VERSION "HNNBNNNYNNNNNNNNNNNNNNNNNNNNNNNNNNNNNNNNNN/4/%%%/4/'%**4NNN///"

NS_ :

BS_:

BU_: AAG BCM1 BCM2 ELV Gateway HDSG IEZS MFG MSBBR SAD SAD2 Schwerpanzer_Zusatz SitzMem_BFS SitzMem_FS SitzMem_HBFS SitzMem_HFS SitzMem_SR3 SpoilerSG TSG_BFS TSG_FS VSG VTS DK_Dummy

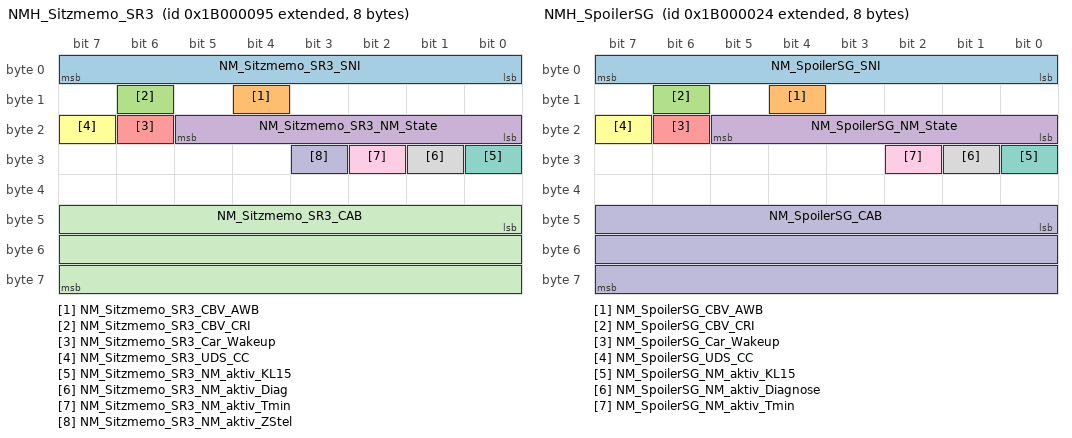
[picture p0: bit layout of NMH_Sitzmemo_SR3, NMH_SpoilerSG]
BO_ 2600468629 NMH_Sitzmemo_SR3: 8 SitzMem_SR3
 SG_ NM_Sitzmemo_SR3_SNI : 0|8@1+ (1,0) [0|255] ""  AAG,BCM1,BCM2,ELV,Gateway,HDSG,IEZS,MFG,MSBBR,SAD,SAD2,SitzMem_BFS,SitzMem_FS,SitzMem_HBFS,SitzMem_HFS,SitzMem_SR3,SpoilerSG,TSG_BFS,TSG_FS,VSG,VTS
 SG_ NM_Sitzmemo_SR3_CBV_AWB : 12|1@1+ (1,0) [0|1] ""  Gateway
 SG_ NM_Sitzmemo_SR3_CBV_CRI : 14|1@1+ (1,0) [0|1] ""  AAG,BCM1,BCM2,ELV,Gateway,HDSG,IEZS,MFG,MSBBR,SAD,SAD2,SitzMem_BFS,SitzMem_FS,SitzMem_HBFS,SitzMem_HFS,SitzMem_SR3,SpoilerSG,TSG_BFS,TSG_FS,VSG,VTS
 SG_ NM_Sitzmemo_SR3_NM_State : 16|6@1+ (1,0) [0|63] "" Vector__XXX
 SG_ NM_Sitzmemo_SR3_Car_Wakeup : 22|1@1+ (1,0) [0|1] ""  Gateway
 SG_ NM_Sitzmemo_SR3_UDS_CC : 23|1@1+ (1,0) [0|1] "" Vector__XXX
 SG_ NM_Sitzmemo_SR3_NM_aktiv_KL15 : 24|1@1+ (1,0) [0|1] "" Vector__XXX
 SG_ NM_Sitzmemo_SR3_NM_aktiv_Diag : 25|1@1+ (1,0) [0|1] "" Vector__XXX
 SG_ NM_Sitzmemo_SR3_NM_aktiv_Tmin : 26|1@1+ (1,0) [0|1] "" Vector__XXX
 SG_ NM_Sitzmemo_SR3_NM_aktiv_ZStel : 27|1@1+ (1,0) [0|1] "" Vector__XXX
 SG_ NM_Sitzmemo_SR3_CAB : 40|24@1+ (1,0) [0|16777215] ""  AAG,BCM1,BCM2,ELV,Gateway,HDSG,IEZS,MFG,MSBBR,SAD,SAD2,SitzMem_BFS,SitzMem_FS,SitzMem_HBFS,SitzMem_HFS,SitzMem_SR3,SpoilerSG,TSG_BFS,TSG_FS,VSG,VTS

BO_ 2600468516 NMH_SpoilerSG: 8 SpoilerSG
 SG_ NM_SpoilerSG_SNI : 0|8@1+ (1,0) [0|255] ""  AAG,BCM1,BCM2,ELV,Gateway,HDSG,IEZS,MFG,MSBBR,SAD,SAD2,SitzMem_BFS,SitzMem_FS,SitzMem_HBFS,SitzMem_HFS,SitzMem_SR3,SpoilerSG,TSG_BFS,TSG_FS,VSG,VTS
 SG_ NM_SpoilerSG_CBV_AWB : 12|1@1+ (1,0) [0|1] "" Vector__XXX
 SG_ NM_SpoilerSG_CBV_CRI : 14|1@1+ (1,0) [0|1] ""  AAG,BCM1,BCM2,ELV,Gateway,HDSG,IEZS,MFG,MSBBR,SAD,SAD2,SitzMem_BFS,SitzMem_FS,SitzMem_HBFS,SitzMem_HFS,SitzMem_SR3,SpoilerSG,TSG_BFS,TSG_FS,VSG,VTS
 SG_ NM_SpoilerSG_NM_State : 16|6@1+ (1,0) [0|63] "" Vector__XXX
 SG_ NM_SpoilerSG_Car_Wakeup : 22|1@1+ (1,0) [0|1] "" Vector__XXX
 SG_ NM_SpoilerSG_UDS_CC : 23|1@1+ (1,0) [0|1] "" Vector__XXX
 SG_ NM_SpoilerSG_NM_aktiv_KL15 : 24|1@1+ (1,0) [0|1] "" Vector__XXX
 SG_ NM_SpoilerSG_NM_aktiv_Diagnose : 25|1@1+ (1,0) [0|1] "" Vector__XXX
 SG_ NM_SpoilerSG_NM_aktiv_Tmin : 26|1@1+ (1,0) [0|1] "" Vector__XXX
 SG_ NM_SpoilerSG_CAB : 40|24@1+ (1,0) [0|16777215] ""  AAG,BCM1,BCM2,ELV,Gateway,HDSG,IEZS,MFG,MSBBR,SAD,SAD2,SitzMem_BFS,SitzMem_FS,SitzMem_HBFS,SitzMem_HFS,SitzMem_SR3,SpoilerSG,TSG_BFS,TSG_FS,VSG,VTS

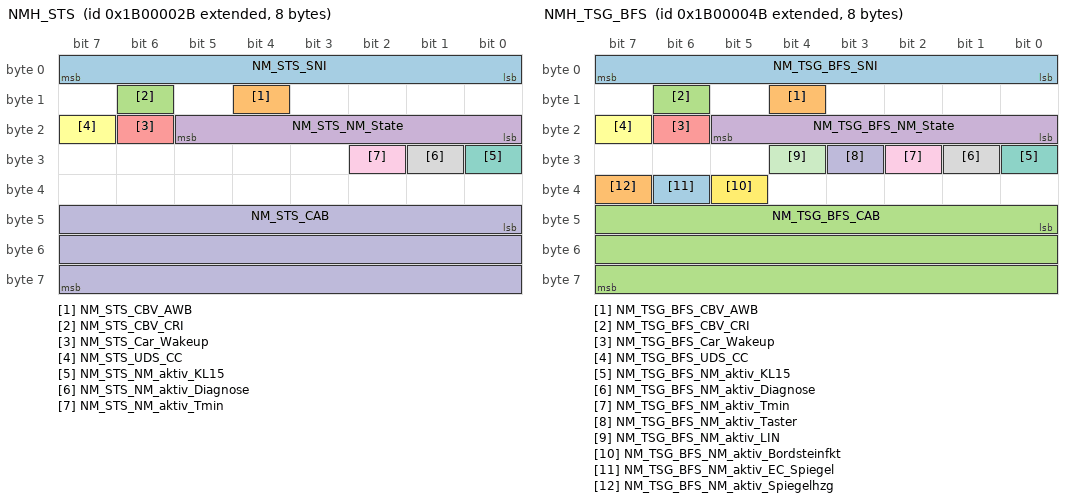
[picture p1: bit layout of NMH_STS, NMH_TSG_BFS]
BO_ 2600468523 NMH_STS: 8 VTS
 SG_ NM_STS_SNI : 0|8@1+ (1,0) [0|255] ""  AAG,BCM1,BCM2,ELV,Gateway,HDSG,IEZS,MFG,MSBBR,SAD,SAD2,SitzMem_BFS,SitzMem_FS,SitzMem_HBFS,SitzMem_HFS,SitzMem_SR3,SpoilerSG,TSG_BFS,TSG_FS,VSG,VTS
 SG_ NM_STS_CBV_AWB : 12|1@1+ (1,0) [0|1] ""  Gateway
 SG_ NM_STS_CBV_CRI : 14|1@1+ (1,0) [0|1] ""  AAG,BCM1,BCM2,ELV,Gateway,HDSG,IEZS,MFG,MSBBR,SAD,SAD2,SitzMem_BFS,SitzMem_FS,SitzMem_HBFS,SitzMem_HFS,SitzMem_SR3,SpoilerSG,TSG_BFS,TSG_FS,VSG,VTS
 SG_ NM_STS_NM_State : 16|6@1+ (1,0) [0|63] "" Vector__XXX
 SG_ NM_STS_Car_Wakeup : 22|1@1+ (1,0) [0|1] ""  Gateway
 SG_ NM_STS_UDS_CC : 23|1@1+ (1,0) [0|1] "" Vector__XXX
 SG_ NM_STS_NM_aktiv_KL15 : 24|1@1+ (1,0) [0|1] "" Vector__XXX
 SG_ NM_STS_NM_aktiv_Diagnose : 25|1@1+ (1,0) [0|1] "" Vector__XXX
 SG_ NM_STS_NM_aktiv_Tmin : 26|1@1+ (1,0) [0|1] "" Vector__XXX
 SG_ NM_STS_CAB : 40|24@1+ (1,0) [0|16777215] ""  AAG,BCM1,BCM2,ELV,Gateway,HDSG,IEZS,MFG,MSBBR,SAD,SAD2,SitzMem_BFS,SitzMem_FS,SitzMem_HBFS,SitzMem_HFS,SitzMem_SR3,SpoilerSG,TSG_BFS,TSG_FS,VSG,VTS

BO_ 2600468555 NMH_TSG_BFS: 8 TSG_BFS
 SG_ NM_TSG_BFS_SNI : 0|8@1+ (1,0) [0|255] ""  AAG,BCM1,BCM2,ELV,Gateway,HDSG,IEZS,MFG,MSBBR,SAD,SAD2,SitzMem_BFS,SitzMem_FS,SitzMem_HBFS,SitzMem_HFS,SitzMem_SR3,SpoilerSG,TSG_BFS,TSG_FS,VSG,VTS
 SG_ NM_TSG_BFS_CBV_AWB : 12|1@1+ (1,0) [0|1] ""  Gateway
 SG_ NM_TSG_BFS_CBV_CRI : 14|1@1+ (1,0) [0|1] ""  AAG,BCM1,BCM2,ELV,Gateway,HDSG,IEZS,MFG,MSBBR,SAD,SAD2,SitzMem_BFS,SitzMem_FS,SitzMem_HBFS,SitzMem_HFS,SitzMem_SR3,SpoilerSG,TSG_BFS,TSG_FS,VSG,VTS
 SG_ NM_TSG_BFS_NM_State : 16|6@1+ (1,0) [0|63] "" Vector__XXX
 SG_ NM_TSG_BFS_Car_Wakeup : 22|1@1+ (1,0) [0|1] ""  Gateway
 SG_ NM_TSG_BFS_UDS_CC : 23|1@1+ (1,0) [0|1] "" Vector__XXX
 SG_ NM_TSG_BFS_NM_aktiv_KL15 : 24|1@1+ (1,0) [0|1] "" Vector__XXX
 SG_ NM_TSG_BFS_NM_aktiv_Diagnose : 25|1@1+ (1,0) [0|1] "" Vector__XXX
 SG_ NM_TSG_BFS_NM_aktiv_Tmin : 26|1@1+ (1,0) [0|1] "" Vector__XXX
 SG_ NM_TSG_BFS_NM_aktiv_Taster : 27|1@1+ (1,0) [0|1] "" Vector__XXX
 SG_ NM_TSG_BFS_NM_aktiv_LIN : 28|1@1+ (1,0) [0|1] "" Vector__XXX
 SG_ NM_TSG_BFS_NM_aktiv_Bordsteinfkt : 37|1@1+ (1,0) [0|1] "" Vector__XXX
 SG_ NM_TSG_BFS_NM_aktiv_EC_Spiegel : 38|1@1+ (1,0) [0|1] "" Vector__XXX
 SG_ NM_TSG_BFS_NM_aktiv_Spiegelhzg : 39|1@1+ (1,0) [0|1] "" Vector__XXX
 SG_ NM_TSG_BFS_CAB : 40|24@1+ (1,0) [0|16777215] ""  AAG,BCM1,BCM2,ELV,Gateway,HDSG,IEZS,MFG,MSBBR,SAD,SAD2,SitzMem_BFS,SitzMem_FS,SitzMem_HBFS,SitzMem_HFS,SitzMem_SR3,SpoilerSG,TSG_BFS,TSG_FS,VSG,VTS

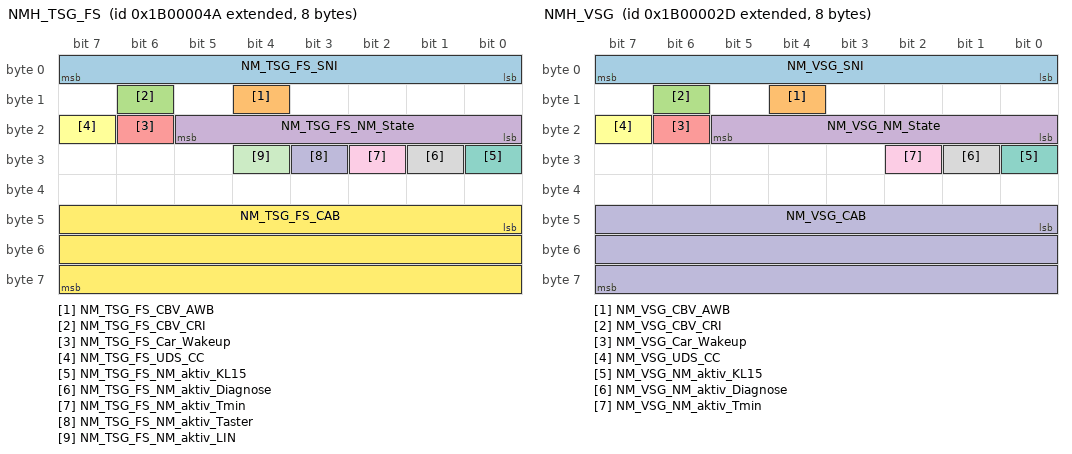
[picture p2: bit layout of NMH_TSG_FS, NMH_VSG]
BO_ 2600468554 NMH_TSG_FS: 8 TSG_FS
 SG_ NM_TSG_FS_SNI : 0|8@1+ (1,0) [0|255] ""  AAG,BCM1,BCM2,ELV,Gateway,HDSG,IEZS,MFG,MSBBR,SAD,SAD2,SitzMem_BFS,SitzMem_FS,SitzMem_HBFS,SitzMem_HFS,SitzMem_SR3,SpoilerSG,TSG_BFS,TSG_FS,VSG,VTS
 SG_ NM_TSG_FS_CBV_AWB : 12|1@1+ (1,0) [0|1] ""  Gateway
 SG_ NM_TSG_FS_CBV_CRI : 14|1@1+ (1,0) [0|1] ""  AAG,BCM1,BCM2,ELV,Gateway,HDSG,IEZS,MFG,MSBBR,SAD,SAD2,SitzMem_BFS,SitzMem_FS,SitzMem_HBFS,SitzMem_HFS,SitzMem_SR3,SpoilerSG,TSG_BFS,TSG_FS,VSG,VTS
 SG_ NM_TSG_FS_NM_State : 16|6@1+ (1,0) [0|63] "" Vector__XXX
 SG_ NM_TSG_FS_Car_Wakeup : 22|1@1+ (1,0) [0|1] ""  Gateway
 SG_ NM_TSG_FS_UDS_CC : 23|1@1+ (1,0) [0|1] "" Vector__XXX
 SG_ NM_TSG_FS_NM_aktiv_KL15 : 24|1@1+ (1,0) [0|1] "" Vector__XXX
 SG_ NM_TSG_FS_NM_aktiv_Diagnose : 25|1@1+ (1,0) [0|1] "" Vector__XXX
 SG_ NM_TSG_FS_NM_aktiv_Tmin : 26|1@1+ (1,0) [0|1] "" Vector__XXX
 SG_ NM_TSG_FS_NM_aktiv_Taster : 27|1@1+ (1,0) [0|1] "" Vector__XXX
 SG_ NM_TSG_FS_NM_aktiv_LIN : 28|1@1+ (1,0) [0|1] "" Vector__XXX
 SG_ NM_TSG_FS_CAB : 40|24@1+ (1,0) [0|16777215] ""  AAG,BCM1,BCM2,ELV,Gateway,HDSG,IEZS,MFG,MSBBR,SAD,SAD2,SitzMem_BFS,SitzMem_FS,SitzMem_HBFS,SitzMem_HFS,SitzMem_SR3,SpoilerSG,TSG_BFS,TSG_FS,VSG,VTS

BO_ 2600468525 NMH_VSG: 8 VSG
 SG_ NM_VSG_SNI : 0|8@1+ (1,0) [0|255] ""  AAG,BCM1,BCM2,ELV,Gateway,HDSG,IEZS,MFG,MSBBR,SAD,SAD2,SitzMem_BFS,SitzMem_FS,SitzMem_HBFS,SitzMem_HFS,SitzMem_SR3,SpoilerSG,TSG_BFS,TSG_FS,VSG,VTS
 SG_ NM_VSG_CBV_AWB : 12|1@1+ (1,0) [0|1] ""  Gateway
 SG_ NM_VSG_CBV_CRI : 14|1@1+ (1,0) [0|1] ""  AAG,BCM1,BCM2,ELV,Gateway,HDSG,IEZS,MFG,MSBBR,SAD,SAD2,SitzMem_BFS,SitzMem_FS,SitzMem_HBFS,SitzMem_HFS,SitzMem_SR3,SpoilerSG,TSG_BFS,TSG_FS,VSG,VTS
 SG_ NM_VSG_NM_State : 16|6@1+ (1,0) [0|63] "" Vector__XXX
 SG_ NM_VSG_Car_Wakeup : 22|1@1+ (1,0) [0|1] ""  Gateway
 SG_ NM_VSG_UDS_CC : 23|1@1+ (1,0) [0|1] "" Vector__XXX
 SG_ NM_VSG_NM_aktiv_KL15 : 24|1@1+ (1,0) [0|1] "" Vector__XXX
 SG_ NM_VSG_NM_aktiv_Diagnose : 25|1@1+ (1,0) [0|1] "" Vector__XXX
 SG_ NM_VSG_NM_aktiv_Tmin : 26|1@1+ (1,0) [0|1] "" Vector__XXX
 SG_ NM_VSG_CAB : 40|24@1+ (1,0) [0|16777215] ""  AAG,BCM1,BCM2,ELV,Gateway,HDSG,IEZS,MFG,MSBBR,SAD,SAD2,SitzMem_BFS,SitzMem_FS,SitzMem_HBFS,SitzMem_HFS,SitzMem_SR3,SpoilerSG,TSG_BFS,TSG_FS,VSG,VTS

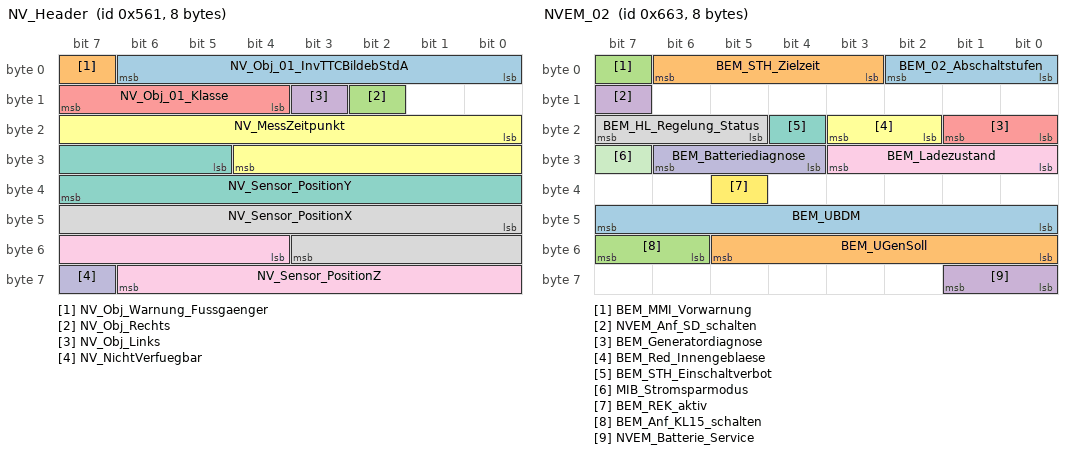
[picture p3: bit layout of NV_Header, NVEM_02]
BO_ 1377 NV_Header: 8 Gateway
 SG_ NV_Obj_01_InvTTCBildebStdA : 0|7@1+ (0.0625,0) [0|7.875] "Unit_Hertz" Vector__XXX
 SG_ NV_Obj_Warnung_Fussgaenger : 7|1@1+ (1,0) [0|1] "" Vector__XXX
 SG_ NV_Obj_Rechts : 10|1@1+ (1,0) [0|1] ""  BCM1
 SG_ NV_Obj_Links : 11|1@1+ (1,0) [0|1] ""  BCM1
 SG_ NV_Obj_01_Klasse : 12|4@1+ (1,0) [0|15] ""  BCM1
 SG_ NV_MessZeitpunkt : 16|13@1+ (0.001,0) [0|8.19] "Unit_Secon" Vector__XXX
 SG_ NV_Sensor_PositionY : 29|11@1+ (0.001,-1) [-1|1.046] "Unit_Meter" Vector__XXX
 SG_ NV_Sensor_PositionX : 40|12@1+ (0.001,1) [1|5.094] "Unit_Meter" Vector__XXX
 SG_ NV_Sensor_PositionZ : 52|11@1+ (0.001,0) [0|2.046] "Unit_Meter" Vector__XXX
 SG_ NV_NichtVerfuegbar : 63|1@1+ (1,0) [0|1] "" Vector__XXX

BO_ 1635 NVEM_02: 8 Gateway
 SG_ BEM_02_Abschaltstufen : 0|3@1+ (1,0) [0|7] ""  AAG,BCM1,BCM2,HDSG,IEZS,MFG,SAD,SAD2,SitzMem_BFS,SitzMem_FS,SitzMem_HBFS,SitzMem_HFS,SitzMem_SR3,SpoilerSG,TSG_BFS,TSG_FS,VSG,VTS
 SG_ BEM_STH_Zielzeit : 3|4@1+ (5,0) [0|60] "Unit_Minut" Vector__XXX
 SG_ BEM_MMI_Vorwarnung : 7|1@1+ (1,0) [0|1] "" Vector__XXX
 SG_ NVEM_Anf_SD_schalten : 15|1@1+ (1,0) [0|1] ""  BCM1
 SG_ BEM_Generatordiagnose : 16|2@1+ (1,0) [0|3] ""  MFG
 SG_ BEM_Red_Innengeblaese : 18|2@1+ (1,0) [0|3] ""  MFG
 SG_ BEM_STH_Einschaltverbot : 20|1@1+ (1,0) [0|1] ""  VTS
 SG_ BEM_HL_Regelung_Status : 21|3@1+ (1,0) [0|7] ""  AAG,BCM1
 SG_ BEM_Ladezustand : 24|4@1+ (10,0) [0|100] "Unit_PerCent" Vector__XXX
 SG_ BEM_Batteriediagnose : 28|3@1+ (1,0) [0|7] "" Vector__XXX
 SG_ MIB_Stromsparmodus : 31|1@1+ (1,0) [0|1] "" Vector__XXX
 SG_ BEM_REK_aktiv : 37|1@1+ (1,0) [0|1] "" Vector__XXX
 SG_ BEM_UBDM : 40|8@1+ (0.05,5) [5.05|17.7] "Unit_Volt"  BCM2
 SG_ BEM_UGenSoll : 48|6@1+ (0.1,10.6) [10.6|16] "Unit_Volt" Vector__XXX
 SG_ BEM_Anf_KL15_schalten : 54|2@1+ (1,0) [0|3] ""  BCM2
 SG_ NVEM_Batterie_Service : 56|2@1+ (1,0) [0|3] "" Vector__XXX

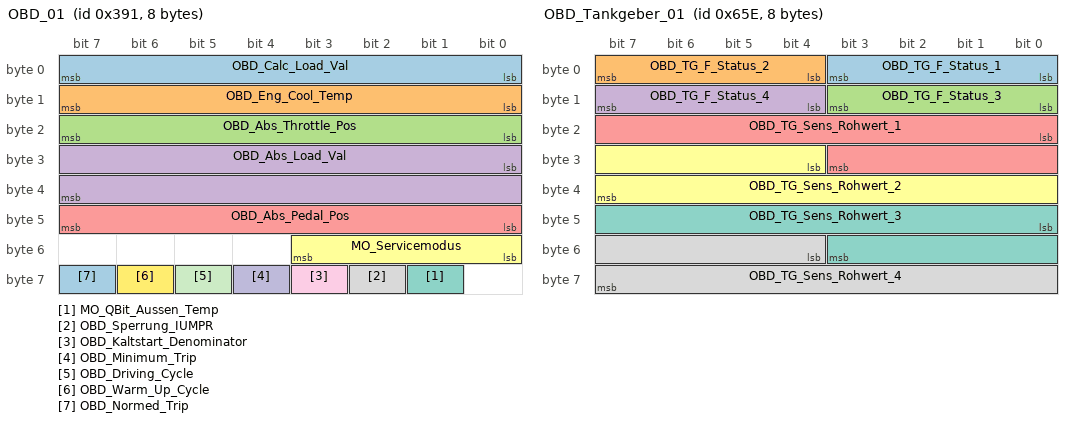
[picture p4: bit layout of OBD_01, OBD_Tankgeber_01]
BO_ 913 OBD_01: 8 Gateway
 SG_ OBD_Calc_Load_Val : 0|8@1+ (0.392156862745098,0) [0|100] "Unit_PerCent" Vector__XXX
 SG_ OBD_Eng_Cool_Temp : 8|8@1+ (1,-40) [-40|215] "Unit_DegreCelsi" Vector__XXX
 SG_ OBD_Abs_Throttle_Pos : 16|8@1+ (0.392156862745098,0) [0|100] "Unit_PerCent" Vector__XXX
 SG_ OBD_Abs_Load_Val : 24|16@1+ (0.392156862745098,0) [0|25700] "Unit_PerCent" Vector__XXX
 SG_ OBD_Abs_Pedal_Pos : 40|8@1+ (0.392156862745098,0) [0|100] "Unit_PerCent" Vector__XXX
 SG_ MO_Servicemodus : 48|4@1+ (1,0) [0|15] "" Vector__XXX
 SG_ MO_QBit_Aussen_Temp : 57|1@1+ (1,0) [0|1] "" Vector__XXX
 SG_ OBD_Sperrung_IUMPR : 58|1@1+ (1,0) [0|1] "" Vector__XXX
 SG_ OBD_Kaltstart_Denominator : 59|1@1+ (1,0) [0|1] "" Vector__XXX
 SG_ OBD_Minimum_Trip : 60|1@1+ (1,0) [0|1] "" Vector__XXX
 SG_ OBD_Driving_Cycle : 61|1@1+ (1,0) [0|1] "" Vector__XXX
 SG_ OBD_Warm_Up_Cycle : 62|1@1+ (1,0) [0|1] "" Vector__XXX
 SG_ OBD_Normed_Trip : 63|1@1+ (1,0) [0|1] "" Vector__XXX

BO_ 1630 OBD_Tankgeber_01: 8 BCM2
 SG_ OBD_TG_F_Status_1 : 0|4@1+ (1,0) [0|15] ""  Gateway
 SG_ OBD_TG_F_Status_2 : 4|4@1+ (1,0) [0|15] ""  Gateway
 SG_ OBD_TG_F_Status_3 : 8|4@1+ (1,0) [0|15] ""  Gateway
 SG_ OBD_TG_F_Status_4 : 12|4@1+ (1,0) [0|15] ""  Gateway
 SG_ OBD_TG_Sens_Rohwert_1 : 16|12@1+ (0.5,0) [0|2047.5] "Unit_Ohm"  Gateway
 SG_ OBD_TG_Sens_Rohwert_2 : 28|12@1+ (0.5,0) [0|2047.5] "Unit_Ohm"  Gateway
 SG_ OBD_TG_Sens_Rohwert_3 : 40|12@1+ (0.5,0) [0|2047.5] "Unit_Ohm"  Gateway
 SG_ OBD_TG_Sens_Rohwert_4 : 52|12@1+ (0.5,0) [0|2047.5] "Unit_Ohm"  Gateway

BO_ 2549875271 OBDC_AAG_Req: 8 Gateway
 SG_ OBDC_AAG_Req_Data : 0|64@1+ (1,0) [0|1.84467440737096E+019] ""  AAG

BO_ 2550006343 OBDC_AAG_Resp: 8 AAG
 SG_ OBDC_AAG_Resp_Data : 0|64@1+ (1,0) [0|1.84467440737096E+019] ""  Gateway

BO_ 2549875214 OBDC_BCM1_Req: 8 Gateway
 SG_ OBDC_BCM1_Req_Data : 0|64@1+ (1,0) [0|1.84467440737096E+019] ""  BCM1

BO_ 2550006286 OBDC_BCM1_Resp: 8 BCM1
 SG_ OBDC_BCM1_Resp_Data : 0|64@1+ (1,0) [0|1.84467440737096E+019] ""  Gateway

BO_ 2549875339 OBDC_BCM2_Req: 8 Gateway
 SG_ OBDC_BCM2_Req_Data : 0|64@1+ (1,0) [0|1.84467440737096E+019] ""  BCM2

BO_ 2550006411 OBDC_BCM2_Resp: 8 BCM2
 SG_ OBDC_BCM2_Resp_Data : 0|64@1+ (1,0) [0|1.84467440737096E+019] ""  Gateway

BO_ 2549875249 OBDC_ELV_Req: 8 Gateway
 SG_ OBDC_ELV_Req_Data : 0|64@1+ (1,0) [0|1.84467440737096E+019] ""  ELV

BO_ 2550006321 OBDC_ELV_Resp: 8 ELV
 SG_ OBDC_ELV_Resp_Data : 0|64@1+ (1,0) [0|1.84467440737096E+019] ""  Gateway

BO_ 2549875235 OBDC_HDSG_Req: 8 Gateway
 SG_ OBDC_HDSG_Req_Data : 0|64@1+ (1,0) [0|1.84467440737096E+019] ""  HDSG

BO_ 2550006307 OBDC_HDSG_Resp: 8 HDSG
 SG_ OBDC_HDSG_Resp_Data : 0|64@1+ (1,0) [0|1.84467440737096E+019] ""  Gateway

BO_ 2549875250 OBDC_Kessy_Req: 8 Gateway
 SG_ OBDC_Kessy_Req_Data : 0|64@1+ (1,0) [0|1.84467440737096E+019] ""  IEZS

BO_ 2550006322 OBDC_Kessy_Resp: 8 IEZS
 SG_ OBDC_Kessy_Resp_Data : 0|64@1+ (1,0) [0|1.84467440737096E+019] ""  Gateway

BO_ 2549875330 OBDC_LCM_L_Req: 8 Gateway
 SG_ OBDC_LCM_L_Req_Data : 0|64@1+ (1,0) [0|1.84467440737096E+019] ""  BCM1

BO_ 2550006402 OBDC_LCM_L_Resp: 8 BCM1
 SG_ OBDC_LCM_L_Resp_Data : 0|64@1+ (1,0) [0|1.84467440737096E+019] ""  Gateway

BO_ 2549875331 OBDC_LCM_R_Req: 8 Gateway
 SG_ OBDC_LCM_R_Req_Data : 0|64@1+ (1,0) [0|1.84467440737096E+019] ""  BCM1

BO_ 2550006403 OBDC_LCM_R_Resp: 8 BCM1
 SG_ OBDC_LCM_R_Resp_Data : 0|64@1+ (1,0) [0|1.84467440737096E+019] ""  Gateway

BO_ 2549875350 OBDC_LED_LM_L_Req: 8 Gateway
 SG_ OBDC_LED_LM_L_Req_Data : 0|64@1+ (1,0) [0|1.84467440737096E+019] ""  BCM1

BO_ 2550006422 OBDC_LED_LM_L_Resp: 8 BCM1
 SG_ OBDC_LED_LM_L_Resp_Data : 0|64@1+ (1,0) [0|1.84467440737096E+019] ""  Gateway

BO_ 2549875351 OBDC_LED_LM_R_Req: 8 Gateway
 SG_ OBDC_LED_LM_R_Req_Data : 0|64@1+ (1,0) [0|1.84467440737096E+019] ""  BCM1

BO_ 2550006423 OBDC_LED_LM_R_Resp: 8 BCM1
 SG_ OBDC_LED_LM_R_Resp_Data : 0|64@1+ (1,0) [0|1.84467440737096E+019] ""  Gateway

BO_ 2549875244 OBDC_MFG_Req: 8 Gateway
 SG_ OBDC_MFG_Req_Data : 0|64@1+ (1,0) [0|1.84467440737096E+019] ""  MFG

BO_ 2550006316 OBDC_MFG_Resp: 8 MFG
 SG_ OBDC_MFG_Resp_Data : 0|64@1+ (1,0) [0|1.84467440737096E+019] ""  Gateway

BO_ 2549875360 OBDC_SAD2_Req: 8 Gateway
 SG_ OBDC_SAD2_Req_Data : 0|64@1+ (1,0) [0|1.84467440737096E+019] ""  SAD2

BO_ 2550006432 OBDC_SAD2_Resp: 8 SAD2
 SG_ OBDC_SAD2_Resp_Data : 0|64@1+ (1,0) [0|1.84467440737096E+019] ""  Gateway

BO_ 2549875332 OBDC_SAD_Req: 8 Gateway
 SG_ OBDC_SAD_Req_Data : 0|64@1+ (1,0) [0|1.84467440737096E+019] ""  SAD

BO_ 2550006404 OBDC_SAD_Resp: 8 SAD
 SG_ OBDC_SAD_Resp_Data : 0|64@1+ (1,0) [0|1.84467440737096E+019] ""  Gateway

BO_ 2549875355 OBDC_SBBR_Req: 8 Gateway
 SG_ OBDC_MSBBR_Req_Data : 0|64@1+ (1,0) [0|1.84467440737096E+019] ""  MSBBR

BO_ 2550006427 OBDC_SBBR_Resp: 8 MSBBR
 SG_ OBDC_MSBBR_Resp_Data : 0|64@1+ (1,0) [0|1.84467440737096E+019] ""  Gateway

BO_ 2549875277 OBDC_Sitzmemo_BFS_Req: 8 Gateway
 SG_ OBDC_Sitzmemo_BFS_Req_Data : 0|64@1+ (1,0) [0|1.84467440737096E+019] ""  SitzMem_BFS

BO_ 2550006349 OBDC_Sitzmemo_BFS_Resp: 8 SitzMem_BFS
 SG_ OBDC_Sitzmemo_BFS_Resp_Data : 0|64@1+ (1,0) [0|1.84467440737096E+019] ""  Gateway

BO_ 2549875276 OBDC_Sitzmemo_FS_Req: 8 Gateway
 SG_ OBDC_Sitzmemo_FS_Req_Data : 0|64@1+ (1,0) [0|1.84467440737096E+019] ""  SitzMem_FS

BO_ 2550006348 OBDC_Sitzmemo_FS_Resp: 8 SitzMem_FS
 SG_ OBDC_Sitzmemo_FS_Resp_Data : 0|64@1+ (1,0) [0|1.84467440737096E+019] ""  Gateway

BO_ 2549875336 OBDC_Sitzmemo_HBFS_Req: 8 Gateway
 SG_ OBDC_Sitzmemo_HBFS_Req_Data : 0|64@1+ (1,0) [0|1.84467440737096E+019] ""  SitzMem_HBFS

BO_ 2550006408 OBDC_Sitzmemo_HBFS_Resp: 8 SitzMem_HBFS
 SG_ OBDC_Sitzmemo_HBFS_Resp_Data : 0|64@1+ (1,0) [0|1.84467440737096E+019] ""  Gateway

BO_ 2549875335 OBDC_Sitzmemo_HFS_Req: 8 Gateway
 SG_ OBDC_Sitzmemo_HFS_Req_Data : 0|64@1+ (1,0) [0|1.84467440737096E+019] ""  SitzMem_HFS

BO_ 2550006407 OBDC_Sitzmemo_HFS_Resp: 8 SitzMem_HFS
 SG_ OBDC_Sitzmemo_HFS_Resp_Data : 0|64@1+ (1,0) [0|1.84467440737096E+019] ""  Gateway

BO_ 2549875349 OBDC_Sitzmemo_SR3_Req: 8 Gateway
 SG_ OBDC_Sitzmemo_SR3_Req_Data : 0|64@1+ (1,0) [0|1.84467440737096E+019] ""  SitzMem_SR3

BO_ 2550006421 OBDC_Sitzmemo_SR3_Resp: 8 SitzMem_SR3
 SG_ OBDC_Sitzmemo_SR3_Resp_Data : 0|64@1+ (1,0) [0|1.84467440737096E+019] ""  Gateway

BO_ 2549875236 OBDC_SpoilerSG_Req: 8 Gateway
 SG_ OBDC_SpoilerSG_Req_Data : 0|64@1+ (1,0) [0|1.84467440737096E+019] ""  SpoilerSG

BO_ 2550006308 OBDC_SpoilerSG_Resp: 8 SpoilerSG
 SG_ OBDC_SpoilerSG_Resp_Data : 0|64@1+ (1,0) [0|1.84467440737096E+019] ""  Gateway

BO_ 2549875243 OBDC_STS_Req: 8 Gateway
 SG_ OBDC_STS_Req_Data : 0|64@1+ (1,0) [0|1.84467440737096E+019] ""  VTS

BO_ 2550006315 OBDC_STS_Resp: 8 VTS
 SG_ OBDC_STS_Resp_Data : 0|64@1+ (1,0) [0|1.84467440737096E+019] ""  Gateway

BO_ 2549875275 OBDC_TSG_BT_Req: 8 Gateway
 SG_ OBDC_TSG_BT_Req_Data : 0|64@1+ (1,0) [0|1.84467440737096E+019] ""  TSG_BFS

BO_ 2550006347 OBDC_TSG_BT_Resp: 8 TSG_BFS
 SG_ OBDC_TSG_BT_Resp_Data : 0|64@1+ (1,0) [0|1.84467440737096E+019] ""  Gateway

BO_ 2549875274 OBDC_TSG_FT_Req: 8 Gateway
 SG_ OBDC_TSG_FT_Req_Data : 0|64@1+ (1,0) [0|1.84467440737096E+019] ""  TSG_FS

BO_ 2550006346 OBDC_TSG_FT_Resp: 8 TSG_FS
 SG_ OBDC_TSG_FT_Resp_Data : 0|64@1+ (1,0) [0|1.84467440737096E+019] ""  Gateway

BO_ 2549875263 OBDC_TSG_HBFS_Req: 8 Gateway
 SG_ OBDC_TSG_HBFS_Req_Data : 0|64@1+ (1,0) [0|1.84467440737096E+019] ""  TSG_BFS

BO_ 2550006335 OBDC_TSG_HBFS_Resp: 8 TSG_BFS
 SG_ OBDC_TSG_HBFS_Resp_Data : 0|64@1+ (1,0) [0|1.84467440737096E+019] ""  Gateway

BO_ 2549875262 OBDC_TSG_HFS_Req: 8 Gateway
 SG_ OBDC_TSG_HFS_Req_Data : 0|64@1+ (1,0) [0|1.84467440737096E+019] ""  TSG_FS

BO_ 2550006334 OBDC_TSG_HFS_Resp: 8 TSG_FS
 SG_ OBDC_TSG_HFS_Resp_Data : 0|64@1+ (1,0) [0|1.84467440737096E+019] ""  Gateway

BO_ 2549875245 OBDC_VSG_Req: 8 Gateway
 SG_ OBDC_VSG_Req_Data : 0|64@1+ (1,0) [0|1.84467440737096E+019] ""  VSG

BO_ 2550006317 OBDC_VSG_Resp: 8 VSG
 SG_ OBDC_VSG_Resp_Data : 0|64@1+ (1,0) [0|1.84467440737096E+019] ""  Gateway

BO_ 872 Parkhilfe2_01: 8 Gateway
 SG_ PH2_Visualisierung : 0|3@1+ (1,0) [0|7] ""  BCM1
 SG_ PH2_nachtr_Stopp_An : 12|1@1+ (1,0) [0|1] "" Vector__XXX
 SG_ PH2_Abschaltursache : 13|3@1+ (1,0) [0|7] ""  BCM1
 SG_ PH2_Opt_Anzeige_V_ein : 16|1@1+ (1,0) [0|1] ""  BCM1
 SG_ PH2_Opt_Anzeige_H_ein : 17|1@1+ (1,0) [0|1] ""  BCM1
 SG_ PH2_Opt_Anz_V_Hindernis : 18|1@1+ (1,0) [0|1] ""  BCM1
 SG_ PH2_Opt_Anz_H_Hindernis : 19|1@1+ (1,0) [0|1] ""  BCM1
 SG_ PH2_Tongeber_V_aktiv : 20|1@1+ (1,0) [0|1] "" Vector__XXX
 SG_ PH2_Tongeber_H_aktiv : 21|1@1+ (1,0) [0|1] "" Vector__XXX
 SG_ PH2_Tongeber_mute : 22|1@1+ (1,0) [0|1] "" Vector__XXX
 SG_ PH2_Anf_Audioabsenkung : 23|1@1+ (1,0) [0|1] "" Vector__XXX
 SG_ PH2_Tongeber_H_verfuegbar : 24|1@1+ (1,0) [0|1] "" Vector__XXX
 SG_ PH2_Taster : 28|2@1+ (1,0) [0|3] "" Vector__XXX
 SG_ PH2_Anf_Verdeck : 30|2@1+ (1,0) [0|3] "" Vector__XXX
 SG_ PH2_Frequenz_hinten : 32|4@1+ (1,0) [0|15] "" Vector__XXX
 SG_ PH2_Lautstaerke_hinten : 36|4@1+ (1,0) [0|15] "" Vector__XXX
 SG_ PH2_Frequenz_vorn : 40|4@1+ (1,0) [0|15] "" Vector__XXX
 SG_ PH2_Lautstaerke_vorn : 44|4@1+ (1,0) [0|15] "" Vector__XXX
 SG_ PH2_StartStopp_Info : 49|2@1+ (1,0) [0|3] "" Vector__XXX
 SG_ PH2_Stoermeldung : 52|4@1+ (1,0) [0|15] "" Vector__XXX
 SG_ PH2_defekt : 56|1@1+ (1,0) [0|1] "" Vector__XXX
 SG_ PH2_gestoert : 57|1@1+ (1,0) [0|1] "" Vector__XXX
 SG_ PH2_Systemzustand : 58|3@1+ (1,0) [0|7] ""  AAG,BCM1
 SG_ PH2_Display_Kundenwunsch : 61|2@1+ (1,0) [0|3] "" Vector__XXX
 SG_ APS2_Tongeber_defekt : 63|1@1+ (1,0) [0|1] "" Vector__XXX

BO_ 1175 Parkhilfe_01: 8 BCM1
 SG_ PH_Visualisierung : 0|3@1+ (1,0) [0|7] ""  BCM1,Gateway
 SG_ PDC_Tonausgabe_Front : 4|4@1+ (1,0) [0|15] ""  Gateway
 SG_ PDC_Tonausgabe_Heck : 8|4@1+ (1,0) [0|15] ""  Gateway
 SG_ PH_nachtr_Stopp_Anf : 12|1@1+ (1,0) [0|1] ""  Gateway
 SG_ PH_Abschaltursache : 13|3@1+ (1,0) [0|7] ""  Gateway
 SG_ PH_Opt_Anzeige_V_ein : 16|1@1+ (1,0) [0|1] ""  Gateway
 SG_ PH_Opt_Anzeige_H_ein : 17|1@1+ (1,0) [0|1] ""  Gateway
 SG_ PH_Opt_Anz_V_Hindernis : 18|1@1+ (1,0) [0|1] ""  Gateway
 SG_ PH_Opt_Anz_H_Hindernis : 19|1@1+ (1,0) [0|1] ""  Gateway
 SG_ PH_Tongeber_V_aktiv : 20|1@1+ (1,0) [0|1] ""  Gateway
 SG_ PH_Tongeber_H_aktiv : 21|1@1+ (1,0) [0|1] ""  Gateway
 SG_ PH_Tongeber_mute : 22|1@1+ (1,0) [0|1] ""  Gateway
 SG_ PH_Anf_Audioabsenkung : 23|1@1+ (1,0) [0|1] ""  Gateway
 SG_ PH_Tongeber_H_verfuegbar : 24|1@1+ (1,0) [0|1] ""  Gateway
 SG_ PLA_Anf_Aufschaltung_RVC : 25|1@1+ (1,0) [0|1] ""  Gateway
 SG_ PH_Taster : 28|2@1+ (1,0) [0|3] ""  Gateway
 SG_ PH_Anf_Verdeck : 30|2@1+ (1,0) [0|3] ""  Gateway
 SG_ PH_Frequenz_hinten : 32|4@1+ (1,0) [0|15] ""  Gateway
 SG_ PH_Lautstaerke_hinten : 36|4@1+ (1,0) [0|15] ""  Gateway
 SG_ PH_Frequenz_vorn : 40|4@1+ (1,0) [0|15] ""  Gateway
 SG_ PH_Lautstaerke_vorn : 44|4@1+ (1,0) [0|15] ""  Gateway
 SG_ PH_StartStopp_Info : 49|2@1+ (1,0) [0|3] ""  Gateway
 SG_ PH_Stoermeldung : 52|4@1+ (1,0) [0|15] ""  Gateway
 SG_ PH_defekt : 56|1@1+ (1,0) [0|1] ""  Gateway
 SG_ PH_gestoert : 57|1@1+ (1,0) [0|1] ""  Gateway
 SG_ PH_Systemzustand : 58|3@1+ (1,0) [0|7] ""  AAG,Gateway
 SG_ PH_Display_Kundenwunsch : 61|2@1+ (1,0) [0|3] ""  Gateway

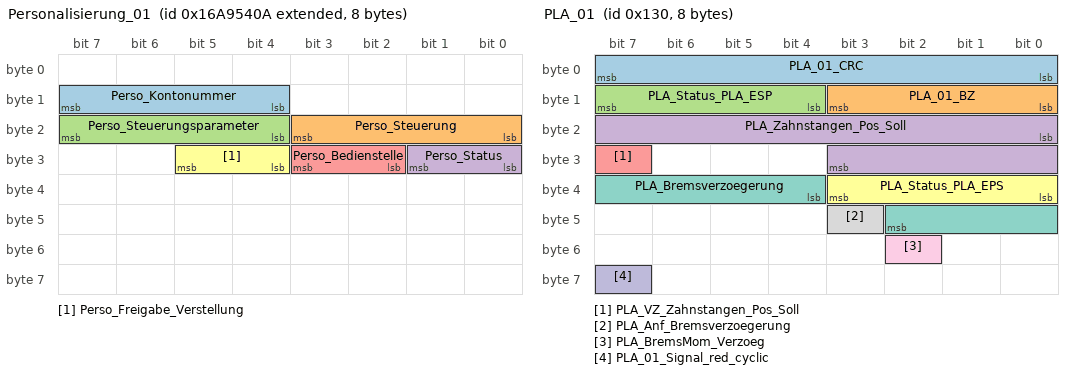
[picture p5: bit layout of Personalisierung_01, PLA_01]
BO_ 2527679498 Personalisierung_01: 8 BCM2
 SG_ Perso_Kontonummer : 12|4@1+ (1,0) [0|15] ""  BCM1,Gateway,TSG_BFS,TSG_FS
 SG_ Perso_Steuerung : 16|4@1+ (1,0) [0|15] ""  BCM1,Gateway,TSG_BFS,TSG_FS
 SG_ Perso_Steuerungsparameter : 20|4@1+ (1,0) [0|15] ""  BCM1,Gateway,TSG_BFS,TSG_FS
 SG_ Perso_Status : 24|2@1+ (1,0) [0|3] ""  BCM1,Gateway,TSG_BFS,TSG_FS
 SG_ Perso_Bedienstelle : 26|2@1+ (1,0) [0|3] ""  Gateway,SitzMem_FS
 SG_ Perso_Freigabe_Verstellung : 28|2@1+ (1,0) [0|3] ""  Gateway,SitzMem_FS

BO_ 304 PLA_01: 8 BCM1
 SG_ PLA_01_CRC : 0|8@1+ (1,0) [0|255] ""  Gateway
 SG_ PLA_01_BZ : 8|4@1+ (1,0) [0|15] ""  Gateway
 SG_ PLA_Status_PLA_ESP : 12|4@1+ (1,0) [0|15] ""  Gateway
 SG_ PLA_Zahnstangen_Pos_Soll : 16|12@1+ (0.02,0) [0|81.86] "Unit_MilliMeter"  Gateway
 SG_ PLA_VZ_Zahnstangen_Pos_Soll : 31|1@1+ (1,0) [0|1] ""  Gateway
 SG_ PLA_Status_PLA_EPS : 32|4@1+ (1,0) [0|15] ""  Gateway
 SG_ PLA_Bremsverzoegerung : 36|7@1+ (0.1,0) [0|12] "Unit_MeterPerSeconSquar"  Gateway
 SG_ PLA_Anf_Bremsverzoegerung : 43|1@1+ (1,0) [0|1] ""  Gateway
 SG_ PLA_BremsMom_Verzoeg : 50|1@1+ (1,0) [0|1] ""  Gateway
 SG_ PLA_01_Signal_red_cyclic : 63|1@1+ (1,0) [0|1] ""  Gateway

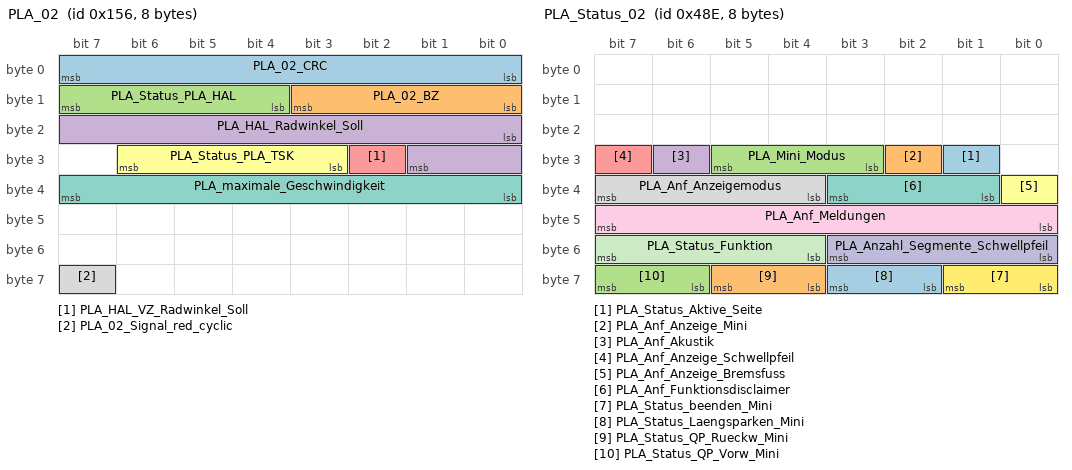
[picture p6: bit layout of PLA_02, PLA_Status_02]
BO_ 342 PLA_02: 8 BCM1
 SG_ PLA_02_CRC : 0|8@1+ (1,0) [0|255] ""  Gateway
 SG_ PLA_02_BZ : 8|4@1+ (1,0) [0|15] ""  Gateway
 SG_ PLA_Status_PLA_HAL : 12|4@1+ (1,0) [0|15] ""  Gateway
 SG_ PLA_HAL_Radwinkel_Soll : 16|10@1+ (0.01,0) [0|10.19] "Unit_DegreOfArc"  Gateway
 SG_ PLA_HAL_VZ_Radwinkel_Soll : 26|1@1+ (1,0) [0|1] ""  Gateway
 SG_ PLA_Status_PLA_TSK : 27|4@1+ (1,0) [0|15] ""  Gateway
 SG_ PLA_maximale_Geschwindigkeit : 32|8@1+ (0.1,0) [0.1|25] "Unit_KiloMeterPerHour"  Gateway
 SG_ PLA_02_Signal_red_cyclic : 63|1@1+ (1,0) [0|1] ""  Gateway

BO_ 1166 PLA_Status_02: 8 BCM1
 SG_ PLA_Status_Aktive_Seite : 25|1@1+ (1,0) [0|1] ""  Gateway
 SG_ PLA_Anf_Anzeige_Mini : 26|1@1+ (1,0) [0|1] ""  Gateway
 SG_ PLA_Mini_Modus : 27|3@1+ (1,0) [0|7] ""  Gateway
 SG_ PLA_Anf_Akustik : 30|1@1+ (1,0) [0|1] ""  Gateway
 SG_ PLA_Anf_Anzeige_Schwellpfeil : 31|1@1+ (1,0) [0|1] ""  Gateway
 SG_ PLA_Anf_Anzeige_Bremsfuss : 32|1@1+ (1,0) [0|1] ""  Gateway
 SG_ PLA_Anf_Funktionsdisclaimer : 33|3@1+ (1,0) [0|7] ""  Gateway
 SG_ PLA_Anf_Anzeigemodus : 36|4@1+ (1,0) [0|15] ""  Gateway
 SG_ PLA_Anf_Meldungen : 40|8@1+ (1,0) [0|255] ""  Gateway
 SG_ PLA_Anzahl_Segmente_Schwellpfeil : 48|4@1+ (1,0) [0|15] ""  Gateway
 SG_ PLA_Status_Funktion : 52|4@1+ (1,0) [0|15] ""  Gateway
 SG_ PLA_Status_beenden_Mini : 56|2@1+ (1,0) [0|3] ""  Gateway
 SG_ PLA_Status_Laengsparken_Mini : 58|2@1+ (1,0) [0|3] ""  Gateway
 SG_ PLA_Status_QP_Rueckw_Mini : 60|2@1+ (1,0) [0|3] ""  Gateway
 SG_ PLA_Status_QP_Vorw_Mini : 62|2@1+ (1,0) [0|3] ""  Gateway

BO_ 319 PreCrash_02: 8 Gateway
 SG_ PreCrash_Charisma_FahrPr : 12|4@1+ (1,0) [0|15] "" Vector__XXX
 SG_ PreCrash_Charisma_Status : 16|2@1+ (1,0) [0|3] "" Vector__XXX
 SG_ PreCrash_Schiebedach_schliessen : 18|1@1+ (1,0) [0|1] ""  SAD,SAD2
 SG_ PreCrash_Fenster_schliessen : 19|1@1+ (1,0) [0|1] ""  TSG_BFS,TSG_FS
 SG_ PreCrash_Blinken : 20|3@1+ (1,0) [0|7] ""  BCM2
 SG_ SC_PreCrash_LED : 29|2@1+ (1,0) [0|3] "" Vector__XXX
 SG_ PreCrash_FS_Pneumatik_ansteuern : 31|1@1+ (1,0) [0|1] ""  BCM1,SitzMem_FS
 SG_ PreCrash_BFS_Pneumatik_ansteuern : 32|1@1+ (1,0) [0|1] ""  BCM1,SitzMem_BFS
 SG_ PreCrash_Fo_Pneumatik_ansteuern : 33|1@1+ (1,0) [0|1] ""  SitzMem_HBFS,SitzMem_HFS
 SG_ PreCrash_FS_Sitzlehne_verfahren : 34|3@1+ (1,0) [0|7] ""  SitzMem_FS
 SG_ PreCrash_BFS_Sitzlehne_verfahren : 37|3@1+ (1,0) [0|7] ""  SitzMem_BFS
 SG_ PreCrash_Fo_Sitzlehne_verfahren : 40|3@1+ (1,0) [0|7] ""  SitzMem_HBFS,SitzMem_HFS
 SG_ PreCrash_FS_KSV_verfahren : 43|4@1+ (1,0) [0|15] ""  SitzMem_FS
 SG_ PreCrash_BFS_KSV_verfahren : 47|4@1+ (1,0) [0|15] ""  SitzMem_BFS
 SG_ PreCrash_Fo_KSV_verfahren : 51|4@1+ (1,0) [0|15] ""  SitzMem_HBFS,SitzMem_HFS
 SG_ SC_PreCrash_Warnung : 56|4@1+ (1,0) [0|15] "" Vector__XXX
 SG_ SC_PreCrash_Texte : 60|4@1+ (1,0) [0|15] "" Vector__XXX

BO_ 1122 PSD_04: 8 Gateway
 SG_ PSD_Segment_ID : 0|6@1+ (1,0) [2|63] ""  BCM1
 SG_ PSD_Vorgaenger_Segment_ID : 6|6@1+ (1,0) [2|63] ""  BCM1
 SG_ PSD_Segmentlaenge : 12|7@1+ (2,0) [0|254] "Unit_Meter"  BCM1
 SG_ PSD_Strassenkategorie : 19|3@1+ (1,0) [0|7] ""  BCM1
 SG_ PSD_Endkruemmung : 22|8@1+ (1,0) [0|254] "Unit_None"  BCM1
 SG_ PSD_Endkruemmung_Vorz : 30|1@1+ (1,0) [0|1] ""  BCM1
 SG_ PSD_Idenditaets_ID : 31|6@1+ (1,0) [2|63] ""  BCM1
 SG_ PSD_ADAS_Qualitaet : 37|1@1+ (1,0) [0|1] ""  BCM1
 SG_ PSD_wahrscheinlichster_Pfad : 38|1@1+ (1,0) [0|1] ""  BCM1
 SG_ PSD_Geradester_Pfad : 39|1@1+ (1,0) [0|1] ""  BCM1
 SG_ PSD_Fahrspuren_Anzahl : 40|3@1+ (1,0) [0|7] ""  BCM1
 SG_ PSD_Bebauung : 43|1@1+ (1,0) [0|1] ""  BCM1
 SG_ PSD_Segment_Komplett : 44|1@1+ (1,0) [0|1] ""  BCM1
 SG_ PSD_Rampe : 45|2@1+ (1,0) [0|3] ""  BCM1
 SG_ PSD_Anfangskruemmung : 47|8@1+ (1,0) [0|254] ""  BCM1
 SG_ PSD_Anfangskruemmung_Vorz : 55|1@1+ (1,0) [0|1] ""  BCM1
 SG_ PSD_Abzweigerichtung : 56|1@1+ (1,0) [0|1] ""  BCM1
 SG_ PSD_Abzweigewinkel : 57|7@1+ (1.417323,0) [0|180.000021] ""  BCM1

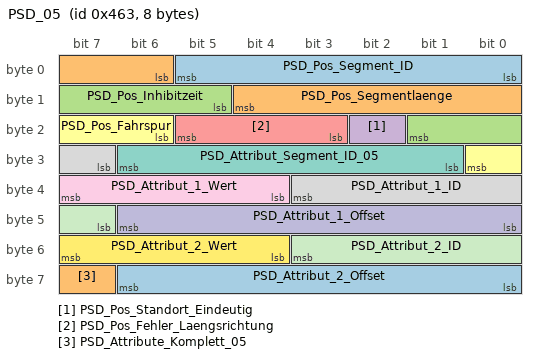
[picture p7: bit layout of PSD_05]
BO_ 1123 PSD_05: 8 Gateway
 SG_ PSD_Pos_Segment_ID : 0|6@1+ (1,0) [2|63] ""  BCM1
 SG_ PSD_Pos_Segmentlaenge : 6|7@1+ (2,0) [0|254] "Unit_Meter"  BCM1
 SG_ PSD_Pos_Inhibitzeit : 13|5@1+ (10,0) [0|310] "Unit_MilliSecon"  BCM1
 SG_ PSD_Pos_Standort_Eindeutig : 18|1@1+ (1,0) [0|1] ""  BCM1
 SG_ PSD_Pos_Fehler_Laengsrichtung : 19|3@1+ (1,0) [0|7] ""  BCM1
 SG_ PSD_Pos_Fahrspur : 22|3@1+ (1,0) [0|7] ""  BCM1
 SG_ PSD_Attribut_Segment_ID_05 : 25|6@1+ (1,0) [2|63] ""  BCM1
 SG_ PSD_Attribut_1_ID : 31|5@1+ (1,0) [1|31] ""  BCM1
 SG_ PSD_Attribut_1_Wert : 36|4@1+ (1,0) [0|15] ""  BCM1
 SG_ PSD_Attribut_1_Offset : 40|7@1+ (2,0) [0|254] "Unit_Meter"  BCM1
 SG_ PSD_Attribut_2_ID : 47|5@1+ (1,0) [1|31] ""  BCM1
 SG_ PSD_Attribut_2_Wert : 52|4@1+ (1,0) [0|15] ""  BCM1
 SG_ PSD_Attribut_2_Offset : 56|7@1+ (2,0) [0|254] "Unit_Meter"  BCM1
 SG_ PSD_Attribute_Komplett_05 : 63|1@1+ (1,0) [0|1] ""  BCM1

BO_ 1124 PSD_06: 8 Gateway
 SG_ PSD_06_Mux M : 0|3@1+ (1,0) [0|7] ""  BCM1
 SG_ PSD_Sys_Segment_ID m0 : 3|6@1+ (1,0) [2|63] ""  BCM1
 SG_ PSD_Attribut_Segment_ID m1 : 3|6@1+ (1,0) [2|63] ""  BCM1
 SG_ PSD_Ges_Segment_ID m2 : 3|6@1+ (1,0) [2|63] ""  BCM1
 SG_ PSD_Baum_Laenge_VZ m3 : 3|1@1+ (1,0) [0|1] ""  BCM1
 SG_ PSD_Steigung_1_Segment_ID m4 : 3|6@1+ (1,0) [2|63] ""  BCM1
 SG_ PSD_Baum_Laenge m3 : 4|25@1+ (1E-005,0) [0|180] "Unit_DegreOfArc"  BCM1
 SG_ PSD_Sys_Laendercode m0 : 9|8@1+ (1,0) [0|255] ""  BCM1
 SG_ PSD_Attribut_3_ID m1 : 9|5@1+ (1,0) [1|31] ""  BCM1
 SG_ PSD_Ges_Offset m2 : 9|7@1+ (2,0) [0|254] "Unit_Meter"  BCM1
 SG_ PSD_Steigung_1_A_Steigung m4 : 9|7@1+ (0.12,0) [0|15] "Unit_PerCent"  BCM1
 SG_ PSD_Attribut_3_Offset m1 : 14|7@1+ (2,0) [0|254] "Unit_Meter"  BCM1
 SG_ PSD_Ges_Geschwindigkeit m2 : 16|5@1+ (1,0) [0|31] ""  BCM1
 SG_ PSD_Steigung_1_A_Vorz m4 : 16|1@1+ (1,0) [0|1] ""  BCM1
 SG_ PSD_Sys_Geschwindigkeit_Einheit m0 : 17|1@1+ (1,0) [0|1] ""  BCM1
 SG_ PSD_Steigung_1_A_Offset m4 : 17|7@1+ (2,0) [0|254] "Unit_Meter"  BCM1
 SG_ PSD_Sys_Verkehrsrichtung m0 : 18|1@1+ (1,0) [0|1] ""  BCM1
 SG_ PSD_Sys_Geometrieguete m0 : 19|2@1+ (1,0) [0|3] ""  BCM1
 SG_ PSD_Sys_Mapmatchingguete m0 : 21|2@1+ (1,0) [0|3] ""  BCM1
 SG_ PSD_Attribut_3_Wert m1 : 21|4@1+ (1,0) [0|15] ""  BCM1
 SG_ PSD_Ges_Typ m2 : 21|2@1+ (1,0) [0|3] ""  BCM1
 SG_ PSD_Sys_Alter_Karte m0 : 23|3@1+ (1,0) [0|7] ""  BCM1
 SG_ PSD_Ges_Spur_Geschw_Begrenzung m2 : 23|6@1+ (1,0) [0|63] ""  BCM1
 SG_ PSD_Steigung_1_B_Steigung m4 : 24|7@1+ (0.12,0) [0|15] "Unit_PerCent"  BCM1
 SG_ PSD_Attribut_4_ID m1 : 25|5@1+ (1,0) [1|31] ""  BCM1
 SG_ PSD_Sys_Zielfuehrung m0 : 26|1@1+ (1,0) [0|1] ""  BCM1
 SG_ PSD_Sys_US_State m0 : 27|6@1+ (1,0) [0|63] ""  BCM1
 SG_ PSD_Ges_Geschwindigkeit_Gespann m2 : 29|2@1+ (1,0) [0|3] ""  BCM1
 SG_ PSD_Baum_Breite_VZ m3 : 29|1@1+ (1,0) [0|1] ""  BCM1
 SG_ PSD_Attribut_4_Wert m1 : 30|4@1+ (1,0) [0|15] ""  BCM1
 SG_ PSD_Baum_Breite m3 : 30|24@1+ (1E-005,0) [0|90] "Unit_DegreOfArc"  BCM1
 SG_ PSD_Ges_Geschwindigkeit_Witter m2 : 31|2@1+ (1,0) [0|3] ""  BCM1
 SG_ PSD_Steigung_1_B_Vorz m4 : 31|1@1+ (1,0) [0|1] ""  BCM1
 SG_ PSD_Steigung_1_B_Offset m4 : 32|7@1+ (2,0) [0|254] "Unit_Meter"  BCM1
 SG_ PSD_Ges_Geschwindigkeit_Tag_Anf m2 : 33|3@1+ (1,0) [0|7] ""  BCM1
 SG_ PSD_Attribut_4_Offset m1 : 34|7@1+ (2,0) [0|254] "Unit_Meter"  BCM1
 SG_ PSD_Ges_Geschwindigkeit_Tag_Ende m2 : 36|3@1+ (1,0) [0|7] ""  BCM1
 SG_ PSD_Ges_Geschwindigkeit_Std_Anf m2 : 39|5@1+ (1,0) [0|24] "Unit_Hours"  BCM1
 SG_ PSD_Steigung_1_Attribute_kompl m4 : 39|1@1+ (1,0) [0|1] ""  BCM1
 SG_ PSD_Steigung_2_Segment_ID m4 : 40|6@1+ (1,0) [2|63] ""  BCM1
 SG_ PSD_Attribut_5_ID m1 : 41|5@1+ (1,0) [1|31] ""  BCM1
 SG_ PSD_Ges_Geschwindigkeit_Std_Ende m2 : 44|5@1+ (1,0) [0|24] "Unit_Hours"  BCM1
 SG_ PSD_Attribut_5_Offset m1 : 46|7@1+ (2,0) [0|254] "Unit_Meter"  BCM1
 SG_ PSD_Steigung_2_Steigung m4 : 46|7@1+ (0.12,0) [0|15] "Unit_PerCent"  BCM1
 SG_ PSD_Ges_Ueberholverbot m2 : 49|2@1+ (1,0) [0|3] ""  BCM1
 SG_ PSD_Ges_Wechselverkehrszeichen m2 : 51|3@1+ (1,0) [0|7] ""  BCM1
 SG_ PSD_Attribut_5_Wert m1 : 53|4@1+ (1,0) [0|15] ""  BCM1
 SG_ PSD_Steigung_2_Vorz m4 : 53|1@1+ (1,0) [0|1] ""  BCM1
 SG_ PSD_Wechselverkehrszeichen_Typ m2 : 54|2@1+ (1,0) [0|3] ""  BCM1
 SG_ PSD_Baum_Ausrichtung m3 : 54|10@1+ (0.3515625,0) [0|359.6484375] "Unit_DegreOfArc"  BCM1
 SG_ PSD_Steigung_2_Offset m4 : 54|7@1+ (2,0) [0|254] "Unit_Meter"  BCM1
 SG_ PSD_Ges_Gesetzlich_Kategorie m2 : 56|3@1+ (1,0) [0|7] ""  BCM1
 SG_ PSD_Attribute_Komplett_06 m1 : 57|1@1+ (1,0) [0|1] ""  BCM1
 SG_ PSD_Ges_Gesetzlich_Zusatz m2 : 59|2@1+ (1,0) [0|3] ""  BCM1
 SG_ PSD_Ges_Verkehrszeichen_Quelle m2 : 61|2@1+ (1,0) [0|3] ""  BCM1
 SG_ PSD_Steigung_2_Attribute_kompl m4 : 61|1@1+ (1,0) [0|1] ""  BCM1
 SG_ PSD_Ges_Attribute_Komplett m2 : 63|1@1+ (1,0) [0|1] ""  BCM1

CM_ SG_ 2600468629 NM_Sitzmemo_SR3_SNI "Source Node-Identifier (SNI) identifiziert den Sender der NM-Botschaft (Knotenadresse) eindeutig im Fahrzeug";
CM_ SG_ 2600468629 NM_Sitzmemo_SR3_CBV_AWB "Das Signal ist zu setzen, wenn das SG aktiv den Bus geweckt hat";
CM_ SG_ 2600468629 NM_Sitzmemo_SR3_CBV_CRI "Das Signal ist dauerhaft gesetzt, wenn das NM-Layout dem neuen NM-Layout für Teilnetzbetrieb entspricht";
CM_ SG_ 2600468629 NM_Sitzmemo_SR3_NM_State "1 = Zustand Repeat Message (<-- Bus-Sleep Mode)
2 = Zustand Repeat Message (<-- Prepare Bus-Sleep Mode)
4 = Zustand Normal Operation (<-- Repeat Message)
8 = Zustand Normal Operation (<-- Ready Sleep)";
CM_ SG_ 2600468629 NM_Sitzmemo_SR3_Car_Wakeup "Car Wakeup (Gateway wertet aus)
";
CM_ SG_ 2600468629 NM_Sitzmemo_SR3_UDS_CC "Funktionseinschränkung aufgrund aktivem UDS-Communication Control; siehe VW80124";
CM_ SG_ 2600468629 NM_Sitzmemo_SR3_NM_aktiv_KL15 "Steuergerät hat KL15-EIN erkannt";
CM_ SG_ 2600468629 NM_Sitzmemo_SR3_NM_aktiv_Diag "Diagnose befindet sich nach VW80124 in einer NonDefaultDiagnostic-Session, z.B. ExtendedDiagnostic-Session";
CM_ SG_ 2600468629 NM_Sitzmemo_SR3_NM_aktiv_Tmin "Mindestaktivzeit ist noch nicht abgelaufen (bei jedem Weckereignis wird die Mindestaktivzeit neu gestartet)";
CM_ SG_ 2600468629 NM_Sitzmemo_SR3_NM_aktiv_ZStel "3. Sitzreihe befindet sich in einer Zwischenstellung";
CM_ SG_ 2600468629 NM_Sitzmemo_SR3_CAB "CAB = Clusteraktivbits";
CM_ BO_ 2600468516 "CAN_NM_PDU MLBevo";
CM_ SG_ 2600468516 NM_SpoilerSG_SNI "Source Node-Identifier (SNI) identifiziert den Sender der NM-Botschaft (Knotenadresse) eindeutig im Fahrzeug";
CM_ SG_ 2600468516 NM_SpoilerSG_CBV_AWB "Das Signal ist zu setzen, wenn das SG aktiv den Bus geweckt hat";
CM_ SG_ 2600468516 NM_SpoilerSG_CBV_CRI "Das Signal ist dauerhaft gesetzt, wenn das NM-Layout dem neuen NM-Layout für Teilnetzbetrieb entspricht";
CM_ SG_ 2600468516 NM_SpoilerSG_NM_State "1 = Zustand Repeat Message (<-- Bus-Sleep Mode)
2 = Zustand Repeat Message (<-- Prepare Bus-Sleep Mode)
4 = Zustand Normal Operation (<-- Repeat Message)
8 = Zustand Normal Operation (<-- Ready Sleep)";
CM_ SG_ 2600468516 NM_SpoilerSG_Car_Wakeup "Car Wakeup (Gateway wertet aus)";
CM_ SG_ 2600468516 NM_SpoilerSG_UDS_CC "Funktionseinschränkung aufgrund aktivem UDS-Communication Control; siehe VW80124";
CM_ SG_ 2600468516 NM_SpoilerSG_NM_aktiv_KL15 "Steuergerät hat KL15-EIN erkannt";
CM_ SG_ 2600468516 NM_SpoilerSG_NM_aktiv_Diagnose "Diagnose befindet sich nach VW80124 in einer NonDefaultDiagnostic-Session, z.B. ExtendedDiagnostic-Session";
CM_ SG_ 2600468516 NM_SpoilerSG_NM_aktiv_Tmin "Mindestaktivzeit ist noch nicht abgelaufen (bei jedem Weckereignis wird die Mindestaktivzeit neu gestartet)";
CM_ SG_ 2600468516 NM_SpoilerSG_CAB "CAB = Clusteraktivbits";
CM_ SG_ 2600468523 NM_STS_SNI "Source Node-Identifier (SNI) identifiziert den Sender der NM-Botschaft (Knotenadresse) eindeutig im Fahrzeug";
CM_ SG_ 2600468523 NM_STS_CBV_AWB "Das Signal ist zu setzen, wenn das SG aktiv den Bus geweckt hat";
CM_ SG_ 2600468523 NM_STS_CBV_CRI "Das Signal ist dauerhaft gesetzt, wenn das NM-Layout dem neuen NM-Layout für Teilnetzbetrieb entspricht";
CM_ SG_ 2600468523 NM_STS_NM_State "1 = Zustand Repeat Message (<-- Bus-Sleep Mode)
2 = Zustand Repeat Message (<-- Prepare Bus-Sleep Mode)
4 = Zustand Normal Operation (<-- Repeat Message)
8 = Zustand Normal Operation (<-- Ready Sleep)";
CM_ SG_ 2600468523 NM_STS_Car_Wakeup "Car Wakeup (Gateway wertet aus)";
CM_ SG_ 2600468523 NM_STS_UDS_CC "Funktionseinschränkung aufgrund aktivem UDS-Communication Control; siehe VW80124";
CM_ SG_ 2600468523 NM_STS_NM_aktiv_KL15 "Steuergerät hat KL15-EIN erkannt";
CM_ SG_ 2600468523 NM_STS_NM_aktiv_Diagnose "Diagnose befindet sich nach VW80124 in einer NonDefaultDiagnostic-Session, z.B. ExtendedDiagnostic-Session";
CM_ SG_ 2600468523 NM_STS_NM_aktiv_Tmin "Mindestaktivzeit ist noch nicht abgelaufen (bei jedem Weckereignis wird die Mindestaktivzeit neu gestartet)";
CM_ SG_ 2600468523 NM_STS_CAB "CAB = Clusteraktivbits";
CM_ SG_ 2600468555 NM_TSG_BFS_SNI "Source Node-Identifier (SNI) identifiziert den Sender der NM-Botschaft (Knotenadresse) eindeutig im Fahrzeug";
CM_ SG_ 2600468555 NM_TSG_BFS_CBV_AWB "Das Signal ist zu setzen, wenn das SG aktiv den Bus geweckt hat";
CM_ SG_ 2600468555 NM_TSG_BFS_CBV_CRI "Das Signal ist dauerhaft gesetzt, wenn das NM-Layout dem neuen NM-Layout für Teilnetzbetrieb entspricht";
CM_ SG_ 2600468555 NM_TSG_BFS_NM_State "1 = Zustand Repeat Message (<-- Bus-Sleep Mode)
2 = Zustand Repeat Message (<-- Prepare Bus-Sleep Mode)
4 = Zustand Normal Operation (<-- Repeat Message)
8 = Zustand Normal Operation (<-- Ready Sleep)";
CM_ SG_ 2600468555 NM_TSG_BFS_Car_Wakeup "Car Wakeup (Gateway wertet aus)
MQB: Türkontakt öffnen

MLBevo: Tuerkontakt oeffnen (nur mit Luftfeder), Tuerkontakt schliessen (nur mit Luftfeder); Öffnen/Schließen hintere Tür (nur mit Luftfeder)";
CM_ SG_ 2600468555 NM_TSG_BFS_UDS_CC "Funktionseinschränkung aufgrund aktivem UDS-Communication Control; siehe VW80124";
CM_ SG_ 2600468555 NM_TSG_BFS_NM_aktiv_KL15 "Steuergerät hat KL15-EIN erkannt";
CM_ SG_ 2600468555 NM_TSG_BFS_NM_aktiv_Diagnose "Diagnose befindet sich nach VW80124 in einer NonDefaultDiagnostic-Session, z.B. ExtendedDiagnostic-Session";
CM_ SG_ 2600468555 NM_TSG_BFS_NM_aktiv_Tmin "Mindestaktivzeit ist noch nicht abgelaufen (bei jedem Weckereignis wird die Mindestaktivzeit neu gestartet)";
CM_ SG_ 2600468555 NM_TSG_BFS_NM_aktiv_Taster "Nachlauf aufgrund Betätigung oder anhaltenden Betätigung einer Taste oder Schalter.
Dies gilt auch für das Senden von Botschaften aufgrund aktiver oder inaktiver Wiederholungen die für Signale von Tasten oder Schalterereignissen definiert wurden.";
CM_ SG_ 2600468555 NM_TSG_BFS_NM_aktiv_LIN "Hinteres TSG (LIN-Slave) meldet keine Schlafbereitschaft.";
CM_ SG_ 2600468555 NM_TSG_BFS_NM_aktiv_Bordsteinfkt "TSG muss bei aktiver Funktion 'Aussenspiegel_Bordsteinfunktion' aktiv bleiben.
Bordsteinfunktion beinhaltet Spiegelabsenkung wenn rückwärts eingeparkt wird.";
CM_ SG_ 2600468555 NM_TSG_BFS_NM_aktiv_EC_Spiegel "EC-Spiegeldimmung aktiv";
CM_ SG_ 2600468555 NM_TSG_BFS_NM_aktiv_Spiegelhzg "Spiegelheizung ist aktiv";
CM_ SG_ 2600468555 NM_TSG_BFS_CAB "CAB = Clusteraktivbits";
CM_ SG_ 2600468554 NM_TSG_FS_SNI "Source Node-Identifier (SNI) identifiziert den Sender der NM-Botschaft (Knotenadresse) eindeutig im Fahrzeug";
CM_ SG_ 2600468554 NM_TSG_FS_CBV_AWB "Das Signal ist zu setzen, wenn das SG aktiv den Bus geweckt hat";
CM_ SG_ 2600468554 NM_TSG_FS_CBV_CRI "Das Signal ist dauerhaft gesetzt, wenn das NM-Layout dem neuen NM-Layout für Teilnetzbetrieb entspricht";
CM_ SG_ 2600468554 NM_TSG_FS_NM_State "1 = Zustand Repeat Message (<-- Bus-Sleep Mode)
2 = Zustand Repeat Message (<-- Prepare Bus-Sleep Mode)
4 = Zustand Normal Operation (<-- Repeat Message)
8 = Zustand Normal Operation (<-- Ready Sleep)";
CM_ SG_ 2600468554 NM_TSG_FS_Car_Wakeup "Car Wakeup (Gateway wertet aus)
MQB: Türkontakt öffnen, Tankwunschtaster betätigt (Drucktank)

MLBevo: Tuerkontakt oeffnen, Tuerkontakt schliessen (nur mit Luftfeder); hintere Türen öffnen/schließen (nur mit Luftfeder); TDE-Taster";
CM_ SG_ 2600468554 NM_TSG_FS_UDS_CC "Funktionseinschränkung aufgrund aktivem UDS-Communication Control; siehe VW80124";
CM_ SG_ 2600468554 NM_TSG_FS_NM_aktiv_KL15 "Steuergerät hat KL15-EIN erkannt";
CM_ SG_ 2600468554 NM_TSG_FS_NM_aktiv_Diagnose "Diagnose befindet sich nach VW80124 in einer NonDefaultDiagnostic-Session, z.B. ExtendedDiagnostic-Session";
CM_ SG_ 2600468554 NM_TSG_FS_NM_aktiv_Tmin "Mindestaktivzeit ist noch nicht abgelaufen (bei jedem Weckereignis wird die Mindestaktivzeit neu gestartet)";
CM_ SG_ 2600468554 NM_TSG_FS_NM_aktiv_Taster "Nachlauf aufgrund Betätigung oder anhaltenden Betätigung einer Taste oder Schalter.
Dies gilt auch für das Senden von Botschaften aufgrund aktiver oder inaktiver Wiederholungen die für Signale von Tasten oder Schalterereignissen definiert wurden.
";
CM_ SG_ 2600468554 NM_TSG_FS_NM_aktiv_LIN "Hinteres TSG (LIN-Slave) meldet keine Schlafbereitschaft.";
CM_ SG_ 2600468554 NM_TSG_FS_CAB "CAB = Clusteraktivbits";
CM_ SG_ 2600468525 NM_VSG_SNI "Source Node-Identifier (SNI) identifiziert den Sender der NM-Botschaft (Knotenadresse) eindeutig im Fahrzeug";
CM_ SG_ 2600468525 NM_VSG_CBV_AWB "Das Signal ist zu setzen, wenn das SG aktiv den Bus geweckt hat";
CM_ SG_ 2600468525 NM_VSG_CBV_CRI "Das Signal ist dauerhaft gesetzt, wenn das NM-Layout dem neuen NM-Layout für Teilnetzbetrieb entspricht";
CM_ SG_ 2600468525 NM_VSG_NM_State "1 = Zustand Repeat Message (<-- Bus-Sleep Mode)
2 = Zustand Repeat Message (<-- Prepare Bus-Sleep Mode)
4 = Zustand Normal Operation (<-- Repeat Message)
8 = Zustand Normal Operation (<-- Ready Sleep)";
CM_ SG_ 2600468525 NM_VSG_Car_Wakeup "Car Wakeup (Gateway wertet aus)";
CM_ SG_ 2600468525 NM_VSG_UDS_CC "Funktionseinschränkung aufgrund aktivem UDS-Communication Control; siehe VW80124";
CM_ SG_ 2600468525 NM_VSG_NM_aktiv_KL15 "Steuergerät hat KL15-EIN erkannt";
CM_ SG_ 2600468525 NM_VSG_NM_aktiv_Diagnose "Diagnose befindet sich nach VW80124 in einer NonDefaultDiagnostic-Session, z.B. ExtendedDiagnostic-Session";
CM_ SG_ 2600468525 NM_VSG_NM_aktiv_Tmin "Mindestaktivzeit ist noch nicht abgelaufen (bei jedem Weckereignis wird die Mindestaktivzeit neu gestartet)";
CM_ SG_ 2600468525 NM_VSG_CAB "CAB = Clusteraktivbits";
CM_ SG_ 1377 NV_Obj_01_InvTTCBildebStdA "Standardabweichung zu NV_Obj_01_InvTTCBildeb";
CM_ SG_ 1377 NV_Obj_Warnung_Fussgaenger "Warnung auf NV_Obj_01 im Fahrzeug signalisiert";
CM_ SG_ 1377 NV_Obj_Rechts "Objekt für Markierungslicht in Fahrtrichtung rechts";
CM_ SG_ 1377 NV_Obj_Links "Objekt für Markierungslicht in Fahrtrichtung links";
CM_ SG_ 1377 NV_Obj_01_Klasse "Klasse des Objekts";
CM_ SG_ 1377 NV_MessZeitpunkt "Messzeitpunkt der Objekte und der Ergebnisse anderer Wahrnehmungsmodule
Bei Nightvision: Aufnahmezeitpunkt des zugehörigen Bildes";
CM_ SG_ 1377 NV_Sensor_PositionY "Position der Kamera in USK-Koordinaten
y-Koordinate des Fokussierpunktes der Kamera-Optik";
CM_ SG_ 1377 NV_Sensor_PositionX "Position der Kamera in USK-Koordinaten
x-Koordinate des Fokussierpunktes der Kamera-Optik";
CM_ SG_ 1377 NV_Sensor_PositionZ "Position der Kamera in USK-Koordinaten
z-Koordinate des Fokussierpunktes der Kamera-Optik";
CM_ SG_ 1377 NV_NichtVerfuegbar "Verfuegbarkeit Nightvision";
CM_ BO_ 1635 "DLC=8 ab D4 gültig";
CM_ SG_ 1635 BEM_02_Abschaltstufen "Abschaltstufen des Ruhestrommanagements (Initialisierungswert aus EEprom)

Stufe 0 (keine Einschraenkungen)
Stufe 1 (Abschaltung Hochstromverbraucher)
Stufe 2 (Infotainmentabschaltung)
Stufe 3 (Wake-Up-Sperre)

Für den Transport- und Ruhestrommessm";
CM_ SG_ 1635 BEM_STH_Zielzeit "Maximal mögliche Zeit für den Standheizungsbetrieb, um die Startfähigkeit nicht zu gefährden";
CM_ SG_ 1635 BEM_MMI_Vorwarnung "Anzeige Vorwarnung MMI-Abschaltung (Initialisierungswert aus EEprom)
";
CM_ SG_ 1635 NVEM_Anf_SD_schalten "Anforderung Nachlauf für den Steckdosenbetrieb
Initialisierungswert aus EEprom";
CM_ SG_ 1635 BEM_Generatordiagnose "Ansteuerung Generatorwarnleuchte im Kombi
";
CM_ SG_ 1635 BEM_Red_Innengeblaese "Reduzierung Innengebläse
";
CM_ SG_ 1635 BEM_STH_Einschaltverbot "Einschränkung Standheizung/-lüftung durch BEM: Setzt der BEM das Bit, dann darf die Standheizung nicht mehr einschalten
(Die Standheizung muss aber nicht abschalten, sondern darf weiterbrennen)
(Initialisierungswert aus EEprom)
";
CM_ SG_ 1635 BEM_HL_Regelung_Status "Status Regelung Heizleistung
";
CM_ SG_ 1635 BEM_Ladezustand "Ladezustand der Niedervoltbatterie
";
CM_ SG_ 1635 BEM_Batteriediagnose "Anzeige von Textwarnungen";
CM_ SG_ 1635 MIB_Stromsparmodus "Signal beschreibt die Aktivierung für den Stromsparmodus beim MIB.
Bei AUS (= 0) gibt es keine weitere Anforderung an die MIB-Komponenten.
Bei EIN (= 1) werden alle MIB Komponenten in einen Stromsparmodus versetzt.";
CM_ SG_ 1635 BEM_REK_aktiv "Rekuperationsfreigabe vom Energiemanagement
0x0 = keine Rekuperationsfreigabe
0x1 = Rekuperationsfreigabe";
CM_ SG_ 1635 BEM_UBDM "Batteriespannung, gemessen vom Batteriedatenmodul";
CM_ SG_ 1635 BEM_UGenSoll "Sollspannungsvorgabe an den Generator, beinhaltet temperaturoptimierte Batterieladung und Rekuperation";
CM_ SG_ 1635 BEM_Anf_KL15_schalten "Abschaltempfehlung bzw. Verhinderung der automatischen Abschaltung Kl15 durch das BCM";
CM_ SG_ 1635 NVEM_Batterie_Service "Anforderung einer Batterie-Service - Anzeige / Anforderung an die Werkstatt über MOD";
CM_ SG_ 913 OBD_Calc_Load_Val "Calculated Load Value

Übertragung von Meßgrößen an das Getriebesteuergerät für Freeze Frame Abspeicherung bei Getriebefehlern

PID $04 Calculated Load Value; 0 .. 100% mit 100/255 % per bit
";
CM_ SG_ 913 OBD_Eng_Cool_Temp "Engine Coolant Temperature

Übertragung von Meßgrößen an das Getriebesteuergerät für Freeze Frame Abspeicherung bei Getriebefehlern

PID $05 Engine Coolant Temperature; -40 .. +215°C mit 1°C/bit und 40°C Offset";
CM_ SG_ 913 OBD_Abs_Throttle_Pos "Absolute Throttle Position

Übertragung von Meßgrößen an das Getriebesteuergerät für Freeze Frame Abspeicherung bei Getriebefehlern

PID $11 Absolute Throttle Position; 0 .. 100% mit 100/255 %/bit";
CM_ SG_ 913 OBD_Abs_Load_Val "Absolute Load Value

Übertragung von Meßgrößen an das Getriebesteuergerät für Freeze Frame Abspeicherung bei Getriebefehlern

PID $43 Absolute Load Value; 0 .. 25700%  mit 100/255 %/bit";
CM_ SG_ 913 OBD_Abs_Pedal_Pos "Absolute Pedal Position

Übertragung von Meßgrößen an das Getriebesteuergerät für Freeze Frame Abspeicherung bei Getriebefehlern

PID $49 Accelerator Pedal Position D; 0 .. 100% mit 100/255 %/bit";
CM_ SG_ 913 MO_Servicemodus "Ausgabe aktiver Service-Mode";
CM_ SG_ 913 MO_QBit_Aussen_Temp "QBit der Aussentemperatur. Gesetzt bei Ersatzwert, Init oder Fehler.";
CM_ SG_ 913 OBD_Sperrung_IUMPR "Wenn der General Denominator auf Grund eines Fehlers in den Eingangsgrößen gesperrt wird, wird diese Information über Bussystem als OBD-Statusinformation OBD_Sperrung_IUMPR für andere OBD-Steuergeräte bereitgestellt. 

Das MSG (MIL-Master) setzt dieses ";
CM_ SG_ 913 OBD_Kaltstart_Denominator "Bestimmte Diagnosen werden nur unter Kaltstartbedingungen durchgeführt, der entsprechende Denominator bei IUMPR-pflichtigen Systemen wird anhand dieses vom MSG gebildeten Signals inkrementiert. (Entspricht EVAP-Denominator)";
CM_ SG_ 913 OBD_Minimum_Trip "Grundlage OBD-Gesetz CCR 1968.2 (d)(4.3) Denominator Specifications
Bildung des General Denominator 'Normed Trip':
 600 sec. (kumulativ) Zeit nach Motorstart
 300 sec. (kumulativ) mit Fahrzeuggeschwindigkeit > 25 mph (40 km/h)
 30 sec. (kontinuierlich";
CM_ SG_ 913 OBD_Warm_Up_Cycle "Mit dem Warm-Up-Cycle wird der zentrale Verlernzähler vom Gateway inkrementiert";
CM_ SG_ 913 OBD_Normed_Trip "Gesetzlich definierte 'Normed Condition' erfüllt, 'General Denominator' darf erhöht werden";
CM_ BO_ 1630 "Tankgeberwerte für OBD-relevante Plausibilisierung im Motor-SG";
CM_ SG_ 1630 OBD_TG_F_Status_1 "Fehlerstatus Tankfüllstandsgeber (OBD relevanter Sensor für Tankleckdiagnose)";
CM_ SG_ 1630 OBD_TG_F_Status_2 "Fehlerstatus Tankfüllstandsgeber (OBD relevanter Sensor für Tankleckdiagnose)

0x00 = kein Fehler / Init / nicht verbaut
0x01 = KS-
0x02 = KS+ (B8: nicht bedient)
0x03 = OC (Leitungsunterbrechung) (B8: nicht bedient)
0x04 = OOR+ (out of range high) ";
CM_ SG_ 1630 OBD_TG_F_Status_3 "Fehlerstatus Tankfüllstandsgeber (OBD relevanter Sensor für Tankleckdiagnose)

0x00 = kein Fehler / Init / nicht verbaut
0x01 = KS-
0x02 = KS+ (B8: nicht bedient)
0x03 = OC (Leitungsunterbrechung) (B8: nicht bedient)
0x04 = OOR+ (out of range high) ";
CM_ SG_ 1630 OBD_TG_F_Status_4 "Fehlerstatus Tankfüllstandsgeber (OBD relevanter Sensor für Tankleckdiagnose)

0x00 = kein Fehler / Init / nicht verbaut
0x01 = KS-
0x02 = KS+ (B8: nicht bedient)
0x03 = OC (Leitungsunterbrechung) (B8: nicht bedient)
0x04 = OOR+ (out of range high) ";
CM_ SG_ 1630 OBD_TG_Sens_Rohwert_1 "Rohwert des Tankgebers, nur gefiltert (gleitender Mittelwert), Ausgabe im 500ms-Raster";
CM_ SG_ 1630 OBD_TG_Sens_Rohwert_2 "Rohwert des Tankgebers, nur gefiltert (gleitender Mittelwert), Ausgabe im 500ms-Raster";
CM_ SG_ 1630 OBD_TG_Sens_Rohwert_3 "Rohwert des Tankgebers, nur gefiltert (gleitender Mittelwert), Ausgabe im 500ms-Raster";
CM_ SG_ 1630 OBD_TG_Sens_Rohwert_4 "Rohwert des Tankgebers, nur gefiltert (gleitender Mittelwert), Ausgabe im 500ms-Raster";
CM_ SG_ 2549875245 OBDC_VSG_Req_Data "TP-Kanal für den Onboard Datensammler";
CM_ SG_ 2550006317 OBDC_VSG_Resp_Data "TP-Kanal für den Onboard Datensammler";
CM_ SG_ 872 PH2_Visualisierung "Signal zeigt den Partnersteuergeräten RearView/TopView/ARA/... den aktuellen Status der Visualisierung des OPS. Die Partnersteuergeräte können dadurch auch ihre Aufschaltung an dieses Signal koppeln.";
CM_ SG_ 872 PH2_nachtr_Stopp_An "Dieses Signal dient dem Motor als Trigger, dass ein nachträglicher Motorstopp eingeleitet werden kann, wenn es die Bedingungen des StSt Koordinators dies zulassen. ";
CM_ SG_ 872 PH2_Abschaltursache "Abschaltursache bleibt bis zur nächsten Aktivierung bzw. bis KL15 aus gesetzt
Im Fehlerfall (blinkende LED) wird '7' gesendet obwohl das System noch aktiv ist, bei 'geheiltem' Fehler wird sofort wieder der Zustand '0' gesendet";
CM_ SG_ 872 PH2_Opt_Anzeige_V_ein "OPS vorne ist im Display aktiv bzw. Anzeigemodule vorne sind eingeschaltet. Funktion nur bei gesicherter Rückmeldung vom ASG gegeben.";
CM_ SG_ 872 PH2_Opt_Anzeige_H_ein "OPS hinten ist im Display aktiv bzw. Anzeigemodule hinten sind eingeschaltet. Funktion nur bei gesicherter Rückmeldung vom ASG gegeben.";
CM_ SG_ 872 PH2_Opt_Anz_V_Hindernis "mindestens 1 Segment wird für den vorderen Detekionsbereich dargestellt, also ein Hindernis ist im Detektionsbereich. Funktion nur bei gesicherter Rückmeldung vom ASG gegeben.";
CM_ SG_ 872 PH2_Opt_Anz_H_Hindernis "mindestens 1 Segment wird für den hinteren Detekionsbereich dargestellt, also ein Hindernis ist im Detektionsbereich. Funktion nur bei gesicherter Rückmeldung vom ASG gegeben.";
CM_ SG_ 872 PH2_Tongeber_V_aktiv "Rohsignal für 'Tongeber vorne wird angesteuert', verlängerbar mit Nachlauftimer.
Bit wird nicht während des Stellgliedtests angesteuert.";
CM_ SG_ 872 PH2_Tongeber_H_aktiv "Rohsignal für 'Tongeber hinten wird angesteuert', verlängerbar mit Nachlauftimer.
Bit wird nicht während des Stellgliedtests angesteuert.";
CM_ SG_ 872 PH2_Tongeber_mute "Die Akustikausgabe des Systems wird unterdrückt, z.B. Wählhebel in 'P', Parlbremse geschlossen (8-Kanal-System)";
CM_ SG_ 872 PH2_Anf_Audioabsenkung "Es gibt zwei unterschiedliche Nachlauftimer für dieses Bit:
1. normale Funktion
2. Demotonausgabe";
CM_ SG_ 872 PH2_Tongeber_H_verfuegbar "Tongeber ist für die Tonausgabe für externe Funktionen verfügbar. PDC ist aktiv und Tongeber ist nicht gestört.";
CM_ SG_ 872 PH2_Taster "Taster Status (für RVC/TopView)";
CM_ SG_ 872 PH2_Anf_Verdeck "Anforderung an ein Verdeck-System, die vom Fahrer angeforderte Öffnung/Schließung zu verhindern";
CM_ SG_ 872 PH2_Frequenz_hinten "Uebertragung der aktuell im APS Steuergeraet gespeicherten Werte fuer Tongeber Frequenz hinten
Anzeige der aktuell verwendeten Parameter (nicht zwingend die abgespeicherten - da Werte erst 2s nach der letzten Änderung gespeichert werden!)";
CM_ SG_ 872 PH2_Lautstaerke_hinten "Uebertragung der aktuell im APS Steuergeraet gespeicherten Werte fuer Tongeber Lautstaerke hinten
Anzeige der aktuell verwendeten Parameter (nicht zwingend die abgespeicherten - da Werte erst 2s nach der letzten Änderung gespeichert werden!)";
CM_ SG_ 872 PH2_Frequenz_vorn "Uebertragung der aktuell im APS Steuergeraet gespeicherten Werte fuer Tongeber Frequenz vorne
Anzeige der aktuell verwendeten Parameter (nicht zwingend die abgespeicherten - da Werte erst 2s nach der letzten Änderung gespeichert werden!)";
CM_ SG_ 872 PH2_Lautstaerke_vorn "Uebertragung der aktuell im APS Steuergeraet gespeicherten Werte fuer Tongeber Lautstaerke vorn.
Anzeige der aktuell verwendeten Parameter (nicht zwingend die abgespeicherten - da Werte erst 2s nach der letzten Änderung gespeichert werden!)";
CM_ SG_ 872 PH2_StartStopp_Info "Stopp-Freigabe und Start-Anforderung an den Start-Stopp-Koordinator";
CM_ SG_ 872 PH2_Stoermeldung "Meldung einer Störung der PDC an das Kombi";
CM_ SG_ 872 PH2_defekt "Zeigt an das sich die Parkhilfe im Fehlerzustand befindet. Signal bleibt bis zur nächsten 'Gut-Aktivierung' gesetzt.
Spezialfall: Sensordefekt hinten bei Anhängerbetrieb. Anhänger wird abgesteckt Fehler wird gesetzt. Fehlerfall bleibt bis Behebung des De";
CM_ SG_ 872 PH2_gestoert "Eine Störung ist aufgetreten, der die Parkhilfe in einen 'gestört-Zustand' versetzt, z.B. massiver Fremdultraschall, Vereisung, Schnee.Derzeit nur für Störschall benutzt, da keinerlei andere Erkennung implementiert.";
CM_ SG_ 872 PH2_Systemzustand "Aktivierungsursache wird für die Dauer der Aktivierung gemeldet.
Im Fehlerfall bei atkviem System wechselt das Signal auf '7'
(siehe auch 'Abschaltursache')";
CM_ SG_ 872 PH2_Display_Kundenwunsch "Anzeige der bei Aktivierung verwendeten Parameter bzgl. Kundenwunsch Displayanziege. Änderungen werden erst bei erneuter Aktivierung aktualisiert.";
CM_ SG_ 872 APS2_Tongeber_defekt "Status APS-Tongeber zur HMI-Ansteuerng der RCTA-Funktion";
CM_ BO_ 1175 "neue Struktur ab MQB ohne KD-Fehler";
CM_ SG_ 1175 PH_Visualisierung "Signal zeigt den Partnersteuergeräten RearView/TopView/ARA/... den aktuellen Status der Visualisierung des OPS. Die Partnersteuergeräte können dadurch auch ihre Aufschaltung an dieses Signal koppeln.";
CM_ SG_ 1175 PDC_Tonausgabe_Front "In Abhängigkeit der Systemaktivitäten werden unterschiedliche Tonwarnungen ausgegeben. 
Kombi spielt entsprechende WAV.-Datei über internen Audiomaster ab.

0 = kein Ton
1 = Intervallton 1
2 = Intervallton 2
3 = Intervallton 3
4 = Intervallton 4
5";
CM_ SG_ 1175 PDC_Tonausgabe_Heck "In Abhängigkeit der Systemaktivitäten werden unterschiedliche Tonwarnungen ausgegeben. 
Kombi spielt entsprechende WAV.-Datei über internen Audiomaster ab.

0 = kein Ton
1 = Intervallton 1
2 = Intervallton 2
3 = Intervallton 3
4 = Intervallton 4
5";
CM_ SG_ 1175 PH_nachtr_Stopp_Anf "Dieses Signal dient dem Motor als Trigger, dass ein nachträglicher Motorstopp eingeleitet werden kann, wenn es die Bedingungen des StSt Koordinators dies zulassen. ";
CM_ SG_ 1175 PH_Abschaltursache "Abschaltursache bleibt bis zur nächsten Aktivierung bzw. bis KL15 aus gesetzt
Im Fehlerfall (blinkende LED) wird '7' gesendet obwohl das System noch aktiv ist, bei 'geheiltem' Fehler wird sofort wieder der Zustand '0' gesendet";
CM_ SG_ 1175 PH_Opt_Anzeige_V_ein "OPS vorne ist im Display aktiv bzw. Anzeigemodule vorne sind eingeschaltet. Funktion nur bei gesicherter Rückmeldung vom ASG gegeben.";
CM_ SG_ 1175 PH_Opt_Anzeige_H_ein "OPS hinten ist im Display aktiv bzw. Anzeigemodule hinten sind eingeschaltet. Funktion nur bei gesicherter Rückmeldung vom ASG gegeben.";
CM_ SG_ 1175 PH_Opt_Anz_V_Hindernis "mindestens 1 Segment wird für den vorderen Detekionsbereich dargestellt, also ein Hindernis ist im Detektionsbereich. Funktion nur bei gesicherter Rückmeldung vom ASG gegeben.";
CM_ SG_ 1175 PH_Opt_Anz_H_Hindernis "mindestens 1 Segment wird für den hinteren Detekionsbereich dargestellt, also ein Hindernis ist im Detektionsbereich. Funktion nur bei gesicherter Rückmeldung vom ASG gegeben.";
CM_ SG_ 1175 PH_Tongeber_V_aktiv "Rohsignal für 'Tongeber vorne wird angesteuert', verlängerbar mit Nachlauftimer.
Bit wird nicht während des Stellgliedtests angesteuert.";
CM_ SG_ 1175 PH_Tongeber_H_aktiv "Rohsignal für 'Tongeber hinten wird angesteuert', verlängerbar mit Nachlauftimer.
Bit wird nicht während des Stellgliedtests angesteuert.";
CM_ SG_ 1175 PH_Tongeber_mute "Die Akustikausgabe des Systems wird unterdrückt, z.B. Wählhebel in 'P', Parlbremse geschlossen (8-Kanal-System)";
CM_ SG_ 1175 PH_Anf_Audioabsenkung "Es gibt zwei unterschiedliche Nachlauftimer für dieses Bit:
1. normale Funktion
2. Demotonausgabe";
CM_ SG_ 1175 PH_Tongeber_H_verfuegbar "Tongeber ist für die Tonausgabe für externe Funktionen verfügbar. PDC ist aktiv und Tongeber ist nicht gestört.";
CM_ SG_ 1175 PLA_Anf_Aufschaltung_RVC "Anforderung der Aufschaltung RVC durch PLA";
CM_ SG_ 1175 PH_Taster "Taster Status (für RVC/TopView)";
CM_ SG_ 1175 PH_Anf_Verdeck "Anforderung an ein Verdeck-System, die vom Fahrer angeforderte Öffnung/Schließung zu verhindern";
CM_ SG_ 1175 PH_Frequenz_hinten "Uebertragung der aktuell im APS Steuergeraet gespeicherten Werte fuer Tongeber Frequenz hinten
Anzeige der aktuell verwendeten Parameter (nicht zwingend die abgespeicherten - da Werte erst 2s nach der letzten Änderung gespeichert werden!)";
CM_ SG_ 1175 PH_Lautstaerke_hinten "Uebertragung der aktuell im APS Steuergeraet gespeicherten Werte fuer Tongeber Lautstaerke hinten
Anzeige der aktuell verwendeten Parameter (nicht zwingend die abgespeicherten - da Werte erst 2s nach der letzten Änderung gespeichert werden!)";
CM_ SG_ 1175 PH_Frequenz_vorn "Uebertragung der aktuell im APS Steuergeraet gespeicherten Werte fuer Tongeber Frequenz vorne
Anzeige der aktuell verwendeten Parameter (nicht zwingend die abgespeicherten - da Werte erst 2s nach der letzten Änderung gespeichert werden!)";
CM_ SG_ 1175 PH_Lautstaerke_vorn "Uebertragung der aktuell im APS Steuergeraet gespeicherten Werte fuer Tongeber Lautstaerke vorn.
Anzeige der aktuell verwendeten Parameter (nicht zwingend die abgespeicherten - da Werte erst 2s nach der letzten Änderung gespeichert werden!)";
CM_ SG_ 1175 PH_StartStopp_Info "Stopp-Freigabe und Start-Anforderung an den Start-Stopp-Koordinator";
CM_ SG_ 1175 PH_Stoermeldung "Meldung einer Störung der PDC an das Kombi";
CM_ SG_ 1175 PH_defekt "Zeigt an das sich die Parkhilfe im Fehlerzustand befindet. Signal bleibt bis zur nächsten 'Gut-Aktivierung' gesetzt.
Spezialfall: Sensordefekt hinten bei Anhängerbetrieb. Anhänger wird abgesteckt Fehler wird gesetzt. Fehlerfall bleibt bis Behebung des De";
CM_ SG_ 1175 PH_gestoert "Eine Störung ist aufgetreten, der die Parkhilfe in einen 'gestört-Zustand' versetzt, z.B. massiver Fremdultraschall, Vereisung, Schnee.Derzeit nur für Störschall benutzt, da keinerlei andere Erkennung implementiert.";
CM_ SG_ 1175 PH_Systemzustand "Aktivierungsursache wird für die Dauer der Aktivierung gemeldet.
Im Fehlerfall bei atkviem System wechselt das Signal auf '7'
(siehe auch 'Abschaltursache')";
CM_ SG_ 1175 PH_Display_Kundenwunsch "Anzeige der bei Aktivierung verwendeten Parameter bzgl. Kundenwunsch Displayanziege. Änderungen werden erst bei erneuter Aktivierung aktualisiert.";
CM_ SG_ 2527679498 Perso_Kontonummer "Signal gibt die jewels aktuelle Kontonummer für die Personalisierung an.
Nicht für AU736 und AU48x.";
CM_ SG_ 2527679498 Perso_Steuerung "Signal gibt einen Steuerungsbefehl an die Funktionsteilnehmer der Personalisierung.
Nicht für AU736 und AU49x.";
CM_ SG_ 2527679498 Perso_Steuerungsparameter "Signal gibt einen Parameter zum Steuerungsbefehl (Signal Perso_Steuerung) für die Personalisierung an.
Nicht für AU736 und AU49x.";
CM_ SG_ 2527679498 Perso_Status "Signal zeigt an, ob die Personalisierung vom Fahrer aktiviert / deaktiviert ist.
Nicht für AU736 und AU49x.";
CM_ SG_ 2527679498 Perso_Bedienstelle "Signal zeigt an, über welche Bedienstelle die Umschaltung des Benutzerkontos gestartet wurden.";
CM_ SG_ 2527679498 Perso_Freigabe_Verstellung "Signal zeigt an, ob die Ergonomiefunktionen nach Umschaltung des Benutzerkontos verfahren dürfen.";
CM_ BO_ 304 "Nur in MLB verwendet";
CM_ SG_ 304 PLA_01_CRC "Für MLB:
Berechnung siehe Lastenheft 'Kommunikationsabsicherung für FlexRay und CAN''

Ab MQB und MLBevo:
Berechnung siehe Lastenheft 'End-to-End Kommunikationsabsicherung'

Endwerte siehe Begleitdokument 'S-PDU Kennungsfolgen'";
CM_ SG_ 304 PLA_01_BZ "4bit-Botschaftszaehler, wird in jeder Sendebotschaft inkrementiert

";
CM_ SG_ 304 PLA_Status_PLA_ESP "Zustand der Statusmaschine des PLA für die korrespondierenden Statusmaschine in der Bremse.";
CM_ SG_ 304 PLA_Zahnstangen_Pos_Soll "Steuerbefehl an EPS zum Einstellen der angeforderten Zahnstangenposition.";
CM_ SG_ 304 PLA_VZ_Zahnstangen_Pos_Soll "Vorzeichen zum Lenkwinkel-Steuerbefehl an EPS zum Einstellen des angeforderten Lenkwinkels.";
CM_ SG_ 304 PLA_Status_PLA_EPS "Schnittstelle zum Austausch von Statusinformationen der internen Statusmaschine. Erforderlich zum Aktivieren der automatischen Lenkung.";
CM_ SG_ 304 PLA_Bremsverzoegerung "Wert der Bremsverzögerung für eine Bremsung durch PLA";
CM_ SG_ 304 PLA_Anf_Bremsverzoegerung "Anforderung der Verzögerungsbremsung";
CM_ SG_ 304 PLA_BremsMom_Verzoeg "Kennzeichnung der übertragenen Sollvorgabe
0 = Bremsmoment: MQB A
1 = Bremsverzoegerung: MLBevo, MQB B
Die Bedatung ist im Fahrzeug konstant.";
CM_ SG_ 304 PLA_01_Signal_red_cyclic "Zeigt die reduzierte Zykluszeit der CAN-Botschaft 'PLA_01' an.";
CM_ SG_ 342 PLA_02_CRC "Für MLB:
Berechnung siehe Lastenheft 'Kommunikationsabsicherung für FlexRay und CAN''

Ab MQB und MLBevo:
Berechnung siehe Lastenheft 'End-to-End Kommunikationsabsicherung'

Endwerte siehe Begleitdokument 'S-PDU Kennungsfolgen'";
CM_ SG_ 342 PLA_02_BZ "4bit-Botschaftszaehler, wird in jeder Sendebotschaft inkrementiert

";
CM_ SG_ 342 PLA_Status_PLA_HAL "Zustand der Statusmaschine des PLA für die korrespondierenden Statusmaschine in der Hinterachslenkung,";
CM_ SG_ 342 PLA_HAL_Radwinkel_Soll "Steuerbefehl an HAL zum Einstellen des angeforderten Radwinkels.";
CM_ SG_ 342 PLA_HAL_VZ_Radwinkel_Soll "Vorzeichen des vom PLA angeforderten Lenkwinkels der HAL";
CM_ SG_ 342 PLA_Status_PLA_TSK "Statusinformation von PLA für Handshakemechanismus mit TSK (Speedlimiterfunktion)

(oll in PLA_02 Botschaft gepackt werden)";
CM_ SG_ 342 PLA_maximale_Geschwindigkeit "Gibt den Wert der maximal zulässigen Geschwindigkeit vor. Die während aktiver PLA Regelung vom TSK zugelassen werden darf.";
CM_ SG_ 342 PLA_02_Signal_red_cyclic "Zeigt die reduzierte Zykluszeit der CAN-Botschaft 'PLA_02' an.";
CM_ SG_ 1166 PLA_Status_Aktive_Seite "Anzeige der zu parkenden Seite";
CM_ SG_ 1166 PLA_Anf_Anzeige_Mini "28.09.2012: Init-Wert auf 0 gesetzt; Kommentar angepasst;";
CM_ SG_ 1166 PLA_Mini_Modus "Art des vom PLA zur Darstellung angeforderten Minis. Wird angezeigt, wenn PLA_Anf_Anzeige_Mini=1.";
CM_ SG_ 1166 PLA_Anf_Akustik "Anzeige, ob das PLA einen Gong im Kombi anfordert, Gong soll mit dem Übergang 0->1 abgespielt werden.";
CM_ SG_ 1166 PLA_Anf_Anzeige_Schwellpfeil "Anzeige, ob PLA im Kombi den Schwellpfeil zur Darstellung der Restwegstrecke im aktuellen Zug anfordert";
CM_ SG_ 1166 PLA_Anf_Anzeige_Bremsfuss "Anzeige, ob PLA die Anzeige eines Bremsfusses anfordert";
CM_ SG_ 1166 PLA_Anf_Funktionsdisclaimer "Anforderung des Funktionsdisclaimer durch PLA";
CM_ SG_ 1166 PLA_Anf_Anzeigemodus "Anzeigemodus das vom PLA je nach Parkszenario beim Kombi angefordert wird";
CM_ SG_ 1166 PLA_Anf_Meldungen "Anforderung der Meldungen:
0 - Keine Meldung
1-127 niederprio. Meldungen
128-255 hochprio. Meldungen";
CM_ SG_ 1166 PLA_Anzahl_Segmente_Schwellpfeil "Wird ein Schwellpfeil angezeigt, gibt dieses Signal die Länge des breiten Balkens in Anzahl der Segmente (max. Länge: 15 Segmente).

Wird keine Anzeige der Schwellpfeile angefordert, muss die Anzahl Segmente 0 sein.";
CM_ SG_ 1166 PLA_Status_Funktion "Funktionsstati, die die einzelnen Schritte innerhalb eines Parkszenarios anzeigen.";
CM_ SG_ 1166 PLA_Status_beenden_Mini "Status Anzeige beendet Mini";
CM_ SG_ 1166 PLA_Status_Laengsparken_Mini "Status Anzeige Längsparken Mini";
CM_ SG_ 1166 PLA_Status_QP_Rueckw_Mini "Status Anzeige Querparken rückwärts Mini";
CM_ SG_ 1166 PLA_Status_QP_Vorw_Mini "Status Anzeige Querparken vorwärtsMini";
CM_ SG_ 319 PreCrash_Charisma_FahrPr "Aktuell eingestelltes Fahrprogramm der Funktion PreCrash";
CM_ SG_ 319 PreCrash_Charisma_Status "Verfügbarkeit der Funktion PreCrash für die Ansteuerung durch den Charisma_Koordinator";
CM_ SG_ 319 PreCrash_Schiebedach_schliessen "Anforderung Schiebedach schließen durch die Funktion PreCrash";
CM_ SG_ 319 PreCrash_Fenster_schliessen "Anforderung Seitenscheiben schließen durch die Funktion PreCrash";
CM_ SG_ 319 PreCrash_Blinken "Safety Computer übermittelt Blinkverhalten bei einer PreCrash-Auslösung an den BCM2";
CM_ SG_ 319 SC_PreCrash_LED "Ansteuerung LED-Leiste im Kombi durch SC";
CM_ SG_ 319 PreCrash_FS_Pneumatik_ansteuern "Ansteuerung des Fahrersitzes durch die PreCrash-Funktionen";
CM_ SG_ 319 PreCrash_BFS_Pneumatik_ansteuern "Ansteuerung des Fahrersitzes durch die PreCrash-Funktionen";
CM_ SG_ 319 PreCrash_Fo_Pneumatik_ansteuern "Ansteuerung des Fahrersitzes durch die PreCrash-Funktionen";
CM_ SG_ 319 PreCrash_FS_Sitzlehne_verfahren "Ansteuerung des Fahrersitzes durch die PreCrash-Funktionen";
CM_ SG_ 319 PreCrash_BFS_Sitzlehne_verfahren "Ansteuerung des Fahrersitzes durch die PreCrash-Funktionen";
CM_ SG_ 319 PreCrash_Fo_Sitzlehne_verfahren "Ansteuerung des Fondsitzes durch die PreCrash-Funktionen";
CM_ SG_ 319 PreCrash_FS_KSV_verfahren "Ansteuerung der Kopfstuetze durch die Funktion PreCrash";
CM_ SG_ 319 PreCrash_BFS_KSV_verfahren "Ansteuerung der Kopfstuetze Beifahrerseite durch die Funktion PreCrash";
CM_ SG_ 319 PreCrash_Fo_KSV_verfahren "Ansteuerung des Fondsitzes durch die PreCrash-Funktionen";
CM_ SG_ 319 SC_PreCrash_Warnung "Safety Computer übermittelt Warnung der PreCrash Funktionen an Kombi";
CM_ SG_ 319 SC_PreCrash_Texte "Safety Computer übermittelt Systemstatus der PreCrash Funktionen an Kombi";
CM_ SG_ 1122 PSD_Segment_ID "Identifier des prädiktiven Streckensegments
";
CM_ SG_ 1122 PSD_Vorgaenger_Segment_ID "An dem Streckensegment mit diesem Identifier schließt sich das neue Segment mit der ID 'PSD_01_Segment_ID' an.
";
CM_ SG_ 1122 PSD_Segmentlaenge "Gesamtlänge des prädiktiven Streckensegments";
CM_ SG_ 1122 PSD_Strassenkategorie "Klassifizierung der Straße des beschriebenen Segments
";
CM_ SG_ 1122 PSD_Endkruemmung "'Endkrümmung der Klotoide des übermittelten Streckensegments. Die Anfangskrümmung des folgenden Streckensegments entspricht der Endkrümmung dieses Segments. Krümmung = 1/(1+0.155 * x²) [1/m]

";
CM_ SG_ 1122 PSD_Idenditaets_ID "Identifier auf ein Streckensegment, dass mit dem aktuell übertragenen geometrisch identisch ist.";
CM_ SG_ 1122 PSD_ADAS_Qualitaet "ADAS Qualtität des Streckensegments.";
CM_ SG_ 1122 PSD_wahrscheinlichster_Pfad "Identifiziert den vom Navigationssystem berechneten wahrscheinlichsten Pfad des Fahrzeuges. ";
CM_ SG_ 1122 PSD_Geradester_Pfad "Segment ist Teil des geradesten Pfades";
CM_ SG_ 1122 PSD_Fahrspuren_Anzahl "Anzahl der Fahrspuren in Fahrtrichtung
";
CM_ SG_ 1122 PSD_Bebauung "Segement befindet sich innerhalb bebauten Gebietes";
CM_ SG_ 1122 PSD_Segment_Komplett "Zeigt, ob alle Attribute für das Segment übertragen worden sind
";
CM_ SG_ 1122 PSD_Anfangskruemmung "Startkrümmung der Klothoide des übermittelten abzweigenden Streckensegments. 
1/(1+0.155 * x^2) {1/m}'
";
CM_ SG_ 1122 PSD_Anfangskruemmung_Vorz "Vorzeichen für die Startkrümmung bei Abzweigungen
";
CM_ SG_ 1122 PSD_Abzweigerichtung "Richtung, in der die Abzweigung von der Hauptroute abzweigt
";
CM_ SG_ 1122 PSD_Abzweigewinkel "Winkel, unter dem die Abzweigung von der Hauptroute abzweigt.
";
CM_ SG_ 1123 PSD_Pos_Segment_ID "Identifier des Streckensegments, auf dem sich das Fahrzeug aktuell befindet
";
CM_ SG_ 1123 PSD_Pos_Segmentlaenge "Verbleibende Länge des Streckensegments, auf dem sich das Fahrzeug aktuell befindet
";
CM_ SG_ 1123 PSD_Pos_Inhibitzeit "Zeitspanne zwischen Generierung der PSD Daten im Navigationssystem und Versand der Daten auf den Most
";
CM_ SG_ 1123 PSD_Pos_Standort_Eindeutig "Ist die Position des Fahrzeugs eindeutig dem aktuelle Segment zugeordnet, oder gibt es fahrbare alternative Segmente, die bei akteller GPS-Position ebenfalls als aktuelles Segment möglich wären.";
CM_ SG_ 1123 PSD_Pos_Fehler_Laengsrichtung "Laengsfehler der Positionierung";
CM_ SG_ 1123 PSD_Pos_Fahrspur "Spur, auf der sich das Fahrzeug aktuell befindet";
CM_ SG_ 1123 PSD_Attribut_Segment_ID_05 "Identifier des Streckensegments, für das die weiteren Attribute in der Botschaft gültig sind";
CM_ SG_ 1123 PSD_Attribut_1_ID "Identifier des ersten Attributes";
CM_ SG_ 1123 PSD_Attribut_1_Wert "Wert des ersten Attributes";
CM_ SG_ 1123 PSD_Attribut_1_Offset "Positionsoffset im Segment für die Position des Attributs";
CM_ SG_ 1123 PSD_Attribut_2_ID "Identifier des zweiten Attributes";
CM_ SG_ 1123 PSD_Attribut_2_Wert "Wert des zweiten Attributes";
CM_ SG_ 1123 PSD_Attribut_2_Offset "Positionsoffset im Segment für die Position des Attributs";
CM_ SG_ 1123 PSD_Attribute_Komplett_05 "Zeigt, ob alle Attribute für das Segment übertragen worden sind";
CM_ SG_ 1124 PSD_06_Mux "Multiplex Zähler für die PSD_06-Botschaft";
CM_ SG_ 1124 PSD_Sys_Segment_ID "Identifier des prädiktiven Streckensegments ab dem die Systeminformationen gültig sind.
";
CM_ SG_ 1124 PSD_Attribut_Segment_ID "Identifier des Streckensegments,für das die weiteren Attribute in der Botschaft gültig sind";
CM_ SG_ 1124 PSD_Ges_Segment_ID "Identifier des prädiktiven Streckensegments ab dem die Geschwindigkeitsbegrenzungen und mögliche Einschränkungen gelten.
";
CM_ SG_ 1124 PSD_Baum_Laenge_VZ "Vorzeichen WGS84 Laenge des Fahrzeugsegments";
CM_ SG_ 1124 PSD_Steigung_1_Segment_ID "Identifier des prädiktiven Streckensegments, zu dem die  ersten beiden Steigungswerte dieser Botschaft gehören";
CM_ SG_ 1124 PSD_Baum_Laenge "WGS84 Laenge des Fahrzeugsegments";
CM_ SG_ 1124 PSD_Sys_Laendercode "Ländercode
";
CM_ SG_ 1124 PSD_Attribut_3_ID "Identifier des dritten Attributes";
CM_ SG_ 1124 PSD_Ges_Offset "Positionsoffset im Segment für die Position des Attributs";
CM_ SG_ 1124 PSD_Steigung_1_A_Steigung "Steigung des Segments ab Offset 1A";
CM_ SG_ 1124 PSD_Attribut_3_Offset "Positionsoffset im Segment für die Position des Attributs";
CM_ SG_ 1124 PSD_Steigung_1_A_Vorz "Vorzeichen für Steigung 1 A";
CM_ SG_ 1124 PSD_Sys_Geschwindigkeit_Einheit "Unterscheidung zwischen km/h und miles/h";
CM_ SG_ 1124 PSD_Steigung_1_A_Offset "Positionsoffset im Segment für die Position der Steigung 1 A";
CM_ SG_ 1124 PSD_Sys_Verkehrsrichtung "Unterscheidung zwischen Linksverkehr und Rechtsverkehr";
CM_ SG_ 1124 PSD_Sys_Geometrieguete "Maß für die Güte der Klothoidengeometrie.";
CM_ SG_ 1124 PSD_Sys_Mapmatchingguete "Güte des Mapmatchings";
CM_ SG_ 1124 PSD_Attribut_3_Wert "Wert des dritten Attributes";
CM_ SG_ 1124 PSD_Ges_Typ "Typ der Geschwindigkeitsbegrenzung
";
CM_ SG_ 1124 PSD_Sys_Alter_Karte "Alter der Karte";
CM_ SG_ 1124 PSD_Ges_Spur_Geschw_Begrenzung "Definition der Spuren, für die das übertragene Gebot gilt";
CM_ SG_ 1124 PSD_Steigung_1_B_Steigung "Steigung des Segments ab Offset 1B";
CM_ SG_ 1124 PSD_Attribut_4_ID "Typ von Attribut 4";
CM_ SG_ 1124 PSD_Sys_Zielfuehrung "Zielfuehrung im Navigationssystem. Damit lässt sich der wahrscheinlichste Pfad des Fahrzeuges zuverlässig angeben.";
CM_ SG_ 1124 PSD_Sys_US_State "Name des USA-State";
CM_ SG_ 1124 PSD_Ges_Geschwindigkeit_Gespann "Gilt diese Einschränkung der Geschwindigkeit für alle Fahrzeuge oder ausschließlich für PKW mit Gespann oder für LKW, Buss, etc.";
CM_ SG_ 1124 PSD_Baum_Breite_VZ "Vorzeichen WGS84 Breite des Fahrzeugsegments";
CM_ SG_ 1124 PSD_Attribut_4_Wert "Wert von Attribut 4";
CM_ SG_ 1124 PSD_Baum_Breite "WGS84 Breite des Fahrzeugsegments";
CM_ SG_ 1124 PSD_Ges_Geschwindigkeit_Witter "Witterungsabhängigkeit der Geschwindigkeitsbegrenzung";
CM_ SG_ 1124 PSD_Steigung_1_B_Vorz "Vorzeichen für Steigung 1 B";
CM_ SG_ 1124 PSD_Steigung_1_B_Offset "Positionsoffset im Segment für die Position der Steigung 1 B";
CM_ SG_ 1124 PSD_Ges_Geschwindigkeit_Tag_Anf "Wochentag, an dem die tägliche Geschwindigkeitsbegrenzung beginnt";
CM_ SG_ 1124 PSD_Attribut_4_Offset "Offset von Attribut 4";
CM_ SG_ 1124 PSD_Ges_Geschwindigkeit_Tag_Ende "Wochentag, an dem die tägliche Geschwindigkeitsbegrenzung endet";
CM_ SG_ 1124 PSD_Ges_Geschwindigkeit_Std_Anf "Stunde, zu der die stündliche Geschwindigkeitsbegrenzung beginnt
0h.. 24h";
CM_ SG_ 1124 PSD_Steigung_1_Attribute_kompl "Alle Steigungsdaten für dieses Segment gesendet";
CM_ SG_ 1124 PSD_Steigung_2_Segment_ID "Identifier des prädiktiven Streckensegments, zu dem der dritte Steigungswert dieser Botschaft gehört";
CM_ SG_ 1124 PSD_Attribut_5_ID "Typ von Attribut 5";
CM_ SG_ 1124 PSD_Ges_Geschwindigkeit_Std_Ende "Stunde, an der die stündliche Geschwindigkeitsbegrenzung endet
0h.. 24h";
CM_ SG_ 1124 PSD_Attribut_5_Offset "Offset von Attribut 5";
CM_ SG_ 1124 PSD_Steigung_2_Steigung "Steigung des Segments ab Offset 2";
CM_ SG_ 1124 PSD_Ges_Wechselverkehrszeichen "Am Beginn des Segments ist ein Wechselverkehrszeichen angebracht.";
CM_ SG_ 1124 PSD_Attribut_5_Wert "Wert von Attribut 5";
CM_ SG_ 1124 PSD_Steigung_2_Vorz "Vorzeichen für Steigung 2";
CM_ SG_ 1124 PSD_Wechselverkehrszeichen_Typ "Typ des Wechselverkehrszeichen";
CM_ SG_ 1124 PSD_Baum_Ausrichtung "Ausrichtung des Fahrzeugsegments zu Nord";
CM_ SG_ 1124 PSD_Steigung_2_Offset "Positionsoffset im Segment für die Position der Steigung 2";
CM_ SG_ 1124 PSD_Ges_Gesetzlich_Kategorie "Kategorie für das legale Gebot";
CM_ SG_ 1124 PSD_Attribute_Komplett_06 "Zeigt, ob alle Attribute für das Segment übertragen worden sind
";
CM_ SG_ 1124 PSD_Ges_Gesetzlich_Zusatz "Zusatz für das legale Gebot";
CM_ SG_ 1124 PSD_Ges_Verkehrszeichen_Quelle "Quelle der Verkehrszeicheninformation";
CM_ SG_ 1124 PSD_Steigung_2_Attribute_kompl "Alle Steigungsdaten für dieses Segment gesendet";
CM_ SG_ 1124 PSD_Ges_Attribute_Komplett "Zeigt, ob alle Attribute für das Segment übertragen worden sind";
BA_DEF_ BO_  "DiagRequest" ENUM  "No","Yes";
BA_DEF_ BO_  "DiagResponse" ENUM  "No","Yes";
BA_DEF_ BO_  "DiagState" ENUM  "No","Yes";
BA_DEF_ BO_  "GenMsgChkConstant" HEX 0 4095;
BA_DEF_ BO_  "GenMsgCycleTime" INT 0 65535;
BA_DEF_ BO_  "GenMsgCycleTimeFast" INT 0 65535;
BA_DEF_ BO_  "GenMsgDelayTime" INT 0 100000;
BA_DEF_ BO_  "GenMsgILSupport" ENUM  "No","Yes";
BA_DEF_ BO_  "GenMsgNrOfRepetition" INT 0 100;
BA_DEF_ BO_  "GenMsgPDUConstants" STRING ;
BA_DEF_ BO_  "GenMsgSendType" ENUM  "Cyclic","not_used","not_used","not_used","not_used","not_used","not_used","IfActive","NoMsgSendType";
BA_DEF_ BO_  "GenMsgStartDelayTime" INT 0 100000;
BA_DEF_ BO_  "NmMessage" ENUM  "No","Yes";
BA_DEF_ BO_  "NmhMessage" ENUM  "No","Yes";
BA_DEF_ BO_  "MsgType" ENUM  "Application","NM ","NMH","TP2.0","ISO-TP ","BAP","EID";
BA_DEF_ BO_  "VAGTP20_API" HEX 0 255;
BA_DEF_ BO_  "VAGTP20_DynConnection" ENUM  "No","Yes";
BA_DEF_ BO_  "VAGTP20_DynSetup" ENUM  "No","Yes";
BA_DEF_ BO_  "VAGTP20_StatConnection" ENUM  "No","Yes";
BA_DEF_ SG_  "GenSigActiveRepetitions" INT -2147483648 2147483647;
BA_DEF_ SG_  "GenSigInactiveValue" INT -2147483648 2147483647;
BA_DEF_ SG_  "GenSigSendType" ENUM  "Cyclic","OnWrite","OnWriteWithRepetition","OnChange","OnChangeWithRepetition","IfActive","IfActiveWithRepetition","NoSigSendType","OnChangeAndIfActive","OnChangeAndIfActiveWithRepetition";
BA_DEF_ SG_  "GenSigStartValue" INT -2147483648 2147483647;
BA_DEF_ SG_  "NWM-WakeupAllowed" ENUM  "No","Yes";
BA_DEF_ SG_  "GenSigFuncType" ENUM  "NoFunction","MsgCounter","CRC-8","XOR","XOR-2","DatedBit","SW-Kl15","CHK","Constant","Protocol","CRC-8-SAE_J1850";
BA_DEF_ SG_  "GenSigSwitchedByIgnition" ENUM  "No","Yes";
BA_DEF_ SG_  "Fehlerwert" HEX 0 2147483647;
BA_DEF_ SG_  "GenSigMissingSourceValue" HEX 0 2147483647;
BA_DEF_REL_ BU_SG_REL_  "GenSigTimeoutTime" INT 0 65535;
BA_DEF_DEF_  "DiagRequest" "No";
BA_DEF_DEF_  "DiagResponse" "No";
BA_DEF_DEF_  "DiagState" "No";
BA_DEF_DEF_  "GenMsgChkConstant" 0;
BA_DEF_DEF_  "GenMsgCycleTime" 0;
BA_DEF_DEF_  "GenMsgCycleTimeFast" 0;
BA_DEF_DEF_  "GenMsgDelayTime" 0;
BA_DEF_DEF_  "GenMsgILSupport" "No";
BA_DEF_DEF_  "GenMsgNrOfRepetition" 0;
BA_DEF_DEF_  "GenMsgPDUConstants" "";
BA_DEF_DEF_  "GenMsgSendType" "NoMsgSendType";
BA_DEF_DEF_  "GenMsgStartDelayTime" 0;
BA_DEF_DEF_  "NmMessage" "No";
BA_DEF_DEF_  "NmhMessage" "No";
BA_DEF_DEF_  "MsgType" "Application";
BA_DEF_DEF_  "VAGTP20_API" 0;
BA_DEF_DEF_  "VAGTP20_DynConnection" "No";
BA_DEF_DEF_  "VAGTP20_DynSetup" "No";
BA_DEF_DEF_  "VAGTP20_StatConnection" "No";
BA_DEF_DEF_  "GenSigActiveRepetitions" 0;
BA_DEF_DEF_  "GenSigInactiveValue" 0;
BA_DEF_DEF_  "GenSigSendType" "NoSigSendType";
BA_DEF_DEF_  "GenSigStartValue" 0;
BA_DEF_DEF_  "NWM-WakeupAllowed" "No";
BA_DEF_DEF_  "GenSigFuncType" "NoFunction";
BA_DEF_DEF_  "GenSigSwitchedByIgnition" "Yes";
BA_DEF_DEF_  "Fehlerwert" 0;
BA_DEF_DEF_  "GenSigMissingSourceValue" 0;
BA_DEF_DEF_REL_ "GenSigTimeoutTime" 0;
BA_ "MsgType" BO_ 2600468629 2;
BA_ "NmhMessage" BO_ 2600468629 1;
BA_ "GenMsgSendType" BO_ 2600468629 7;
BA_ "GenMsgNrOfRepetition" BO_ 2600468629 3;
BA_ "GenMsgCycleTimeFast" BO_ 2600468629 10;
BA_ "GenMsgCycleTime" BO_ 2600468629 200;
BA_ "MsgType" BO_ 2600468516 2;
BA_ "NmhMessage" BO_ 2600468516 1;
BA_ "GenMsgSendType" BO_ 2600468516 7;
BA_ "GenMsgNrOfRepetition" BO_ 2600468516 3;
BA_ "GenMsgCycleTimeFast" BO_ 2600468516 10;
BA_ "GenMsgCycleTime" BO_ 2600468516 200;
BA_ "MsgType" BO_ 2600468523 2;
BA_ "NmhMessage" BO_ 2600468523 1;
BA_ "GenMsgSendType" BO_ 2600468523 7;
BA_ "GenMsgNrOfRepetition" BO_ 2600468523 3;
BA_ "GenMsgCycleTimeFast" BO_ 2600468523 10;
BA_ "GenMsgCycleTime" BO_ 2600468523 200;
BA_ "MsgType" BO_ 2600468555 2;
BA_ "NmhMessage" BO_ 2600468555 1;
BA_ "GenMsgSendType" BO_ 2600468555 7;
BA_ "GenMsgNrOfRepetition" BO_ 2600468555 3;
BA_ "GenMsgCycleTimeFast" BO_ 2600468555 10;
BA_ "GenMsgCycleTime" BO_ 2600468555 200;
BA_ "MsgType" BO_ 2600468554 2;
BA_ "NmhMessage" BO_ 2600468554 1;
BA_ "GenMsgSendType" BO_ 2600468554 7;
BA_ "GenMsgNrOfRepetition" BO_ 2600468554 3;
BA_ "GenMsgCycleTimeFast" BO_ 2600468554 10;
BA_ "GenMsgCycleTime" BO_ 2600468554 200;
BA_ "MsgType" BO_ 2600468525 2;
BA_ "NmhMessage" BO_ 2600468525 1;
BA_ "GenMsgSendType" BO_ 2600468525 7;
BA_ "GenMsgNrOfRepetition" BO_ 2600468525 3;
BA_ "GenMsgCycleTimeFast" BO_ 2600468525 10;
BA_ "GenMsgCycleTime" BO_ 2600468525 200;
BA_ "GenMsgSendType" BO_ 1377 0;
BA_ "GenMsgILSupport" BO_ 1377 1;
BA_ "GenMsgDelayTime" BO_ 1377 40;
BA_ "GenMsgCycleTime" BO_ 1377 200;
BA_ "GenMsgSendType" BO_ 1635 0;
BA_ "GenMsgILSupport" BO_ 1635 1;
BA_ "GenMsgCycleTime" BO_ 1635 100;
BA_ "GenMsgSendType" BO_ 913 0;
BA_ "GenMsgILSupport" BO_ 913 1;
BA_ "GenMsgCycleTime" BO_ 913 500;
BA_ "GenMsgSendType" BO_ 1630 0;
BA_ "GenMsgILSupport" BO_ 1630 1;
BA_ "GenMsgCycleTime" BO_ 1630 500;
BA_ "MsgType" BO_ 2549875271 4;
BA_ "MsgType" BO_ 2550006343 4;
BA_ "MsgType" BO_ 2549875214 4;
BA_ "MsgType" BO_ 2550006286 4;
BA_ "MsgType" BO_ 2549875339 4;
BA_ "MsgType" BO_ 2550006411 4;
BA_ "MsgType" BO_ 2549875249 4;
BA_ "MsgType" BO_ 2550006321 4;
BA_ "MsgType" BO_ 2549875235 4;
BA_ "MsgType" BO_ 2550006307 4;
BA_ "MsgType" BO_ 2549875250 4;
BA_ "MsgType" BO_ 2550006322 4;
BA_ "MsgType" BO_ 2549875330 4;
BA_ "MsgType" BO_ 2550006402 4;
BA_ "MsgType" BO_ 2549875331 4;
BA_ "MsgType" BO_ 2550006403 4;
BA_ "MsgType" BO_ 2549875350 4;
BA_ "MsgType" BO_ 2550006422 4;
BA_ "MsgType" BO_ 2549875351 4;
BA_ "MsgType" BO_ 2550006423 4;
BA_ "MsgType" BO_ 2549875244 4;
BA_ "MsgType" BO_ 2550006316 4;
BA_ "MsgType" BO_ 2549875360 4;
BA_ "MsgType" BO_ 2550006432 4;
BA_ "MsgType" BO_ 2549875332 4;
BA_ "MsgType" BO_ 2550006404 4;
BA_ "MsgType" BO_ 2549875355 4;
BA_ "MsgType" BO_ 2550006427 4;
BA_ "MsgType" BO_ 2549875277 4;
BA_ "MsgType" BO_ 2550006349 4;
BA_ "MsgType" BO_ 2549875276 4;
BA_ "MsgType" BO_ 2550006348 4;
BA_ "MsgType" BO_ 2549875336 4;
BA_ "MsgType" BO_ 2550006408 4;
BA_ "MsgType" BO_ 2549875335 4;
BA_ "MsgType" BO_ 2550006407 4;
BA_ "MsgType" BO_ 2549875349 4;
BA_ "MsgType" BO_ 2550006421 4;
BA_ "MsgType" BO_ 2549875236 4;
BA_ "MsgType" BO_ 2550006308 4;
BA_ "MsgType" BO_ 2549875243 4;
BA_ "MsgType" BO_ 2550006315 4;
BA_ "MsgType" BO_ 2549875275 4;
BA_ "MsgType" BO_ 2550006347 4;
BA_ "MsgType" BO_ 2549875274 4;
BA_ "MsgType" BO_ 2550006346 4;
BA_ "MsgType" BO_ 2549875263 4;
BA_ "MsgType" BO_ 2550006335 4;
BA_ "MsgType" BO_ 2549875262 4;
BA_ "MsgType" BO_ 2550006334 4;
BA_ "MsgType" BO_ 2549875245 4;
BA_ "MsgType" BO_ 2550006317 4;
BA_ "GenMsgSendType" BO_ 872 0;
BA_ "GenMsgILSupport" BO_ 872 1;
BA_ "GenMsgDelayTime" BO_ 872 40;
BA_ "GenMsgCycleTime" BO_ 872 100;
BA_ "GenMsgSendType" BO_ 1175 0;
BA_ "GenMsgILSupport" BO_ 1175 1;
BA_ "GenMsgDelayTime" BO_ 1175 50;
BA_ "GenMsgCycleTime" BO_ 1175 100;
BA_ "GenMsgSendType" BO_ 2527679498 0;
BA_ "GenMsgNrOfRepetition" BO_ 2527679498 3;
BA_ "GenMsgILSupport" BO_ 2527679498 1;
BA_ "GenMsgDelayTime" BO_ 2527679498 50;
BA_ "GenMsgCycleTimeFast" BO_ 2527679498 200;
BA_ "GenMsgCycleTime" BO_ 2527679498 1000;
BA_ "GenMsgSendType" BO_ 304 0;
BA_ "GenMsgPDUConstants" BO_ 304 "0x31,0x31,0x31,0x31,0x31,0x31,0x31,0x31,0x31,0x31,0x31,0x31,0x31,0x31,0x31,0x31";
BA_ "GenMsgNrOfRepetition" BO_ 304 5;
BA_ "GenMsgILSupport" BO_ 304 1;
BA_ "GenMsgDelayTime" BO_ 304 20;
BA_ "GenMsgCycleTimeFast" BO_ 304 20;
BA_ "GenMsgCycleTime" BO_ 304 1000;
BA_ "GenMsgChkConstant" BO_ 304 49;
BA_ "GenMsgSendType" BO_ 342 0;
BA_ "GenMsgPDUConstants" BO_ 342 "0xdf,0xbd,0x46,0x8e,0x30,0x7b,0x91,0x1e,0x87,0x39,0x88,0xb3,0x0a,0xd7,0xce,0x75";
BA_ "GenMsgNrOfRepetition" BO_ 342 5;
BA_ "GenMsgILSupport" BO_ 342 1;
BA_ "GenMsgCycleTimeFast" BO_ 342 20;
BA_ "GenMsgCycleTime" BO_ 342 1000;
BA_ "GenMsgSendType" BO_ 1166 0;
BA_ "GenMsgILSupport" BO_ 1166 1;
BA_ "GenMsgCycleTime" BO_ 1166 100;
BA_ "GenMsgSendType" BO_ 319 0;
BA_ "GenMsgILSupport" BO_ 319 1;
BA_ "GenMsgDelayTime" BO_ 319 20;
BA_ "GenMsgCycleTime" BO_ 319 200;
BA_ "GenMsgSendType" BO_ 1122 0;
BA_ "GenMsgILSupport" BO_ 1122 1;
BA_ "GenMsgCycleTime" BO_ 1122 150;
BA_ "GenMsgSendType" BO_ 1123 0;
BA_ "GenMsgILSupport" BO_ 1123 1;
BA_ "GenMsgCycleTime" BO_ 1123 150;
BA_ "GenMsgSendType" BO_ 1124 0;
BA_ "GenMsgILSupport" BO_ 1124 1;
BA_ "GenMsgCycleTime" BO_ 1124 150;
BA_ "GenSigSwitchedByIgnition" SG_ 2600468629 NM_Sitzmemo_SR3_SNI 0;
BA_ "GenSigStartValue" SG_ 2600468629 NM_Sitzmemo_SR3_SNI 149;
BA_ "GenSigSwitchedByIgnition" SG_ 2600468629 NM_Sitzmemo_SR3_CBV_AWB 0;
BA_ "GenSigSwitchedByIgnition" SG_ 2600468629 NM_Sitzmemo_SR3_CBV_CRI 0;
BA_ "GenSigFuncType" SG_ 2600468629 NM_Sitzmemo_SR3_CBV_CRI 8;
BA_ "GenSigSwitchedByIgnition" SG_ 2600468629 NM_Sitzmemo_SR3_NM_State 0;
BA_ "GenSigSwitchedByIgnition" SG_ 2600468629 NM_Sitzmemo_SR3_Car_Wakeup 0;
BA_ "GenSigSendType" SG_ 2600468629 NM_Sitzmemo_SR3_Car_Wakeup 3;
BA_ "GenSigSwitchedByIgnition" SG_ 2600468629 NM_Sitzmemo_SR3_UDS_CC 0;
BA_ "GenSigSwitchedByIgnition" SG_ 2600468629 NM_Sitzmemo_SR3_NM_aktiv_KL15 0;
BA_ "GenSigSwitchedByIgnition" SG_ 2600468629 NM_Sitzmemo_SR3_NM_aktiv_Diag 0;
BA_ "GenSigSwitchedByIgnition" SG_ 2600468629 NM_Sitzmemo_SR3_NM_aktiv_Tmin 0;
BA_ "GenSigSwitchedByIgnition" SG_ 2600468629 NM_Sitzmemo_SR3_NM_aktiv_ZStel 0;
BA_ "GenSigSwitchedByIgnition" SG_ 2600468629 NM_Sitzmemo_SR3_CAB 0;
BA_ "GenSigSendType" SG_ 2600468629 NM_Sitzmemo_SR3_CAB 4;
BA_ "GenSigActiveRepetitions" SG_ 2600468629 NM_Sitzmemo_SR3_CAB 3;
BA_ "GenSigSwitchedByIgnition" SG_ 2600468516 NM_SpoilerSG_SNI 0;
BA_ "GenSigStartValue" SG_ 2600468516 NM_SpoilerSG_SNI 36;
BA_ "GenSigSwitchedByIgnition" SG_ 2600468516 NM_SpoilerSG_CBV_AWB 0;
BA_ "GenSigSwitchedByIgnition" SG_ 2600468516 NM_SpoilerSG_CBV_CRI 0;
BA_ "GenSigFuncType" SG_ 2600468516 NM_SpoilerSG_CBV_CRI 8;
BA_ "GenSigSwitchedByIgnition" SG_ 2600468516 NM_SpoilerSG_NM_State 0;
BA_ "GenSigSwitchedByIgnition" SG_ 2600468516 NM_SpoilerSG_Car_Wakeup 0;
BA_ "GenSigSendType" SG_ 2600468516 NM_SpoilerSG_Car_Wakeup 3;
BA_ "GenSigSwitchedByIgnition" SG_ 2600468516 NM_SpoilerSG_UDS_CC 0;
BA_ "GenSigSwitchedByIgnition" SG_ 2600468516 NM_SpoilerSG_NM_aktiv_KL15 0;
BA_ "GenSigSwitchedByIgnition" SG_ 2600468516 NM_SpoilerSG_NM_aktiv_Diagnose 0;
BA_ "GenSigSwitchedByIgnition" SG_ 2600468516 NM_SpoilerSG_NM_aktiv_Tmin 0;
BA_ "GenSigSwitchedByIgnition" SG_ 2600468516 NM_SpoilerSG_CAB 0;
BA_ "GenSigSendType" SG_ 2600468516 NM_SpoilerSG_CAB 4;
BA_ "GenSigActiveRepetitions" SG_ 2600468516 NM_SpoilerSG_CAB 3;
BA_ "GenSigSwitchedByIgnition" SG_ 2600468523 NM_STS_SNI 0;
BA_ "GenSigStartValue" SG_ 2600468523 NM_STS_SNI 43;
BA_ "GenSigSwitchedByIgnition" SG_ 2600468523 NM_STS_CBV_AWB 0;
BA_ "GenSigSwitchedByIgnition" SG_ 2600468523 NM_STS_CBV_CRI 0;
BA_ "GenSigFuncType" SG_ 2600468523 NM_STS_CBV_CRI 8;
BA_ "GenSigSwitchedByIgnition" SG_ 2600468523 NM_STS_NM_State 0;
BA_ "GenSigSwitchedByIgnition" SG_ 2600468523 NM_STS_Car_Wakeup 0;
BA_ "NWM-WakeupAllowed" SG_ 2600468523 NM_STS_Car_Wakeup 1;
BA_ "GenSigSendType" SG_ 2600468523 NM_STS_Car_Wakeup 3;
BA_ "GenSigSwitchedByIgnition" SG_ 2600468523 NM_STS_UDS_CC 0;
BA_ "GenSigSwitchedByIgnition" SG_ 2600468523 NM_STS_NM_aktiv_KL15 0;
BA_ "GenSigSwitchedByIgnition" SG_ 2600468523 NM_STS_NM_aktiv_Diagnose 0;
BA_ "GenSigSwitchedByIgnition" SG_ 2600468523 NM_STS_NM_aktiv_Tmin 0;
BA_ "GenSigSwitchedByIgnition" SG_ 2600468523 NM_STS_CAB 0;
BA_ "GenSigSendType" SG_ 2600468523 NM_STS_CAB 4;
BA_ "GenSigActiveRepetitions" SG_ 2600468523 NM_STS_CAB 3;
BA_ "GenSigSwitchedByIgnition" SG_ 2600468555 NM_TSG_BFS_SNI 0;
BA_ "GenSigStartValue" SG_ 2600468555 NM_TSG_BFS_SNI 75;
BA_ "GenSigSwitchedByIgnition" SG_ 2600468555 NM_TSG_BFS_CBV_AWB 0;
BA_ "GenSigSwitchedByIgnition" SG_ 2600468555 NM_TSG_BFS_CBV_CRI 0;
BA_ "GenSigFuncType" SG_ 2600468555 NM_TSG_BFS_CBV_CRI 8;
BA_ "GenSigSwitchedByIgnition" SG_ 2600468555 NM_TSG_BFS_NM_State 0;
BA_ "GenSigSwitchedByIgnition" SG_ 2600468555 NM_TSG_BFS_Car_Wakeup 0;
BA_ "GenSigSendType" SG_ 2600468555 NM_TSG_BFS_Car_Wakeup 3;
BA_ "GenSigSwitchedByIgnition" SG_ 2600468555 NM_TSG_BFS_UDS_CC 0;
BA_ "GenSigSwitchedByIgnition" SG_ 2600468555 NM_TSG_BFS_NM_aktiv_KL15 0;
BA_ "GenSigSwitchedByIgnition" SG_ 2600468555 NM_TSG_BFS_NM_aktiv_Diagnose 0;
BA_ "GenSigSwitchedByIgnition" SG_ 2600468555 NM_TSG_BFS_NM_aktiv_Tmin 0;
BA_ "GenSigSwitchedByIgnition" SG_ 2600468555 NM_TSG_BFS_NM_aktiv_Taster 0;
BA_ "GenSigSwitchedByIgnition" SG_ 2600468555 NM_TSG_BFS_NM_aktiv_LIN 0;
BA_ "GenSigSwitchedByIgnition" SG_ 2600468555 NM_TSG_BFS_NM_aktiv_Bordsteinfkt 0;
BA_ "GenSigSendType" SG_ 2600468555 NM_TSG_BFS_NM_aktiv_Bordsteinfkt 5;
BA_ "GenSigSwitchedByIgnition" SG_ 2600468555 NM_TSG_BFS_NM_aktiv_EC_Spiegel 0;
BA_ "GenSigSendType" SG_ 2600468555 NM_TSG_BFS_NM_aktiv_EC_Spiegel 5;
BA_ "GenSigSwitchedByIgnition" SG_ 2600468555 NM_TSG_BFS_NM_aktiv_Spiegelhzg 0;
BA_ "GenSigSendType" SG_ 2600468555 NM_TSG_BFS_NM_aktiv_Spiegelhzg 5;
BA_ "GenSigSwitchedByIgnition" SG_ 2600468555 NM_TSG_BFS_CAB 0;
BA_ "GenSigSendType" SG_ 2600468555 NM_TSG_BFS_CAB 4;
BA_ "GenSigActiveRepetitions" SG_ 2600468555 NM_TSG_BFS_CAB 3;
BA_ "GenSigSwitchedByIgnition" SG_ 2600468554 NM_TSG_FS_SNI 0;
BA_ "GenSigStartValue" SG_ 2600468554 NM_TSG_FS_SNI 74;
BA_ "GenSigSwitchedByIgnition" SG_ 2600468554 NM_TSG_FS_CBV_AWB 0;
BA_ "GenSigSwitchedByIgnition" SG_ 2600468554 NM_TSG_FS_CBV_CRI 0;
BA_ "GenSigFuncType" SG_ 2600468554 NM_TSG_FS_CBV_CRI 8;
BA_ "GenSigSwitchedByIgnition" SG_ 2600468554 NM_TSG_FS_NM_State 0;
BA_ "GenSigSwitchedByIgnition" SG_ 2600468554 NM_TSG_FS_Car_Wakeup 0;
BA_ "GenSigSendType" SG_ 2600468554 NM_TSG_FS_Car_Wakeup 3;
BA_ "GenSigSwitchedByIgnition" SG_ 2600468554 NM_TSG_FS_UDS_CC 0;
BA_ "GenSigSwitchedByIgnition" SG_ 2600468554 NM_TSG_FS_NM_aktiv_KL15 0;
BA_ "GenSigSwitchedByIgnition" SG_ 2600468554 NM_TSG_FS_NM_aktiv_Diagnose 0;
BA_ "GenSigSwitchedByIgnition" SG_ 2600468554 NM_TSG_FS_NM_aktiv_Tmin 0;
BA_ "GenSigSwitchedByIgnition" SG_ 2600468554 NM_TSG_FS_NM_aktiv_Taster 0;
BA_ "GenSigSwitchedByIgnition" SG_ 2600468554 NM_TSG_FS_NM_aktiv_LIN 0;
BA_ "GenSigSwitchedByIgnition" SG_ 2600468554 NM_TSG_FS_CAB 0;
BA_ "GenSigSendType" SG_ 2600468554 NM_TSG_FS_CAB 4;
BA_ "GenSigActiveRepetitions" SG_ 2600468554 NM_TSG_FS_CAB 3;
BA_ "GenSigSwitchedByIgnition" SG_ 2600468525 NM_VSG_SNI 0;
BA_ "GenSigStartValue" SG_ 2600468525 NM_VSG_SNI 45;
BA_ "GenSigSwitchedByIgnition" SG_ 2600468525 NM_VSG_CBV_AWB 0;
BA_ "GenSigSwitchedByIgnition" SG_ 2600468525 NM_VSG_CBV_CRI 0;
BA_ "GenSigFuncType" SG_ 2600468525 NM_VSG_CBV_CRI 8;
BA_ "GenSigSwitchedByIgnition" SG_ 2600468525 NM_VSG_NM_State 0;
BA_ "GenSigSwitchedByIgnition" SG_ 2600468525 NM_VSG_Car_Wakeup 0;
BA_ "GenSigSendType" SG_ 2600468525 NM_VSG_Car_Wakeup 3;
BA_ "GenSigSwitchedByIgnition" SG_ 2600468525 NM_VSG_UDS_CC 0;
BA_ "GenSigSwitchedByIgnition" SG_ 2600468525 NM_VSG_NM_aktiv_KL15 0;
BA_ "GenSigSwitchedByIgnition" SG_ 2600468525 NM_VSG_NM_aktiv_Diagnose 0;
BA_ "GenSigSwitchedByIgnition" SG_ 2600468525 NM_VSG_NM_aktiv_Tmin 0;
BA_ "GenSigSwitchedByIgnition" SG_ 2600468525 NM_VSG_CAB 0;
BA_ "GenSigSendType" SG_ 2600468525 NM_VSG_CAB 4;
BA_ "GenSigActiveRepetitions" SG_ 2600468525 NM_VSG_CAB 3;
BA_ "GenSigStartValue" SG_ 1377 NV_Obj_01_InvTTCBildebStdA 127;
BA_ "GenSigSendType" SG_ 1377 NV_Obj_01_InvTTCBildebStdA 0;
BA_ "GenSigSendType" SG_ 1377 NV_Obj_Warnung_Fussgaenger 3;
BA_ "GenSigSendType" SG_ 1377 NV_Obj_Rechts 3;
BA_ "GenSigSendType" SG_ 1377 NV_Obj_Links 3;
BA_ "GenSigStartValue" SG_ 1377 NV_Obj_01_Klasse 15;
BA_ "GenSigSendType" SG_ 1377 NV_Obj_01_Klasse 3;
BA_ "GenSigStartValue" SG_ 1377 NV_MessZeitpunkt 8191;
BA_ "GenSigSendType" SG_ 1377 NV_MessZeitpunkt 0;
BA_ "GenSigStartValue" SG_ 1377 NV_Sensor_PositionY 2047;
BA_ "GenSigSendType" SG_ 1377 NV_Sensor_PositionY 0;
BA_ "GenSigStartValue" SG_ 1377 NV_Sensor_PositionX 4095;
BA_ "GenSigSendType" SG_ 1377 NV_Sensor_PositionX 0;
BA_ "GenSigStartValue" SG_ 1377 NV_Sensor_PositionZ 2047;
BA_ "GenSigSendType" SG_ 1377 NV_Sensor_PositionZ 0;
BA_ "GenSigStartValue" SG_ 1377 NV_NichtVerfuegbar 1;
BA_ "GenSigSendType" SG_ 1377 NV_NichtVerfuegbar 0;
BA_ "GenSigSwitchedByIgnition" SG_ 1635 BEM_02_Abschaltstufen 0;
BA_ "GenSigSendType" SG_ 1635 BEM_02_Abschaltstufen 0;
BA_ "Fehlerwert" SG_ 1635 BEM_STH_Zielzeit 15;
BA_ "GenSigSwitchedByIgnition" SG_ 1635 BEM_STH_Zielzeit 0;
BA_ "GenSigStartValue" SG_ 1635 BEM_STH_Zielzeit 14;
BA_ "GenSigSendType" SG_ 1635 BEM_STH_Zielzeit 0;
BA_ "GenSigSwitchedByIgnition" SG_ 1635 BEM_MMI_Vorwarnung 0;
BA_ "GenSigSendType" SG_ 1635 BEM_MMI_Vorwarnung 0;
BA_ "GenSigSwitchedByIgnition" SG_ 1635 NVEM_Anf_SD_schalten 0;
BA_ "GenSigSendType" SG_ 1635 NVEM_Anf_SD_schalten 0;
BA_ "GenSigSwitchedByIgnition" SG_ 1635 BEM_Generatordiagnose 0;
BA_ "GenSigSendType" SG_ 1635 BEM_Generatordiagnose 0;
BA_ "GenSigSwitchedByIgnition" SG_ 1635 BEM_Red_Innengeblaese 0;
BA_ "GenSigSendType" SG_ 1635 BEM_Red_Innengeblaese 0;
BA_ "GenSigSwitchedByIgnition" SG_ 1635 BEM_STH_Einschaltverbot 0;
BA_ "GenSigSendType" SG_ 1635 BEM_STH_Einschaltverbot 0;
BA_ "GenSigSwitchedByIgnition" SG_ 1635 BEM_HL_Regelung_Status 0;
BA_ "GenSigSendType" SG_ 1635 BEM_HL_Regelung_Status 0;
BA_ "Fehlerwert" SG_ 1635 BEM_Ladezustand 15;
BA_ "GenSigSwitchedByIgnition" SG_ 1635 BEM_Ladezustand 0;
BA_ "GenSigStartValue" SG_ 1635 BEM_Ladezustand 14;
BA_ "GenSigSendType" SG_ 1635 BEM_Ladezustand 0;
BA_ "Fehlerwert" SG_ 1635 BEM_Batteriediagnose 7;
BA_ "GenSigSwitchedByIgnition" SG_ 1635 BEM_Batteriediagnose 0;
BA_ "GenSigSendType" SG_ 1635 BEM_Batteriediagnose 0;
BA_ "GenSigSwitchedByIgnition" SG_ 1635 MIB_Stromsparmodus 0;
BA_ "GenSigSendType" SG_ 1635 MIB_Stromsparmodus 0;
BA_ "GenSigSwitchedByIgnition" SG_ 1635 BEM_REK_aktiv 0;
BA_ "GenSigSendType" SG_ 1635 BEM_REK_aktiv 0;
BA_ "Fehlerwert" SG_ 1635 BEM_UBDM 255;
BA_ "GenSigSwitchedByIgnition" SG_ 1635 BEM_UBDM 0;
BA_ "GenSigSendType" SG_ 1635 BEM_UBDM 0;
BA_ "GenSigSwitchedByIgnition" SG_ 1635 BEM_UGenSoll 0;
BA_ "GenSigSendType" SG_ 1635 BEM_UGenSoll 0;
BA_ "GenSigSwitchedByIgnition" SG_ 1635 BEM_Anf_KL15_schalten 0;
BA_ "GenSigSendType" SG_ 1635 BEM_Anf_KL15_schalten 0;
BA_ "GenSigSwitchedByIgnition" SG_ 1635 NVEM_Batterie_Service 0;
BA_ "GenSigSendType" SG_ 1635 NVEM_Batterie_Service 0;
BA_ "GenSigSwitchedByIgnition" SG_ 913 OBD_Calc_Load_Val 0;
BA_ "GenSigStartValue" SG_ 913 OBD_Calc_Load_Val 255;
BA_ "GenSigSendType" SG_ 913 OBD_Calc_Load_Val 0;
BA_ "GenSigSwitchedByIgnition" SG_ 913 OBD_Eng_Cool_Temp 0;
BA_ "GenSigStartValue" SG_ 913 OBD_Eng_Cool_Temp 255;
BA_ "GenSigSendType" SG_ 913 OBD_Eng_Cool_Temp 0;
BA_ "GenSigSwitchedByIgnition" SG_ 913 OBD_Abs_Throttle_Pos 0;
BA_ "GenSigStartValue" SG_ 913 OBD_Abs_Throttle_Pos 255;
BA_ "GenSigSendType" SG_ 913 OBD_Abs_Throttle_Pos 0;
BA_ "GenSigSwitchedByIgnition" SG_ 913 OBD_Abs_Load_Val 0;
BA_ "GenSigStartValue" SG_ 913 OBD_Abs_Load_Val 65535;
BA_ "GenSigSendType" SG_ 913 OBD_Abs_Load_Val 0;
BA_ "GenSigSwitchedByIgnition" SG_ 913 OBD_Abs_Pedal_Pos 0;
BA_ "GenSigStartValue" SG_ 913 OBD_Abs_Pedal_Pos 255;
BA_ "GenSigSendType" SG_ 913 OBD_Abs_Pedal_Pos 0;
BA_ "GenSigSwitchedByIgnition" SG_ 913 MO_Servicemodus 0;
BA_ "GenSigSendType" SG_ 913 MO_Servicemodus 0;
BA_ "GenSigSwitchedByIgnition" SG_ 913 MO_QBit_Aussen_Temp 0;
BA_ "GenSigStartValue" SG_ 913 MO_QBit_Aussen_Temp 1;
BA_ "GenSigSendType" SG_ 913 MO_QBit_Aussen_Temp 0;
BA_ "GenSigSwitchedByIgnition" SG_ 913 OBD_Sperrung_IUMPR 0;
BA_ "GenSigSendType" SG_ 913 OBD_Sperrung_IUMPR 0;
BA_ "GenSigSwitchedByIgnition" SG_ 913 OBD_Kaltstart_Denominator 0;
BA_ "GenSigSendType" SG_ 913 OBD_Kaltstart_Denominator 0;
BA_ "GenSigSwitchedByIgnition" SG_ 913 OBD_Minimum_Trip 0;
BA_ "GenSigSendType" SG_ 913 OBD_Minimum_Trip 0;
BA_ "GenSigSwitchedByIgnition" SG_ 913 OBD_Driving_Cycle 0;
BA_ "GenSigSendType" SG_ 913 OBD_Driving_Cycle 0;
BA_ "GenSigSwitchedByIgnition" SG_ 913 OBD_Warm_Up_Cycle 0;
BA_ "GenSigSendType" SG_ 913 OBD_Warm_Up_Cycle 0;
BA_ "GenSigSwitchedByIgnition" SG_ 913 OBD_Normed_Trip 0;
BA_ "GenSigSendType" SG_ 913 OBD_Normed_Trip 0;
BA_ "GenSigSwitchedByIgnition" SG_ 1630 OBD_TG_F_Status_1 0;
BA_ "GenSigSendType" SG_ 1630 OBD_TG_F_Status_1 0;
BA_ "GenSigSwitchedByIgnition" SG_ 1630 OBD_TG_F_Status_2 0;
BA_ "GenSigSendType" SG_ 1630 OBD_TG_F_Status_2 0;
BA_ "GenSigSwitchedByIgnition" SG_ 1630 OBD_TG_F_Status_3 0;
BA_ "GenSigSendType" SG_ 1630 OBD_TG_F_Status_3 0;
BA_ "GenSigSwitchedByIgnition" SG_ 1630 OBD_TG_F_Status_4 0;
BA_ "GenSigSendType" SG_ 1630 OBD_TG_F_Status_4 0;
BA_ "GenSigSwitchedByIgnition" SG_ 1630 OBD_TG_Sens_Rohwert_1 0;
BA_ "GenSigSendType" SG_ 1630 OBD_TG_Sens_Rohwert_1 0;
BA_ "GenSigSwitchedByIgnition" SG_ 1630 OBD_TG_Sens_Rohwert_2 0;
BA_ "GenSigSendType" SG_ 1630 OBD_TG_Sens_Rohwert_2 0;
BA_ "GenSigSwitchedByIgnition" SG_ 1630 OBD_TG_Sens_Rohwert_3 0;
BA_ "GenSigSendType" SG_ 1630 OBD_TG_Sens_Rohwert_3 0;
BA_ "GenSigSwitchedByIgnition" SG_ 1630 OBD_TG_Sens_Rohwert_4 0;
BA_ "GenSigSendType" SG_ 1630 OBD_TG_Sens_Rohwert_4 0;
BA_ "GenSigSwitchedByIgnition" SG_ 2549875271 OBDC_AAG_Req_Data 0;
BA_ "GenSigSendType" SG_ 2549875271 OBDC_AAG_Req_Data 3;
BA_ "GenSigSwitchedByIgnition" SG_ 2550006343 OBDC_AAG_Resp_Data 0;
BA_ "GenSigSendType" SG_ 2550006343 OBDC_AAG_Resp_Data 3;
BA_ "GenSigSwitchedByIgnition" SG_ 2549875214 OBDC_BCM1_Req_Data 0;
BA_ "GenSigSendType" SG_ 2549875214 OBDC_BCM1_Req_Data 3;
BA_ "GenSigSwitchedByIgnition" SG_ 2550006286 OBDC_BCM1_Resp_Data 0;
BA_ "GenSigSendType" SG_ 2550006286 OBDC_BCM1_Resp_Data 3;
BA_ "GenSigSwitchedByIgnition" SG_ 2549875339 OBDC_BCM2_Req_Data 0;
BA_ "GenSigSendType" SG_ 2549875339 OBDC_BCM2_Req_Data 3;
BA_ "GenSigSwitchedByIgnition" SG_ 2550006411 OBDC_BCM2_Resp_Data 0;
BA_ "GenSigSendType" SG_ 2550006411 OBDC_BCM2_Resp_Data 3;
BA_ "GenSigSwitchedByIgnition" SG_ 2549875249 OBDC_ELV_Req_Data 0;
BA_ "GenSigSendType" SG_ 2549875249 OBDC_ELV_Req_Data 3;
BA_ "GenSigSwitchedByIgnition" SG_ 2550006321 OBDC_ELV_Resp_Data 0;
BA_ "GenSigSendType" SG_ 2550006321 OBDC_ELV_Resp_Data 3;
BA_ "GenSigSwitchedByIgnition" SG_ 2549875235 OBDC_HDSG_Req_Data 0;
BA_ "GenSigSendType" SG_ 2549875235 OBDC_HDSG_Req_Data 3;
BA_ "GenSigSwitchedByIgnition" SG_ 2550006307 OBDC_HDSG_Resp_Data 0;
BA_ "GenSigSendType" SG_ 2550006307 OBDC_HDSG_Resp_Data 3;
BA_ "GenSigSwitchedByIgnition" SG_ 2549875250 OBDC_Kessy_Req_Data 0;
BA_ "GenSigSendType" SG_ 2549875250 OBDC_Kessy_Req_Data 3;
BA_ "GenSigSwitchedByIgnition" SG_ 2550006322 OBDC_Kessy_Resp_Data 0;
BA_ "GenSigSendType" SG_ 2550006322 OBDC_Kessy_Resp_Data 3;
BA_ "GenSigSwitchedByIgnition" SG_ 2549875330 OBDC_LCM_L_Req_Data 0;
BA_ "GenSigSendType" SG_ 2549875330 OBDC_LCM_L_Req_Data 3;
BA_ "GenSigSwitchedByIgnition" SG_ 2550006402 OBDC_LCM_L_Resp_Data 0;
BA_ "GenSigSendType" SG_ 2550006402 OBDC_LCM_L_Resp_Data 3;
BA_ "GenSigSwitchedByIgnition" SG_ 2549875331 OBDC_LCM_R_Req_Data 0;
BA_ "GenSigSendType" SG_ 2549875331 OBDC_LCM_R_Req_Data 3;
BA_ "GenSigSwitchedByIgnition" SG_ 2550006403 OBDC_LCM_R_Resp_Data 0;
BA_ "GenSigSendType" SG_ 2550006403 OBDC_LCM_R_Resp_Data 3;
BA_ "GenSigSwitchedByIgnition" SG_ 2549875350 OBDC_LED_LM_L_Req_Data 0;
BA_ "GenSigSendType" SG_ 2549875350 OBDC_LED_LM_L_Req_Data 3;
BA_ "GenSigSwitchedByIgnition" SG_ 2550006422 OBDC_LED_LM_L_Resp_Data 0;
BA_ "GenSigSendType" SG_ 2550006422 OBDC_LED_LM_L_Resp_Data 3;
BA_ "GenSigSwitchedByIgnition" SG_ 2549875351 OBDC_LED_LM_R_Req_Data 0;
BA_ "GenSigSendType" SG_ 2549875351 OBDC_LED_LM_R_Req_Data 3;
BA_ "GenSigSwitchedByIgnition" SG_ 2550006423 OBDC_LED_LM_R_Resp_Data 0;
BA_ "GenSigSendType" SG_ 2550006423 OBDC_LED_LM_R_Resp_Data 3;
BA_ "GenSigSwitchedByIgnition" SG_ 2549875244 OBDC_MFG_Req_Data 0;
BA_ "GenSigSendType" SG_ 2549875244 OBDC_MFG_Req_Data 3;
BA_ "GenSigSwitchedByIgnition" SG_ 2550006316 OBDC_MFG_Resp_Data 0;
BA_ "GenSigSendType" SG_ 2550006316 OBDC_MFG_Resp_Data 3;
BA_ "GenSigSwitchedByIgnition" SG_ 2549875360 OBDC_SAD2_Req_Data 0;
BA_ "GenSigSendType" SG_ 2549875360 OBDC_SAD2_Req_Data 3;
BA_ "GenSigSwitchedByIgnition" SG_ 2550006432 OBDC_SAD2_Resp_Data 0;
BA_ "GenSigSendType" SG_ 2550006432 OBDC_SAD2_Resp_Data 3;
BA_ "GenSigSwitchedByIgnition" SG_ 2549875332 OBDC_SAD_Req_Data 0;
BA_ "GenSigSendType" SG_ 2549875332 OBDC_SAD_Req_Data 3;
BA_ "GenSigSwitchedByIgnition" SG_ 2550006404 OBDC_SAD_Resp_Data 0;
BA_ "GenSigSendType" SG_ 2550006404 OBDC_SAD_Resp_Data 3;
BA_ "GenSigSwitchedByIgnition" SG_ 2549875355 OBDC_MSBBR_Req_Data 0;
BA_ "GenSigSendType" SG_ 2549875355 OBDC_MSBBR_Req_Data 3;
BA_ "GenSigSwitchedByIgnition" SG_ 2550006427 OBDC_MSBBR_Resp_Data 0;
BA_ "GenSigSendType" SG_ 2550006427 OBDC_MSBBR_Resp_Data 3;
BA_ "GenSigSwitchedByIgnition" SG_ 2549875277 OBDC_Sitzmemo_BFS_Req_Data 0;
BA_ "GenSigSendType" SG_ 2549875277 OBDC_Sitzmemo_BFS_Req_Data 3;
BA_ "GenSigSwitchedByIgnition" SG_ 2550006349 OBDC_Sitzmemo_BFS_Resp_Data 0;
BA_ "GenSigSendType" SG_ 2550006349 OBDC_Sitzmemo_BFS_Resp_Data 3;
BA_ "GenSigSwitchedByIgnition" SG_ 2549875276 OBDC_Sitzmemo_FS_Req_Data 0;
BA_ "GenSigSendType" SG_ 2549875276 OBDC_Sitzmemo_FS_Req_Data 3;
BA_ "GenSigSwitchedByIgnition" SG_ 2550006348 OBDC_Sitzmemo_FS_Resp_Data 0;
BA_ "GenSigSendType" SG_ 2550006348 OBDC_Sitzmemo_FS_Resp_Data 3;
BA_ "GenSigSwitchedByIgnition" SG_ 2549875336 OBDC_Sitzmemo_HBFS_Req_Data 0;
BA_ "GenSigSendType" SG_ 2549875336 OBDC_Sitzmemo_HBFS_Req_Data 3;
BA_ "GenSigSwitchedByIgnition" SG_ 2550006408 OBDC_Sitzmemo_HBFS_Resp_Data 0;
BA_ "GenSigSendType" SG_ 2550006408 OBDC_Sitzmemo_HBFS_Resp_Data 3;
BA_ "GenSigSwitchedByIgnition" SG_ 2549875335 OBDC_Sitzmemo_HFS_Req_Data 0;
BA_ "GenSigSendType" SG_ 2549875335 OBDC_Sitzmemo_HFS_Req_Data 3;
BA_ "GenSigSwitchedByIgnition" SG_ 2550006407 OBDC_Sitzmemo_HFS_Resp_Data 0;
BA_ "GenSigSendType" SG_ 2550006407 OBDC_Sitzmemo_HFS_Resp_Data 3;
BA_ "GenSigSwitchedByIgnition" SG_ 2549875349 OBDC_Sitzmemo_SR3_Req_Data 0;
BA_ "GenSigSendType" SG_ 2549875349 OBDC_Sitzmemo_SR3_Req_Data 3;
BA_ "GenSigSwitchedByIgnition" SG_ 2550006421 OBDC_Sitzmemo_SR3_Resp_Data 0;
BA_ "GenSigSendType" SG_ 2550006421 OBDC_Sitzmemo_SR3_Resp_Data 3;
BA_ "GenSigSwitchedByIgnition" SG_ 2549875236 OBDC_SpoilerSG_Req_Data 0;
BA_ "GenSigSendType" SG_ 2549875236 OBDC_SpoilerSG_Req_Data 3;
BA_ "GenSigSwitchedByIgnition" SG_ 2550006308 OBDC_SpoilerSG_Resp_Data 0;
BA_ "GenSigSendType" SG_ 2550006308 OBDC_SpoilerSG_Resp_Data 3;
BA_ "GenSigSwitchedByIgnition" SG_ 2549875243 OBDC_STS_Req_Data 0;
BA_ "GenSigSendType" SG_ 2549875243 OBDC_STS_Req_Data 3;
BA_ "GenSigSwitchedByIgnition" SG_ 2550006315 OBDC_STS_Resp_Data 0;
BA_ "GenSigSendType" SG_ 2550006315 OBDC_STS_Resp_Data 3;
BA_ "GenSigSwitchedByIgnition" SG_ 2549875275 OBDC_TSG_BT_Req_Data 0;
BA_ "GenSigSendType" SG_ 2549875275 OBDC_TSG_BT_Req_Data 3;
BA_ "GenSigSwitchedByIgnition" SG_ 2550006347 OBDC_TSG_BT_Resp_Data 0;
BA_ "GenSigSendType" SG_ 2550006347 OBDC_TSG_BT_Resp_Data 3;
BA_ "GenSigSwitchedByIgnition" SG_ 2549875274 OBDC_TSG_FT_Req_Data 0;
BA_ "GenSigSendType" SG_ 2549875274 OBDC_TSG_FT_Req_Data 3;
BA_ "GenSigSwitchedByIgnition" SG_ 2550006346 OBDC_TSG_FT_Resp_Data 0;
BA_ "GenSigSendType" SG_ 2550006346 OBDC_TSG_FT_Resp_Data 3;
BA_ "GenSigSwitchedByIgnition" SG_ 2549875263 OBDC_TSG_HBFS_Req_Data 0;
BA_ "GenSigFuncType" SG_ 2549875263 OBDC_TSG_HBFS_Req_Data 9;
BA_ "GenSigSendType" SG_ 2549875263 OBDC_TSG_HBFS_Req_Data 3;
BA_ "GenSigSwitchedByIgnition" SG_ 2550006335 OBDC_TSG_HBFS_Resp_Data 0;
BA_ "GenSigFuncType" SG_ 2550006335 OBDC_TSG_HBFS_Resp_Data 9;
BA_ "GenSigSendType" SG_ 2550006335 OBDC_TSG_HBFS_Resp_Data 3;
BA_ "GenSigSwitchedByIgnition" SG_ 2549875262 OBDC_TSG_HFS_Req_Data 0;
BA_ "GenSigFuncType" SG_ 2549875262 OBDC_TSG_HFS_Req_Data 9;
BA_ "GenSigSendType" SG_ 2549875262 OBDC_TSG_HFS_Req_Data 3;
BA_ "GenSigSwitchedByIgnition" SG_ 2550006334 OBDC_TSG_HFS_Resp_Data 0;
BA_ "GenSigFuncType" SG_ 2550006334 OBDC_TSG_HFS_Resp_Data 9;
BA_ "GenSigSendType" SG_ 2550006334 OBDC_TSG_HFS_Resp_Data 3;
BA_ "GenSigSwitchedByIgnition" SG_ 2549875245 OBDC_VSG_Req_Data 0;
BA_ "GenSigSendType" SG_ 2549875245 OBDC_VSG_Req_Data 3;
BA_ "GenSigSwitchedByIgnition" SG_ 2550006317 OBDC_VSG_Resp_Data 0;
BA_ "GenSigSendType" SG_ 2550006317 OBDC_VSG_Resp_Data 3;
BA_ "Fehlerwert" SG_ 872 PH2_Visualisierung 7;
BA_ "GenSigStartValue" SG_ 872 PH2_Visualisierung 6;
BA_ "GenSigSendType" SG_ 872 PH2_Visualisierung 3;
BA_ "GenSigSendType" SG_ 872 PH2_nachtr_Stopp_An 3;
BA_ "GenSigSendType" SG_ 872 PH2_Abschaltursache 3;
BA_ "GenSigSendType" SG_ 872 PH2_Opt_Anzeige_V_ein 3;
BA_ "GenSigSendType" SG_ 872 PH2_Opt_Anzeige_H_ein 3;
BA_ "GenSigSendType" SG_ 872 PH2_Opt_Anz_V_Hindernis 3;
BA_ "GenSigSendType" SG_ 872 PH2_Opt_Anz_H_Hindernis 3;
BA_ "GenSigSendType" SG_ 872 PH2_Tongeber_V_aktiv 3;
BA_ "GenSigSendType" SG_ 872 PH2_Tongeber_H_aktiv 3;
BA_ "GenSigSendType" SG_ 872 PH2_Tongeber_mute 3;
BA_ "GenSigSendType" SG_ 872 PH2_Anf_Audioabsenkung 3;
BA_ "GenSigSendType" SG_ 872 PH2_Tongeber_H_verfuegbar 3;
BA_ "Fehlerwert" SG_ 872 PH2_Taster 3;
BA_ "GenSigSendType" SG_ 872 PH2_Taster 3;
BA_ "GenSigSendType" SG_ 872 PH2_Anf_Verdeck 3;
BA_ "GenSigSendType" SG_ 872 PH2_Frequenz_hinten 3;
BA_ "GenSigSendType" SG_ 872 PH2_Lautstaerke_hinten 3;
BA_ "GenSigSendType" SG_ 872 PH2_Frequenz_vorn 3;
BA_ "GenSigSendType" SG_ 872 PH2_Lautstaerke_vorn 3;
BA_ "GenSigSendType" SG_ 872 PH2_StartStopp_Info 3;
BA_ "GenSigSendType" SG_ 872 PH2_Stoermeldung 3;
BA_ "GenSigSendType" SG_ 872 PH2_defekt 3;
BA_ "GenSigSendType" SG_ 872 PH2_gestoert 3;
BA_ "GenSigSendType" SG_ 872 PH2_Systemzustand 3;
BA_ "GenSigSendType" SG_ 872 PH2_Display_Kundenwunsch 3;
BA_ "GenSigSendType" SG_ 872 APS2_Tongeber_defekt 3;
BA_ "Fehlerwert" SG_ 1175 PH_Visualisierung 7;
BA_ "GenSigStartValue" SG_ 1175 PH_Visualisierung 6;
BA_ "GenSigSendType" SG_ 1175 PH_Visualisierung 3;
BA_ "GenSigSwitchedByIgnition" SG_ 1175 PDC_Tonausgabe_Front 0;
BA_ "GenSigSendType" SG_ 1175 PDC_Tonausgabe_Front 3;
BA_ "GenSigSwitchedByIgnition" SG_ 1175 PDC_Tonausgabe_Heck 0;
BA_ "GenSigSendType" SG_ 1175 PDC_Tonausgabe_Heck 3;
BA_ "GenSigSendType" SG_ 1175 PH_nachtr_Stopp_Anf 3;
BA_ "GenSigSendType" SG_ 1175 PH_Abschaltursache 3;
BA_ "GenSigSendType" SG_ 1175 PH_Opt_Anzeige_V_ein 3;
BA_ "GenSigSendType" SG_ 1175 PH_Opt_Anzeige_H_ein 3;
BA_ "GenSigSendType" SG_ 1175 PH_Opt_Anz_V_Hindernis 3;
BA_ "GenSigSendType" SG_ 1175 PH_Opt_Anz_H_Hindernis 3;
BA_ "GenSigSendType" SG_ 1175 PH_Tongeber_V_aktiv 3;
BA_ "GenSigSendType" SG_ 1175 PH_Tongeber_H_aktiv 3;
BA_ "GenSigSendType" SG_ 1175 PH_Tongeber_mute 3;
BA_ "GenSigSendType" SG_ 1175 PH_Anf_Audioabsenkung 3;
BA_ "GenSigSendType" SG_ 1175 PH_Tongeber_H_verfuegbar 3;
BA_ "GenSigSendType" SG_ 1175 PLA_Anf_Aufschaltung_RVC 3;
BA_ "Fehlerwert" SG_ 1175 PH_Taster 3;
BA_ "GenSigSendType" SG_ 1175 PH_Taster 3;
BA_ "GenSigSendType" SG_ 1175 PH_Anf_Verdeck 3;
BA_ "GenSigSendType" SG_ 1175 PH_Frequenz_hinten 3;
BA_ "GenSigSendType" SG_ 1175 PH_Lautstaerke_hinten 3;
BA_ "GenSigSendType" SG_ 1175 PH_Frequenz_vorn 3;
BA_ "GenSigSendType" SG_ 1175 PH_Lautstaerke_vorn 3;
BA_ "GenSigSendType" SG_ 1175 PH_StartStopp_Info 3;
BA_ "GenSigSendType" SG_ 1175 PH_Stoermeldung 3;
BA_ "GenSigSendType" SG_ 1175 PH_defekt 3;
BA_ "GenSigSendType" SG_ 1175 PH_gestoert 3;
BA_ "GenSigSendType" SG_ 1175 PH_Systemzustand 3;
BA_ "GenSigSendType" SG_ 1175 PH_Display_Kundenwunsch 3;
BA_ "GenSigSwitchedByIgnition" SG_ 2527679498 Perso_Kontonummer 0;
BA_ "GenSigSendType" SG_ 2527679498 Perso_Kontonummer 4;
BA_ "GenSigActiveRepetitions" SG_ 2527679498 Perso_Kontonummer 3;
BA_ "GenSigSwitchedByIgnition" SG_ 2527679498 Perso_Steuerung 0;
BA_ "GenSigSendType" SG_ 2527679498 Perso_Steuerung 4;
BA_ "GenSigActiveRepetitions" SG_ 2527679498 Perso_Steuerung 3;
BA_ "GenSigSwitchedByIgnition" SG_ 2527679498 Perso_Steuerungsparameter 0;
BA_ "GenSigSendType" SG_ 2527679498 Perso_Steuerungsparameter 4;
BA_ "GenSigActiveRepetitions" SG_ 2527679498 Perso_Steuerungsparameter 3;
BA_ "GenSigSwitchedByIgnition" SG_ 2527679498 Perso_Status 0;
BA_ "GenSigSendType" SG_ 2527679498 Perso_Status 3;
BA_ "GenSigSwitchedByIgnition" SG_ 2527679498 Perso_Bedienstelle 0;
BA_ "GenSigSendType" SG_ 2527679498 Perso_Bedienstelle 4;
BA_ "GenSigActiveRepetitions" SG_ 2527679498 Perso_Bedienstelle 3;
BA_ "GenSigSwitchedByIgnition" SG_ 2527679498 Perso_Freigabe_Verstellung 0;
BA_ "GenSigSendType" SG_ 2527679498 Perso_Freigabe_Verstellung 4;
BA_ "GenSigActiveRepetitions" SG_ 2527679498 Perso_Freigabe_Verstellung 3;
BA_ "GenSigFuncType" SG_ 304 PLA_01_CRC 2;
BA_ "GenSigSendType" SG_ 304 PLA_01_CRC 0;
BA_ "GenSigFuncType" SG_ 304 PLA_01_BZ 1;
BA_ "GenSigSendType" SG_ 304 PLA_01_BZ 0;
BA_ "GenSigStartValue" SG_ 304 PLA_Status_PLA_ESP 9;
BA_ "GenSigSendType" SG_ 304 PLA_Status_PLA_ESP 0;
BA_ "GenSigStartValue" SG_ 304 PLA_Zahnstangen_Pos_Soll 4094;
BA_ "GenSigSendType" SG_ 304 PLA_Zahnstangen_Pos_Soll 0;
BA_ "GenSigSendType" SG_ 304 PLA_VZ_Zahnstangen_Pos_Soll 0;
BA_ "GenSigStartValue" SG_ 304 PLA_Status_PLA_EPS 9;
BA_ "GenSigSendType" SG_ 304 PLA_Status_PLA_EPS 0;
BA_ "Fehlerwert" SG_ 304 PLA_Bremsverzoegerung 127;
BA_ "GenSigSwitchedByIgnition" SG_ 304 PLA_Bremsverzoegerung 0;
BA_ "GenSigStartValue" SG_ 304 PLA_Bremsverzoegerung 126;
BA_ "GenSigSendType" SG_ 304 PLA_Bremsverzoegerung 3;
BA_ "GenSigSwitchedByIgnition" SG_ 304 PLA_Anf_Bremsverzoegerung 0;
BA_ "GenSigSendType" SG_ 304 PLA_Anf_Bremsverzoegerung 0;
BA_ "GenSigSwitchedByIgnition" SG_ 304 PLA_BremsMom_Verzoeg 0;
BA_ "GenSigSendType" SG_ 304 PLA_BremsMom_Verzoeg 3;
BA_ "GenSigSendType" SG_ 304 PLA_01_Signal_red_cyclic 6;
BA_ "GenSigFuncType" SG_ 342 PLA_02_CRC 2;
BA_ "GenSigSendType" SG_ 342 PLA_02_CRC 0;
BA_ "GenSigFuncType" SG_ 342 PLA_02_BZ 1;
BA_ "GenSigSendType" SG_ 342 PLA_02_BZ 0;
BA_ "GenSigSwitchedByIgnition" SG_ 342 PLA_Status_PLA_HAL 0;
BA_ "GenSigStartValue" SG_ 342 PLA_Status_PLA_HAL 9;
BA_ "GenSigSendType" SG_ 342 PLA_Status_PLA_HAL 0;
BA_ "GenSigSendType" SG_ 342 PLA_HAL_Radwinkel_Soll 0;
BA_ "GenSigSendType" SG_ 342 PLA_HAL_VZ_Radwinkel_Soll 0;
BA_ "GenSigSwitchedByIgnition" SG_ 342 PLA_Status_PLA_TSK 0;
BA_ "GenSigStartValue" SG_ 342 PLA_Status_PLA_TSK 1;
BA_ "GenSigSendType" SG_ 342 PLA_Status_PLA_TSK 0;
BA_ "Fehlerwert" SG_ 342 PLA_maximale_Geschwindigkeit 255;
BA_ "GenSigSwitchedByIgnition" SG_ 342 PLA_maximale_Geschwindigkeit 0;
BA_ "GenSigStartValue" SG_ 342 PLA_maximale_Geschwindigkeit 251;
BA_ "GenSigSendType" SG_ 342 PLA_maximale_Geschwindigkeit 0;
BA_ "GenSigSendType" SG_ 342 PLA_02_Signal_red_cyclic 6;
BA_ "GenSigSwitchedByIgnition" SG_ 1166 PLA_Status_Aktive_Seite 0;
BA_ "GenSigSendType" SG_ 1166 PLA_Status_Aktive_Seite 0;
BA_ "GenSigSwitchedByIgnition" SG_ 1166 PLA_Anf_Anzeige_Mini 0;
BA_ "GenSigSendType" SG_ 1166 PLA_Anf_Anzeige_Mini 0;
BA_ "GenSigSwitchedByIgnition" SG_ 1166 PLA_Mini_Modus 0;
BA_ "GenSigSendType" SG_ 1166 PLA_Mini_Modus 0;
BA_ "GenSigSwitchedByIgnition" SG_ 1166 PLA_Anf_Akustik 0;
BA_ "GenSigSendType" SG_ 1166 PLA_Anf_Akustik 0;
BA_ "GenSigSwitchedByIgnition" SG_ 1166 PLA_Anf_Anzeige_Schwellpfeil 0;
BA_ "GenSigSendType" SG_ 1166 PLA_Anf_Anzeige_Schwellpfeil 0;
BA_ "GenSigSwitchedByIgnition" SG_ 1166 PLA_Anf_Anzeige_Bremsfuss 0;
BA_ "GenSigSendType" SG_ 1166 PLA_Anf_Anzeige_Bremsfuss 0;
BA_ "GenSigSwitchedByIgnition" SG_ 1166 PLA_Anf_Funktionsdisclaimer 0;
BA_ "GenSigSendType" SG_ 1166 PLA_Anf_Funktionsdisclaimer 0;
BA_ "GenSigSwitchedByIgnition" SG_ 1166 PLA_Anf_Anzeigemodus 0;
BA_ "GenSigSendType" SG_ 1166 PLA_Anf_Anzeigemodus 0;
BA_ "GenSigSwitchedByIgnition" SG_ 1166 PLA_Anf_Meldungen 0;
BA_ "GenSigSendType" SG_ 1166 PLA_Anf_Meldungen 0;
BA_ "GenSigSwitchedByIgnition" SG_ 1166 PLA_Anzahl_Segmente_Schwellpfeil 0;
BA_ "GenSigSendType" SG_ 1166 PLA_Anzahl_Segmente_Schwellpfeil 0;
BA_ "GenSigSwitchedByIgnition" SG_ 1166 PLA_Status_Funktion 0;
BA_ "GenSigSendType" SG_ 1166 PLA_Status_Funktion 0;
BA_ "GenSigSwitchedByIgnition" SG_ 1166 PLA_Status_beenden_Mini 0;
BA_ "GenSigSendType" SG_ 1166 PLA_Status_beenden_Mini 0;
BA_ "GenSigSwitchedByIgnition" SG_ 1166 PLA_Status_Laengsparken_Mini 0;
BA_ "GenSigSendType" SG_ 1166 PLA_Status_Laengsparken_Mini 0;
BA_ "GenSigSwitchedByIgnition" SG_ 1166 PLA_Status_QP_Rueckw_Mini 0;
BA_ "GenSigSendType" SG_ 1166 PLA_Status_QP_Rueckw_Mini 0;
BA_ "GenSigSwitchedByIgnition" SG_ 1166 PLA_Status_QP_Vorw_Mini 0;
BA_ "GenSigSendType" SG_ 1166 PLA_Status_QP_Vorw_Mini 0;
BA_ "GenSigSendType" SG_ 319 PreCrash_Charisma_FahrPr 0;
BA_ "GenSigSendType" SG_ 319 PreCrash_Charisma_Status 0;
BA_ "GenSigSendType" SG_ 319 PreCrash_Schiebedach_schliessen 3;
BA_ "GenSigSendType" SG_ 319 PreCrash_Fenster_schliessen 3;
BA_ "GenSigSendType" SG_ 319 PreCrash_Blinken 3;
BA_ "GenSigSwitchedByIgnition" SG_ 319 SC_PreCrash_LED 0;
BA_ "GenSigSendType" SG_ 319 SC_PreCrash_LED 3;
BA_ "GenSigSwitchedByIgnition" SG_ 319 PreCrash_FS_Pneumatik_ansteuern 0;
BA_ "GenSigSendType" SG_ 319 PreCrash_FS_Pneumatik_ansteuern 3;
BA_ "GenSigSwitchedByIgnition" SG_ 319 PreCrash_BFS_Pneumatik_ansteuern 0;
BA_ "GenSigSendType" SG_ 319 PreCrash_BFS_Pneumatik_ansteuern 3;
BA_ "GenSigSwitchedByIgnition" SG_ 319 PreCrash_Fo_Pneumatik_ansteuern 0;
BA_ "GenSigSendType" SG_ 319 PreCrash_Fo_Pneumatik_ansteuern 3;
BA_ "GenSigSwitchedByIgnition" SG_ 319 PreCrash_FS_Sitzlehne_verfahren 0;
BA_ "GenSigSendType" SG_ 319 PreCrash_FS_Sitzlehne_verfahren 3;
BA_ "GenSigSwitchedByIgnition" SG_ 319 PreCrash_BFS_Sitzlehne_verfahren 0;
BA_ "GenSigSendType" SG_ 319 PreCrash_BFS_Sitzlehne_verfahren 3;
BA_ "GenSigSwitchedByIgnition" SG_ 319 PreCrash_Fo_Sitzlehne_verfahren 0;
BA_ "GenSigSendType" SG_ 319 PreCrash_Fo_Sitzlehne_verfahren 3;
BA_ "GenSigSwitchedByIgnition" SG_ 319 PreCrash_FS_KSV_verfahren 0;
BA_ "GenSigSendType" SG_ 319 PreCrash_FS_KSV_verfahren 3;
BA_ "GenSigSwitchedByIgnition" SG_ 319 PreCrash_BFS_KSV_verfahren 0;
BA_ "GenSigSendType" SG_ 319 PreCrash_BFS_KSV_verfahren 3;
BA_ "GenSigSwitchedByIgnition" SG_ 319 PreCrash_Fo_KSV_verfahren 0;
BA_ "GenSigSendType" SG_ 319 PreCrash_Fo_KSV_verfahren 3;
BA_ "GenSigSwitchedByIgnition" SG_ 319 SC_PreCrash_Warnung 0;
BA_ "GenSigSendType" SG_ 319 SC_PreCrash_Warnung 3;
BA_ "GenSigSwitchedByIgnition" SG_ 319 SC_PreCrash_Texte 0;
BA_ "GenSigSendType" SG_ 319 SC_PreCrash_Texte 3;
BA_ "GenSigSendType" SG_ 1122 PSD_Segment_ID 0;
BA_ "GenSigSendType" SG_ 1122 PSD_Vorgaenger_Segment_ID 0;
BA_ "GenSigSendType" SG_ 1122 PSD_Segmentlaenge 0;
BA_ "GenSigSwitchedByIgnition" SG_ 1122 PSD_Strassenkategorie 0;
BA_ "GenSigStartValue" SG_ 1122 PSD_Strassenkategorie 7;
BA_ "GenSigSendType" SG_ 1122 PSD_Strassenkategorie 0;
BA_ "GenSigSendType" SG_ 1122 PSD_Endkruemmung 0;
BA_ "GenSigSendType" SG_ 1122 PSD_Endkruemmung_Vorz 0;
BA_ "Fehlerwert" SG_ 1122 PSD_Idenditaets_ID 1;
BA_ "GenSigSendType" SG_ 1122 PSD_Idenditaets_ID 0;
BA_ "GenSigSendType" SG_ 1122 PSD_ADAS_Qualitaet 0;
BA_ "GenSigSendType" SG_ 1122 PSD_wahrscheinlichster_Pfad 0;
BA_ "GenSigSendType" SG_ 1122 PSD_Geradester_Pfad 0;
BA_ "GenSigSwitchedByIgnition" SG_ 1122 PSD_Fahrspuren_Anzahl 0;
BA_ "GenSigStartValue" SG_ 1122 PSD_Fahrspuren_Anzahl 1;
BA_ "GenSigSendType" SG_ 1122 PSD_Fahrspuren_Anzahl 0;
BA_ "GenSigSendType" SG_ 1122 PSD_Bebauung 0;
BA_ "GenSigSwitchedByIgnition" SG_ 1122 PSD_Segment_Komplett 0;
BA_ "GenSigSendType" SG_ 1122 PSD_Segment_Komplett 0;
BA_ "GenSigSendType" SG_ 1122 PSD_Rampe 0;
BA_ "GenSigSwitchedByIgnition" SG_ 1122 PSD_Anfangskruemmung 0;
BA_ "GenSigSendType" SG_ 1122 PSD_Anfangskruemmung 0;
BA_ "GenSigSwitchedByIgnition" SG_ 1122 PSD_Anfangskruemmung_Vorz 0;
BA_ "GenSigSendType" SG_ 1122 PSD_Anfangskruemmung_Vorz 0;
BA_ "GenSigSwitchedByIgnition" SG_ 1122 PSD_Abzweigerichtung 0;
BA_ "GenSigSendType" SG_ 1122 PSD_Abzweigerichtung 0;
BA_ "GenSigSwitchedByIgnition" SG_ 1122 PSD_Abzweigewinkel 0;
BA_ "GenSigSendType" SG_ 1122 PSD_Abzweigewinkel 0;
BA_ "GenSigSendType" SG_ 1123 PSD_Pos_Segment_ID 0;
BA_ "GenSigSendType" SG_ 1123 PSD_Pos_Segmentlaenge 0;
BA_ "GenSigSendType" SG_ 1123 PSD_Pos_Inhibitzeit 0;
BA_ "GenSigSendType" SG_ 1123 PSD_Pos_Standort_Eindeutig 0;
BA_ "GenSigSendType" SG_ 1123 PSD_Pos_Fehler_Laengsrichtung 0;
BA_ "GenSigSendType" SG_ 1123 PSD_Pos_Fahrspur 0;
BA_ "Fehlerwert" SG_ 1123 PSD_Attribut_Segment_ID_05 1;
BA_ "GenSigSendType" SG_ 1123 PSD_Attribut_Segment_ID_05 0;
BA_ "GenSigSendType" SG_ 1123 PSD_Attribut_1_ID 0;
BA_ "GenSigSendType" SG_ 1123 PSD_Attribut_1_Wert 0;
BA_ "GenSigSendType" SG_ 1123 PSD_Attribut_1_Offset 0;
BA_ "GenSigSendType" SG_ 1123 PSD_Attribut_2_ID 0;
BA_ "GenSigSendType" SG_ 1123 PSD_Attribut_2_Wert 0;
BA_ "GenSigSendType" SG_ 1123 PSD_Attribut_2_Offset 0;
BA_ "GenSigSendType" SG_ 1123 PSD_Attribute_Komplett_05 0;
BA_ "GenSigSwitchedByIgnition" SG_ 1124 PSD_06_Mux 0;
BA_ "NWM-WakeupAllowed" SG_ 1124 PSD_06_Mux 1;
BA_ "GenSigSendType" SG_ 1124 PSD_06_Mux 0;
BA_ "Fehlerwert" SG_ 1124 PSD_Attribut_Segment_ID 1;
BA_ "Fehlerwert" SG_ 1124 PSD_Steigung_1_Segment_ID 1;
BA_ "GenSigSwitchedByIgnition" SG_ 1124 PSD_Ges_Typ 0;
BA_ "GenSigStartValue" SG_ 1124 PSD_Ges_Typ 3;
BA_ "GenSigSwitchedByIgnition" SG_ 1124 PSD_Steigung_1_Attribute_kompl 0;
BA_ "Fehlerwert" SG_ 1124 PSD_Steigung_2_Segment_ID 1;
BA_ "GenSigSwitchedByIgnition" SG_ 1124 PSD_Attribute_Komplett_06 0;
BA_ "GenSigSwitchedByIgnition" SG_ 1124 PSD_Steigung_2_Attribute_kompl 0;
BA_REL_ "GenSigTimeoutTime" BU_SG_REL_ AAG SG_ 2600468629 NM_Sitzmemo_SR3_SNI 2000;
BA_REL_ "GenSigTimeoutTime" BU_SG_REL_ BCM1 SG_ 2600468629 NM_Sitzmemo_SR3_SNI 2000;
BA_REL_ "GenSigTimeoutTime" BU_SG_REL_ BCM2 SG_ 2600468629 NM_Sitzmemo_SR3_SNI 2000;
BA_REL_ "GenSigTimeoutTime" BU_SG_REL_ ELV SG_ 2600468629 NM_Sitzmemo_SR3_SNI 2000;
BA_REL_ "GenSigTimeoutTime" BU_SG_REL_ Gateway SG_ 2600468629 NM_Sitzmemo_SR3_SNI 2000;
BA_REL_ "GenSigTimeoutTime" BU_SG_REL_ HDSG SG_ 2600468629 NM_Sitzmemo_SR3_SNI 2000;
BA_REL_ "GenSigTimeoutTime" BU_SG_REL_ IEZS SG_ 2600468629 NM_Sitzmemo_SR3_SNI 2000;
BA_REL_ "GenSigTimeoutTime" BU_SG_REL_ MFG SG_ 2600468629 NM_Sitzmemo_SR3_SNI 2000;
BA_REL_ "GenSigTimeoutTime" BU_SG_REL_ MSBBR SG_ 2600468629 NM_Sitzmemo_SR3_SNI 2000;
BA_REL_ "GenSigTimeoutTime" BU_SG_REL_ SAD SG_ 2600468629 NM_Sitzmemo_SR3_SNI 2000;
BA_REL_ "GenSigTimeoutTime" BU_SG_REL_ SAD2 SG_ 2600468629 NM_Sitzmemo_SR3_SNI 2000;
BA_REL_ "GenSigTimeoutTime" BU_SG_REL_ SitzMem_BFS SG_ 2600468629 NM_Sitzmemo_SR3_SNI 2000;
BA_REL_ "GenSigTimeoutTime" BU_SG_REL_ SitzMem_FS SG_ 2600468629 NM_Sitzmemo_SR3_SNI 2000;
BA_REL_ "GenSigTimeoutTime" BU_SG_REL_ SitzMem_HBFS SG_ 2600468629 NM_Sitzmemo_SR3_SNI 2000;
BA_REL_ "GenSigTimeoutTime" BU_SG_REL_ SitzMem_HFS SG_ 2600468629 NM_Sitzmemo_SR3_SNI 2000;
BA_REL_ "GenSigTimeoutTime" BU_SG_REL_ SitzMem_SR3 SG_ 2600468629 NM_Sitzmemo_SR3_SNI 2000;
BA_REL_ "GenSigTimeoutTime" BU_SG_REL_ SpoilerSG SG_ 2600468629 NM_Sitzmemo_SR3_SNI 2000;
BA_REL_ "GenSigTimeoutTime" BU_SG_REL_ TSG_BFS SG_ 2600468629 NM_Sitzmemo_SR3_SNI 2000;
BA_REL_ "GenSigTimeoutTime" BU_SG_REL_ TSG_FS SG_ 2600468629 NM_Sitzmemo_SR3_SNI 2000;
BA_REL_ "GenSigTimeoutTime" BU_SG_REL_ VSG SG_ 2600468629 NM_Sitzmemo_SR3_SNI 2000;
BA_REL_ "GenSigTimeoutTime" BU_SG_REL_ VTS SG_ 2600468629 NM_Sitzmemo_SR3_SNI 2000;
BA_REL_ "GenSigTimeoutTime" BU_SG_REL_ Gateway SG_ 2600468629 NM_Sitzmemo_SR3_CBV_AWB 2000;
BA_REL_ "GenSigTimeoutTime" BU_SG_REL_ AAG SG_ 2600468629 NM_Sitzmemo_SR3_CBV_CRI 2000;
BA_REL_ "GenSigTimeoutTime" BU_SG_REL_ BCM1 SG_ 2600468629 NM_Sitzmemo_SR3_CBV_CRI 2000;
BA_REL_ "GenSigTimeoutTime" BU_SG_REL_ BCM2 SG_ 2600468629 NM_Sitzmemo_SR3_CBV_CRI 2000;
BA_REL_ "GenSigTimeoutTime" BU_SG_REL_ ELV SG_ 2600468629 NM_Sitzmemo_SR3_CBV_CRI 2000;
BA_REL_ "GenSigTimeoutTime" BU_SG_REL_ Gateway SG_ 2600468629 NM_Sitzmemo_SR3_CBV_CRI 2000;
BA_REL_ "GenSigTimeoutTime" BU_SG_REL_ HDSG SG_ 2600468629 NM_Sitzmemo_SR3_CBV_CRI 2000;
BA_REL_ "GenSigTimeoutTime" BU_SG_REL_ IEZS SG_ 2600468629 NM_Sitzmemo_SR3_CBV_CRI 2000;
BA_REL_ "GenSigTimeoutTime" BU_SG_REL_ MFG SG_ 2600468629 NM_Sitzmemo_SR3_CBV_CRI 2000;
BA_REL_ "GenSigTimeoutTime" BU_SG_REL_ MSBBR SG_ 2600468629 NM_Sitzmemo_SR3_CBV_CRI 2000;
BA_REL_ "GenSigTimeoutTime" BU_SG_REL_ SAD SG_ 2600468629 NM_Sitzmemo_SR3_CBV_CRI 2000;
BA_REL_ "GenSigTimeoutTime" BU_SG_REL_ SAD2 SG_ 2600468629 NM_Sitzmemo_SR3_CBV_CRI 2000;
BA_REL_ "GenSigTimeoutTime" BU_SG_REL_ SitzMem_BFS SG_ 2600468629 NM_Sitzmemo_SR3_CBV_CRI 2000;
BA_REL_ "GenSigTimeoutTime" BU_SG_REL_ SitzMem_FS SG_ 2600468629 NM_Sitzmemo_SR3_CBV_CRI 2000;
BA_REL_ "GenSigTimeoutTime" BU_SG_REL_ SitzMem_HBFS SG_ 2600468629 NM_Sitzmemo_SR3_CBV_CRI 2000;
BA_REL_ "GenSigTimeoutTime" BU_SG_REL_ SitzMem_HFS SG_ 2600468629 NM_Sitzmemo_SR3_CBV_CRI 2000;
BA_REL_ "GenSigTimeoutTime" BU_SG_REL_ SitzMem_SR3 SG_ 2600468629 NM_Sitzmemo_SR3_CBV_CRI 2000;
BA_REL_ "GenSigTimeoutTime" BU_SG_REL_ SpoilerSG SG_ 2600468629 NM_Sitzmemo_SR3_CBV_CRI 2000;
BA_REL_ "GenSigTimeoutTime" BU_SG_REL_ TSG_BFS SG_ 2600468629 NM_Sitzmemo_SR3_CBV_CRI 2000;
BA_REL_ "GenSigTimeoutTime" BU_SG_REL_ TSG_FS SG_ 2600468629 NM_Sitzmemo_SR3_CBV_CRI 2000;
BA_REL_ "GenSigTimeoutTime" BU_SG_REL_ VSG SG_ 2600468629 NM_Sitzmemo_SR3_CBV_CRI 2000;
BA_REL_ "GenSigTimeoutTime" BU_SG_REL_ VTS SG_ 2600468629 NM_Sitzmemo_SR3_CBV_CRI 2000;
BA_REL_ "GenSigTimeoutTime" BU_SG_REL_ Gateway SG_ 2600468629 NM_Sitzmemo_SR3_Car_Wakeup 2000;
BA_REL_ "GenSigTimeoutTime" BU_SG_REL_ AAG SG_ 2600468629 NM_Sitzmemo_SR3_CAB 2000;
BA_REL_ "GenSigTimeoutTime" BU_SG_REL_ BCM1 SG_ 2600468629 NM_Sitzmemo_SR3_CAB 2000;
BA_REL_ "GenSigTimeoutTime" BU_SG_REL_ BCM2 SG_ 2600468629 NM_Sitzmemo_SR3_CAB 2000;
BA_REL_ "GenSigTimeoutTime" BU_SG_REL_ ELV SG_ 2600468629 NM_Sitzmemo_SR3_CAB 2000;
BA_REL_ "GenSigTimeoutTime" BU_SG_REL_ Gateway SG_ 2600468629 NM_Sitzmemo_SR3_CAB 2000;
BA_REL_ "GenSigTimeoutTime" BU_SG_REL_ HDSG SG_ 2600468629 NM_Sitzmemo_SR3_CAB 2000;
BA_REL_ "GenSigTimeoutTime" BU_SG_REL_ IEZS SG_ 2600468629 NM_Sitzmemo_SR3_CAB 2000;
BA_REL_ "GenSigTimeoutTime" BU_SG_REL_ MFG SG_ 2600468629 NM_Sitzmemo_SR3_CAB 2000;
BA_REL_ "GenSigTimeoutTime" BU_SG_REL_ MSBBR SG_ 2600468629 NM_Sitzmemo_SR3_CAB 2000;
BA_REL_ "GenSigTimeoutTime" BU_SG_REL_ SAD SG_ 2600468629 NM_Sitzmemo_SR3_CAB 2000;
BA_REL_ "GenSigTimeoutTime" BU_SG_REL_ SAD2 SG_ 2600468629 NM_Sitzmemo_SR3_CAB 2000;
BA_REL_ "GenSigTimeoutTime" BU_SG_REL_ SitzMem_BFS SG_ 2600468629 NM_Sitzmemo_SR3_CAB 2000;
BA_REL_ "GenSigTimeoutTime" BU_SG_REL_ SitzMem_FS SG_ 2600468629 NM_Sitzmemo_SR3_CAB 2000;
BA_REL_ "GenSigTimeoutTime" BU_SG_REL_ SitzMem_HBFS SG_ 2600468629 NM_Sitzmemo_SR3_CAB 2000;
BA_REL_ "GenSigTimeoutTime" BU_SG_REL_ SitzMem_HFS SG_ 2600468629 NM_Sitzmemo_SR3_CAB 2000;
BA_REL_ "GenSigTimeoutTime" BU_SG_REL_ SitzMem_SR3 SG_ 2600468629 NM_Sitzmemo_SR3_CAB 2000;
BA_REL_ "GenSigTimeoutTime" BU_SG_REL_ SpoilerSG SG_ 2600468629 NM_Sitzmemo_SR3_CAB 2000;
BA_REL_ "GenSigTimeoutTime" BU_SG_REL_ TSG_BFS SG_ 2600468629 NM_Sitzmemo_SR3_CAB 2000;
BA_REL_ "GenSigTimeoutTime" BU_SG_REL_ TSG_FS SG_ 2600468629 NM_Sitzmemo_SR3_CAB 2000;
BA_REL_ "GenSigTimeoutTime" BU_SG_REL_ VSG SG_ 2600468629 NM_Sitzmemo_SR3_CAB 2000;
BA_REL_ "GenSigTimeoutTime" BU_SG_REL_ VTS SG_ 2600468629 NM_Sitzmemo_SR3_CAB 2000;
BA_REL_ "GenSigTimeoutTime" BU_SG_REL_ AAG SG_ 2600468516 NM_SpoilerSG_SNI 2000;
BA_REL_ "GenSigTimeoutTime" BU_SG_REL_ BCM1 SG_ 2600468516 NM_SpoilerSG_SNI 2000;
BA_REL_ "GenSigTimeoutTime" BU_SG_REL_ BCM2 SG_ 2600468516 NM_SpoilerSG_SNI 2000;
BA_REL_ "GenSigTimeoutTime" BU_SG_REL_ ELV SG_ 2600468516 NM_SpoilerSG_SNI 2000;
BA_REL_ "GenSigTimeoutTime" BU_SG_REL_ Gateway SG_ 2600468516 NM_SpoilerSG_SNI 2000;
BA_REL_ "GenSigTimeoutTime" BU_SG_REL_ HDSG SG_ 2600468516 NM_SpoilerSG_SNI 2000;
BA_REL_ "GenSigTimeoutTime" BU_SG_REL_ IEZS SG_ 2600468516 NM_SpoilerSG_SNI 2000;
BA_REL_ "GenSigTimeoutTime" BU_SG_REL_ MFG SG_ 2600468516 NM_SpoilerSG_SNI 2000;
BA_REL_ "GenSigTimeoutTime" BU_SG_REL_ MSBBR SG_ 2600468516 NM_SpoilerSG_SNI 2000;
BA_REL_ "GenSigTimeoutTime" BU_SG_REL_ SAD SG_ 2600468516 NM_SpoilerSG_SNI 2000;
BA_REL_ "GenSigTimeoutTime" BU_SG_REL_ SAD2 SG_ 2600468516 NM_SpoilerSG_SNI 2000;
BA_REL_ "GenSigTimeoutTime" BU_SG_REL_ SitzMem_BFS SG_ 2600468516 NM_SpoilerSG_SNI 2000;
BA_REL_ "GenSigTimeoutTime" BU_SG_REL_ SitzMem_FS SG_ 2600468516 NM_SpoilerSG_SNI 2000;
BA_REL_ "GenSigTimeoutTime" BU_SG_REL_ SitzMem_HBFS SG_ 2600468516 NM_SpoilerSG_SNI 2000;
BA_REL_ "GenSigTimeoutTime" BU_SG_REL_ SitzMem_HFS SG_ 2600468516 NM_SpoilerSG_SNI 2000;
BA_REL_ "GenSigTimeoutTime" BU_SG_REL_ SitzMem_SR3 SG_ 2600468516 NM_SpoilerSG_SNI 2000;
BA_REL_ "GenSigTimeoutTime" BU_SG_REL_ SpoilerSG SG_ 2600468516 NM_SpoilerSG_SNI 2000;
BA_REL_ "GenSigTimeoutTime" BU_SG_REL_ TSG_BFS SG_ 2600468516 NM_SpoilerSG_SNI 2000;
BA_REL_ "GenSigTimeoutTime" BU_SG_REL_ TSG_FS SG_ 2600468516 NM_SpoilerSG_SNI 2000;
BA_REL_ "GenSigTimeoutTime" BU_SG_REL_ VSG SG_ 2600468516 NM_SpoilerSG_SNI 2000;
BA_REL_ "GenSigTimeoutTime" BU_SG_REL_ VTS SG_ 2600468516 NM_SpoilerSG_SNI 2000;
BA_REL_ "GenSigTimeoutTime" BU_SG_REL_ AAG SG_ 2600468516 NM_SpoilerSG_CBV_CRI 2000;
BA_REL_ "GenSigTimeoutTime" BU_SG_REL_ BCM1 SG_ 2600468516 NM_SpoilerSG_CBV_CRI 2000;
BA_REL_ "GenSigTimeoutTime" BU_SG_REL_ BCM2 SG_ 2600468516 NM_SpoilerSG_CBV_CRI 2000;
BA_REL_ "GenSigTimeoutTime" BU_SG_REL_ ELV SG_ 2600468516 NM_SpoilerSG_CBV_CRI 2000;
BA_REL_ "GenSigTimeoutTime" BU_SG_REL_ Gateway SG_ 2600468516 NM_SpoilerSG_CBV_CRI 2000;
BA_REL_ "GenSigTimeoutTime" BU_SG_REL_ HDSG SG_ 2600468516 NM_SpoilerSG_CBV_CRI 2000;
BA_REL_ "GenSigTimeoutTime" BU_SG_REL_ IEZS SG_ 2600468516 NM_SpoilerSG_CBV_CRI 2000;
BA_REL_ "GenSigTimeoutTime" BU_SG_REL_ MFG SG_ 2600468516 NM_SpoilerSG_CBV_CRI 2000;
BA_REL_ "GenSigTimeoutTime" BU_SG_REL_ MSBBR SG_ 2600468516 NM_SpoilerSG_CBV_CRI 2000;
BA_REL_ "GenSigTimeoutTime" BU_SG_REL_ SAD SG_ 2600468516 NM_SpoilerSG_CBV_CRI 2000;
BA_REL_ "GenSigTimeoutTime" BU_SG_REL_ SAD2 SG_ 2600468516 NM_SpoilerSG_CBV_CRI 2000;
BA_REL_ "GenSigTimeoutTime" BU_SG_REL_ SitzMem_BFS SG_ 2600468516 NM_SpoilerSG_CBV_CRI 2000;
BA_REL_ "GenSigTimeoutTime" BU_SG_REL_ SitzMem_FS SG_ 2600468516 NM_SpoilerSG_CBV_CRI 2000;
BA_REL_ "GenSigTimeoutTime" BU_SG_REL_ SitzMem_HBFS SG_ 2600468516 NM_SpoilerSG_CBV_CRI 2000;
BA_REL_ "GenSigTimeoutTime" BU_SG_REL_ SitzMem_HFS SG_ 2600468516 NM_SpoilerSG_CBV_CRI 2000;
BA_REL_ "GenSigTimeoutTime" BU_SG_REL_ SitzMem_SR3 SG_ 2600468516 NM_SpoilerSG_CBV_CRI 2000;
BA_REL_ "GenSigTimeoutTime" BU_SG_REL_ SpoilerSG SG_ 2600468516 NM_SpoilerSG_CBV_CRI 2000;
BA_REL_ "GenSigTimeoutTime" BU_SG_REL_ TSG_BFS SG_ 2600468516 NM_SpoilerSG_CBV_CRI 2000;
BA_REL_ "GenSigTimeoutTime" BU_SG_REL_ TSG_FS SG_ 2600468516 NM_SpoilerSG_CBV_CRI 2000;
BA_REL_ "GenSigTimeoutTime" BU_SG_REL_ VSG SG_ 2600468516 NM_SpoilerSG_CBV_CRI 2000;
BA_REL_ "GenSigTimeoutTime" BU_SG_REL_ VTS SG_ 2600468516 NM_SpoilerSG_CBV_CRI 2000;
BA_REL_ "GenSigTimeoutTime" BU_SG_REL_ AAG SG_ 2600468516 NM_SpoilerSG_CAB 2000;
BA_REL_ "GenSigTimeoutTime" BU_SG_REL_ BCM1 SG_ 2600468516 NM_SpoilerSG_CAB 2000;
BA_REL_ "GenSigTimeoutTime" BU_SG_REL_ BCM2 SG_ 2600468516 NM_SpoilerSG_CAB 2000;
BA_REL_ "GenSigTimeoutTime" BU_SG_REL_ ELV SG_ 2600468516 NM_SpoilerSG_CAB 2000;
BA_REL_ "GenSigTimeoutTime" BU_SG_REL_ Gateway SG_ 2600468516 NM_SpoilerSG_CAB 2000;
BA_REL_ "GenSigTimeoutTime" BU_SG_REL_ HDSG SG_ 2600468516 NM_SpoilerSG_CAB 2000;
BA_REL_ "GenSigTimeoutTime" BU_SG_REL_ IEZS SG_ 2600468516 NM_SpoilerSG_CAB 2000;
BA_REL_ "GenSigTimeoutTime" BU_SG_REL_ MFG SG_ 2600468516 NM_SpoilerSG_CAB 2000;
BA_REL_ "GenSigTimeoutTime" BU_SG_REL_ MSBBR SG_ 2600468516 NM_SpoilerSG_CAB 2000;
BA_REL_ "GenSigTimeoutTime" BU_SG_REL_ SAD SG_ 2600468516 NM_SpoilerSG_CAB 2000;
BA_REL_ "GenSigTimeoutTime" BU_SG_REL_ SAD2 SG_ 2600468516 NM_SpoilerSG_CAB 2000;
BA_REL_ "GenSigTimeoutTime" BU_SG_REL_ SitzMem_BFS SG_ 2600468516 NM_SpoilerSG_CAB 2000;
BA_REL_ "GenSigTimeoutTime" BU_SG_REL_ SitzMem_FS SG_ 2600468516 NM_SpoilerSG_CAB 2000;
BA_REL_ "GenSigTimeoutTime" BU_SG_REL_ SitzMem_HBFS SG_ 2600468516 NM_SpoilerSG_CAB 2000;
BA_REL_ "GenSigTimeoutTime" BU_SG_REL_ SitzMem_HFS SG_ 2600468516 NM_SpoilerSG_CAB 2000;
BA_REL_ "GenSigTimeoutTime" BU_SG_REL_ SitzMem_SR3 SG_ 2600468516 NM_SpoilerSG_CAB 2000;
BA_REL_ "GenSigTimeoutTime" BU_SG_REL_ SpoilerSG SG_ 2600468516 NM_SpoilerSG_CAB 2000;
BA_REL_ "GenSigTimeoutTime" BU_SG_REL_ TSG_BFS SG_ 2600468516 NM_SpoilerSG_CAB 2000;
BA_REL_ "GenSigTimeoutTime" BU_SG_REL_ TSG_FS SG_ 2600468516 NM_SpoilerSG_CAB 2000;
BA_REL_ "GenSigTimeoutTime" BU_SG_REL_ VSG SG_ 2600468516 NM_SpoilerSG_CAB 2000;
BA_REL_ "GenSigTimeoutTime" BU_SG_REL_ VTS SG_ 2600468516 NM_SpoilerSG_CAB 2000;
BA_REL_ "GenSigTimeoutTime" BU_SG_REL_ AAG SG_ 2600468523 NM_STS_SNI 2000;
BA_REL_ "GenSigTimeoutTime" BU_SG_REL_ BCM1 SG_ 2600468523 NM_STS_SNI 2000;
BA_REL_ "GenSigTimeoutTime" BU_SG_REL_ BCM2 SG_ 2600468523 NM_STS_SNI 2000;
BA_REL_ "GenSigTimeoutTime" BU_SG_REL_ ELV SG_ 2600468523 NM_STS_SNI 2000;
BA_REL_ "GenSigTimeoutTime" BU_SG_REL_ Gateway SG_ 2600468523 NM_STS_SNI 2000;
BA_REL_ "GenSigTimeoutTime" BU_SG_REL_ HDSG SG_ 2600468523 NM_STS_SNI 2000;
BA_REL_ "GenSigTimeoutTime" BU_SG_REL_ IEZS SG_ 2600468523 NM_STS_SNI 2000;
BA_REL_ "GenSigTimeoutTime" BU_SG_REL_ MFG SG_ 2600468523 NM_STS_SNI 2000;
BA_REL_ "GenSigTimeoutTime" BU_SG_REL_ MSBBR SG_ 2600468523 NM_STS_SNI 2000;
BA_REL_ "GenSigTimeoutTime" BU_SG_REL_ SAD SG_ 2600468523 NM_STS_SNI 2000;
BA_REL_ "GenSigTimeoutTime" BU_SG_REL_ SAD2 SG_ 2600468523 NM_STS_SNI 2000;
BA_REL_ "GenSigTimeoutTime" BU_SG_REL_ SitzMem_BFS SG_ 2600468523 NM_STS_SNI 2000;
BA_REL_ "GenSigTimeoutTime" BU_SG_REL_ SitzMem_FS SG_ 2600468523 NM_STS_SNI 2000;
BA_REL_ "GenSigTimeoutTime" BU_SG_REL_ SitzMem_HBFS SG_ 2600468523 NM_STS_SNI 2000;
BA_REL_ "GenSigTimeoutTime" BU_SG_REL_ SitzMem_HFS SG_ 2600468523 NM_STS_SNI 2000;
BA_REL_ "GenSigTimeoutTime" BU_SG_REL_ SitzMem_SR3 SG_ 2600468523 NM_STS_SNI 2000;
BA_REL_ "GenSigTimeoutTime" BU_SG_REL_ SpoilerSG SG_ 2600468523 NM_STS_SNI 2000;
BA_REL_ "GenSigTimeoutTime" BU_SG_REL_ TSG_BFS SG_ 2600468523 NM_STS_SNI 2000;
BA_REL_ "GenSigTimeoutTime" BU_SG_REL_ TSG_FS SG_ 2600468523 NM_STS_SNI 2000;
BA_REL_ "GenSigTimeoutTime" BU_SG_REL_ VSG SG_ 2600468523 NM_STS_SNI 2000;
BA_REL_ "GenSigTimeoutTime" BU_SG_REL_ VTS SG_ 2600468523 NM_STS_SNI 2000;
BA_REL_ "GenSigTimeoutTime" BU_SG_REL_ Gateway SG_ 2600468523 NM_STS_CBV_AWB 2000;
BA_REL_ "GenSigTimeoutTime" BU_SG_REL_ AAG SG_ 2600468523 NM_STS_CBV_CRI 2000;
BA_REL_ "GenSigTimeoutTime" BU_SG_REL_ BCM1 SG_ 2600468523 NM_STS_CBV_CRI 2000;
BA_REL_ "GenSigTimeoutTime" BU_SG_REL_ BCM2 SG_ 2600468523 NM_STS_CBV_CRI 2000;
BA_REL_ "GenSigTimeoutTime" BU_SG_REL_ ELV SG_ 2600468523 NM_STS_CBV_CRI 2000;
BA_REL_ "GenSigTimeoutTime" BU_SG_REL_ Gateway SG_ 2600468523 NM_STS_CBV_CRI 2000;
BA_REL_ "GenSigTimeoutTime" BU_SG_REL_ HDSG SG_ 2600468523 NM_STS_CBV_CRI 2000;
BA_REL_ "GenSigTimeoutTime" BU_SG_REL_ IEZS SG_ 2600468523 NM_STS_CBV_CRI 2000;
BA_REL_ "GenSigTimeoutTime" BU_SG_REL_ MFG SG_ 2600468523 NM_STS_CBV_CRI 2000;
BA_REL_ "GenSigTimeoutTime" BU_SG_REL_ MSBBR SG_ 2600468523 NM_STS_CBV_CRI 2000;
BA_REL_ "GenSigTimeoutTime" BU_SG_REL_ SAD SG_ 2600468523 NM_STS_CBV_CRI 2000;
BA_REL_ "GenSigTimeoutTime" BU_SG_REL_ SAD2 SG_ 2600468523 NM_STS_CBV_CRI 2000;
BA_REL_ "GenSigTimeoutTime" BU_SG_REL_ SitzMem_BFS SG_ 2600468523 NM_STS_CBV_CRI 2000;
BA_REL_ "GenSigTimeoutTime" BU_SG_REL_ SitzMem_FS SG_ 2600468523 NM_STS_CBV_CRI 2000;
BA_REL_ "GenSigTimeoutTime" BU_SG_REL_ SitzMem_HBFS SG_ 2600468523 NM_STS_CBV_CRI 2000;
BA_REL_ "GenSigTimeoutTime" BU_SG_REL_ SitzMem_HFS SG_ 2600468523 NM_STS_CBV_CRI 2000;
BA_REL_ "GenSigTimeoutTime" BU_SG_REL_ SitzMem_SR3 SG_ 2600468523 NM_STS_CBV_CRI 2000;
BA_REL_ "GenSigTimeoutTime" BU_SG_REL_ SpoilerSG SG_ 2600468523 NM_STS_CBV_CRI 2000;
BA_REL_ "GenSigTimeoutTime" BU_SG_REL_ TSG_BFS SG_ 2600468523 NM_STS_CBV_CRI 2000;
BA_REL_ "GenSigTimeoutTime" BU_SG_REL_ TSG_FS SG_ 2600468523 NM_STS_CBV_CRI 2000;
BA_REL_ "GenSigTimeoutTime" BU_SG_REL_ VSG SG_ 2600468523 NM_STS_CBV_CRI 2000;
BA_REL_ "GenSigTimeoutTime" BU_SG_REL_ VTS SG_ 2600468523 NM_STS_CBV_CRI 2000;
BA_REL_ "GenSigTimeoutTime" BU_SG_REL_ Gateway SG_ 2600468523 NM_STS_Car_Wakeup 2000;
BA_REL_ "GenSigTimeoutTime" BU_SG_REL_ AAG SG_ 2600468523 NM_STS_CAB 2000;
BA_REL_ "GenSigTimeoutTime" BU_SG_REL_ BCM1 SG_ 2600468523 NM_STS_CAB 2000;
BA_REL_ "GenSigTimeoutTime" BU_SG_REL_ BCM2 SG_ 2600468523 NM_STS_CAB 2000;
BA_REL_ "GenSigTimeoutTime" BU_SG_REL_ ELV SG_ 2600468523 NM_STS_CAB 2000;
BA_REL_ "GenSigTimeoutTime" BU_SG_REL_ Gateway SG_ 2600468523 NM_STS_CAB 2000;
BA_REL_ "GenSigTimeoutTime" BU_SG_REL_ HDSG SG_ 2600468523 NM_STS_CAB 2000;
BA_REL_ "GenSigTimeoutTime" BU_SG_REL_ IEZS SG_ 2600468523 NM_STS_CAB 2000;
BA_REL_ "GenSigTimeoutTime" BU_SG_REL_ MFG SG_ 2600468523 NM_STS_CAB 2000;
BA_REL_ "GenSigTimeoutTime" BU_SG_REL_ MSBBR SG_ 2600468523 NM_STS_CAB 2000;
BA_REL_ "GenSigTimeoutTime" BU_SG_REL_ SAD SG_ 2600468523 NM_STS_CAB 2000;
BA_REL_ "GenSigTimeoutTime" BU_SG_REL_ SAD2 SG_ 2600468523 NM_STS_CAB 2000;
BA_REL_ "GenSigTimeoutTime" BU_SG_REL_ SitzMem_BFS SG_ 2600468523 NM_STS_CAB 2000;
BA_REL_ "GenSigTimeoutTime" BU_SG_REL_ SitzMem_FS SG_ 2600468523 NM_STS_CAB 2000;
BA_REL_ "GenSigTimeoutTime" BU_SG_REL_ SitzMem_HBFS SG_ 2600468523 NM_STS_CAB 2000;
BA_REL_ "GenSigTimeoutTime" BU_SG_REL_ SitzMem_HFS SG_ 2600468523 NM_STS_CAB 2000;
BA_REL_ "GenSigTimeoutTime" BU_SG_REL_ SitzMem_SR3 SG_ 2600468523 NM_STS_CAB 2000;
BA_REL_ "GenSigTimeoutTime" BU_SG_REL_ SpoilerSG SG_ 2600468523 NM_STS_CAB 2000;
BA_REL_ "GenSigTimeoutTime" BU_SG_REL_ TSG_BFS SG_ 2600468523 NM_STS_CAB 2000;
BA_REL_ "GenSigTimeoutTime" BU_SG_REL_ TSG_FS SG_ 2600468523 NM_STS_CAB 2000;
BA_REL_ "GenSigTimeoutTime" BU_SG_REL_ VSG SG_ 2600468523 NM_STS_CAB 2000;
BA_REL_ "GenSigTimeoutTime" BU_SG_REL_ VTS SG_ 2600468523 NM_STS_CAB 2000;
BA_REL_ "GenSigTimeoutTime" BU_SG_REL_ AAG SG_ 2600468555 NM_TSG_BFS_SNI 2000;
BA_REL_ "GenSigTimeoutTime" BU_SG_REL_ BCM1 SG_ 2600468555 NM_TSG_BFS_SNI 2000;
BA_REL_ "GenSigTimeoutTime" BU_SG_REL_ BCM2 SG_ 2600468555 NM_TSG_BFS_SNI 2000;
BA_REL_ "GenSigTimeoutTime" BU_SG_REL_ ELV SG_ 2600468555 NM_TSG_BFS_SNI 2000;
BA_REL_ "GenSigTimeoutTime" BU_SG_REL_ Gateway SG_ 2600468555 NM_TSG_BFS_SNI 2000;
BA_REL_ "GenSigTimeoutTime" BU_SG_REL_ HDSG SG_ 2600468555 NM_TSG_BFS_SNI 2000;
BA_REL_ "GenSigTimeoutTime" BU_SG_REL_ IEZS SG_ 2600468555 NM_TSG_BFS_SNI 2000;
BA_REL_ "GenSigTimeoutTime" BU_SG_REL_ MFG SG_ 2600468555 NM_TSG_BFS_SNI 2000;
BA_REL_ "GenSigTimeoutTime" BU_SG_REL_ MSBBR SG_ 2600468555 NM_TSG_BFS_SNI 2000;
BA_REL_ "GenSigTimeoutTime" BU_SG_REL_ SAD SG_ 2600468555 NM_TSG_BFS_SNI 2000;
BA_REL_ "GenSigTimeoutTime" BU_SG_REL_ SAD2 SG_ 2600468555 NM_TSG_BFS_SNI 2000;
BA_REL_ "GenSigTimeoutTime" BU_SG_REL_ SitzMem_BFS SG_ 2600468555 NM_TSG_BFS_SNI 2000;
BA_REL_ "GenSigTimeoutTime" BU_SG_REL_ SitzMem_FS SG_ 2600468555 NM_TSG_BFS_SNI 2000;
BA_REL_ "GenSigTimeoutTime" BU_SG_REL_ SitzMem_HBFS SG_ 2600468555 NM_TSG_BFS_SNI 2000;
BA_REL_ "GenSigTimeoutTime" BU_SG_REL_ SitzMem_HFS SG_ 2600468555 NM_TSG_BFS_SNI 2000;
BA_REL_ "GenSigTimeoutTime" BU_SG_REL_ SitzMem_SR3 SG_ 2600468555 NM_TSG_BFS_SNI 2000;
BA_REL_ "GenSigTimeoutTime" BU_SG_REL_ SpoilerSG SG_ 2600468555 NM_TSG_BFS_SNI 2000;
BA_REL_ "GenSigTimeoutTime" BU_SG_REL_ TSG_BFS SG_ 2600468555 NM_TSG_BFS_SNI 2000;
BA_REL_ "GenSigTimeoutTime" BU_SG_REL_ TSG_FS SG_ 2600468555 NM_TSG_BFS_SNI 2000;
BA_REL_ "GenSigTimeoutTime" BU_SG_REL_ VSG SG_ 2600468555 NM_TSG_BFS_SNI 2000;
BA_REL_ "GenSigTimeoutTime" BU_SG_REL_ VTS SG_ 2600468555 NM_TSG_BFS_SNI 2000;
BA_REL_ "GenSigTimeoutTime" BU_SG_REL_ Gateway SG_ 2600468555 NM_TSG_BFS_CBV_AWB 2000;
BA_REL_ "GenSigTimeoutTime" BU_SG_REL_ AAG SG_ 2600468555 NM_TSG_BFS_CBV_CRI 2000;
BA_REL_ "GenSigTimeoutTime" BU_SG_REL_ BCM1 SG_ 2600468555 NM_TSG_BFS_CBV_CRI 2000;
BA_REL_ "GenSigTimeoutTime" BU_SG_REL_ BCM2 SG_ 2600468555 NM_TSG_BFS_CBV_CRI 2000;
BA_REL_ "GenSigTimeoutTime" BU_SG_REL_ ELV SG_ 2600468555 NM_TSG_BFS_CBV_CRI 2000;
BA_REL_ "GenSigTimeoutTime" BU_SG_REL_ Gateway SG_ 2600468555 NM_TSG_BFS_CBV_CRI 2000;
BA_REL_ "GenSigTimeoutTime" BU_SG_REL_ HDSG SG_ 2600468555 NM_TSG_BFS_CBV_CRI 2000;
BA_REL_ "GenSigTimeoutTime" BU_SG_REL_ IEZS SG_ 2600468555 NM_TSG_BFS_CBV_CRI 2000;
BA_REL_ "GenSigTimeoutTime" BU_SG_REL_ MFG SG_ 2600468555 NM_TSG_BFS_CBV_CRI 2000;
BA_REL_ "GenSigTimeoutTime" BU_SG_REL_ MSBBR SG_ 2600468555 NM_TSG_BFS_CBV_CRI 2000;
BA_REL_ "GenSigTimeoutTime" BU_SG_REL_ SAD SG_ 2600468555 NM_TSG_BFS_CBV_CRI 2000;
BA_REL_ "GenSigTimeoutTime" BU_SG_REL_ SAD2 SG_ 2600468555 NM_TSG_BFS_CBV_CRI 2000;
BA_REL_ "GenSigTimeoutTime" BU_SG_REL_ SitzMem_BFS SG_ 2600468555 NM_TSG_BFS_CBV_CRI 2000;
BA_REL_ "GenSigTimeoutTime" BU_SG_REL_ SitzMem_FS SG_ 2600468555 NM_TSG_BFS_CBV_CRI 2000;
BA_REL_ "GenSigTimeoutTime" BU_SG_REL_ SitzMem_HBFS SG_ 2600468555 NM_TSG_BFS_CBV_CRI 2000;
BA_REL_ "GenSigTimeoutTime" BU_SG_REL_ SitzMem_HFS SG_ 2600468555 NM_TSG_BFS_CBV_CRI 2000;
BA_REL_ "GenSigTimeoutTime" BU_SG_REL_ SitzMem_SR3 SG_ 2600468555 NM_TSG_BFS_CBV_CRI 2000;
BA_REL_ "GenSigTimeoutTime" BU_SG_REL_ SpoilerSG SG_ 2600468555 NM_TSG_BFS_CBV_CRI 2000;
BA_REL_ "GenSigTimeoutTime" BU_SG_REL_ TSG_BFS SG_ 2600468555 NM_TSG_BFS_CBV_CRI 2000;
BA_REL_ "GenSigTimeoutTime" BU_SG_REL_ TSG_FS SG_ 2600468555 NM_TSG_BFS_CBV_CRI 2000;
BA_REL_ "GenSigTimeoutTime" BU_SG_REL_ VSG SG_ 2600468555 NM_TSG_BFS_CBV_CRI 2000;
BA_REL_ "GenSigTimeoutTime" BU_SG_REL_ VTS SG_ 2600468555 NM_TSG_BFS_CBV_CRI 2000;
BA_REL_ "GenSigTimeoutTime" BU_SG_REL_ Gateway SG_ 2600468555 NM_TSG_BFS_Car_Wakeup 2000;
BA_REL_ "GenSigTimeoutTime" BU_SG_REL_ AAG SG_ 2600468555 NM_TSG_BFS_CAB 2000;
BA_REL_ "GenSigTimeoutTime" BU_SG_REL_ BCM1 SG_ 2600468555 NM_TSG_BFS_CAB 2000;
BA_REL_ "GenSigTimeoutTime" BU_SG_REL_ BCM2 SG_ 2600468555 NM_TSG_BFS_CAB 2000;
BA_REL_ "GenSigTimeoutTime" BU_SG_REL_ ELV SG_ 2600468555 NM_TSG_BFS_CAB 2000;
BA_REL_ "GenSigTimeoutTime" BU_SG_REL_ Gateway SG_ 2600468555 NM_TSG_BFS_CAB 2000;
BA_REL_ "GenSigTimeoutTime" BU_SG_REL_ HDSG SG_ 2600468555 NM_TSG_BFS_CAB 2000;
BA_REL_ "GenSigTimeoutTime" BU_SG_REL_ IEZS SG_ 2600468555 NM_TSG_BFS_CAB 2000;
BA_REL_ "GenSigTimeoutTime" BU_SG_REL_ MFG SG_ 2600468555 NM_TSG_BFS_CAB 2000;
BA_REL_ "GenSigTimeoutTime" BU_SG_REL_ MSBBR SG_ 2600468555 NM_TSG_BFS_CAB 2000;
BA_REL_ "GenSigTimeoutTime" BU_SG_REL_ SAD SG_ 2600468555 NM_TSG_BFS_CAB 2000;
BA_REL_ "GenSigTimeoutTime" BU_SG_REL_ SAD2 SG_ 2600468555 NM_TSG_BFS_CAB 2000;
BA_REL_ "GenSigTimeoutTime" BU_SG_REL_ SitzMem_BFS SG_ 2600468555 NM_TSG_BFS_CAB 2000;
BA_REL_ "GenSigTimeoutTime" BU_SG_REL_ SitzMem_FS SG_ 2600468555 NM_TSG_BFS_CAB 2000;
BA_REL_ "GenSigTimeoutTime" BU_SG_REL_ SitzMem_HBFS SG_ 2600468555 NM_TSG_BFS_CAB 2000;
BA_REL_ "GenSigTimeoutTime" BU_SG_REL_ SitzMem_HFS SG_ 2600468555 NM_TSG_BFS_CAB 2000;
BA_REL_ "GenSigTimeoutTime" BU_SG_REL_ SitzMem_SR3 SG_ 2600468555 NM_TSG_BFS_CAB 2000;
BA_REL_ "GenSigTimeoutTime" BU_SG_REL_ SpoilerSG SG_ 2600468555 NM_TSG_BFS_CAB 2000;
BA_REL_ "GenSigTimeoutTime" BU_SG_REL_ TSG_BFS SG_ 2600468555 NM_TSG_BFS_CAB 2000;
BA_REL_ "GenSigTimeoutTime" BU_SG_REL_ TSG_FS SG_ 2600468555 NM_TSG_BFS_CAB 2000;
BA_REL_ "GenSigTimeoutTime" BU_SG_REL_ VSG SG_ 2600468555 NM_TSG_BFS_CAB 2000;
BA_REL_ "GenSigTimeoutTime" BU_SG_REL_ VTS SG_ 2600468555 NM_TSG_BFS_CAB 2000;
BA_REL_ "GenSigTimeoutTime" BU_SG_REL_ AAG SG_ 2600468554 NM_TSG_FS_SNI 2000;
BA_REL_ "GenSigTimeoutTime" BU_SG_REL_ BCM1 SG_ 2600468554 NM_TSG_FS_SNI 2000;
BA_REL_ "GenSigTimeoutTime" BU_SG_REL_ BCM2 SG_ 2600468554 NM_TSG_FS_SNI 2000;
BA_REL_ "GenSigTimeoutTime" BU_SG_REL_ ELV SG_ 2600468554 NM_TSG_FS_SNI 2000;
BA_REL_ "GenSigTimeoutTime" BU_SG_REL_ Gateway SG_ 2600468554 NM_TSG_FS_SNI 2000;
BA_REL_ "GenSigTimeoutTime" BU_SG_REL_ HDSG SG_ 2600468554 NM_TSG_FS_SNI 2000;
BA_REL_ "GenSigTimeoutTime" BU_SG_REL_ IEZS SG_ 2600468554 NM_TSG_FS_SNI 2000;
BA_REL_ "GenSigTimeoutTime" BU_SG_REL_ MFG SG_ 2600468554 NM_TSG_FS_SNI 2000;
BA_REL_ "GenSigTimeoutTime" BU_SG_REL_ MSBBR SG_ 2600468554 NM_TSG_FS_SNI 2000;
BA_REL_ "GenSigTimeoutTime" BU_SG_REL_ SAD SG_ 2600468554 NM_TSG_FS_SNI 2000;
BA_REL_ "GenSigTimeoutTime" BU_SG_REL_ SAD2 SG_ 2600468554 NM_TSG_FS_SNI 2000;
BA_REL_ "GenSigTimeoutTime" BU_SG_REL_ SitzMem_BFS SG_ 2600468554 NM_TSG_FS_SNI 2000;
BA_REL_ "GenSigTimeoutTime" BU_SG_REL_ SitzMem_FS SG_ 2600468554 NM_TSG_FS_SNI 2000;
BA_REL_ "GenSigTimeoutTime" BU_SG_REL_ SitzMem_HBFS SG_ 2600468554 NM_TSG_FS_SNI 2000;
BA_REL_ "GenSigTimeoutTime" BU_SG_REL_ SitzMem_HFS SG_ 2600468554 NM_TSG_FS_SNI 2000;
BA_REL_ "GenSigTimeoutTime" BU_SG_REL_ SitzMem_SR3 SG_ 2600468554 NM_TSG_FS_SNI 2000;
BA_REL_ "GenSigTimeoutTime" BU_SG_REL_ SpoilerSG SG_ 2600468554 NM_TSG_FS_SNI 2000;
BA_REL_ "GenSigTimeoutTime" BU_SG_REL_ TSG_BFS SG_ 2600468554 NM_TSG_FS_SNI 2000;
BA_REL_ "GenSigTimeoutTime" BU_SG_REL_ TSG_FS SG_ 2600468554 NM_TSG_FS_SNI 2000;
BA_REL_ "GenSigTimeoutTime" BU_SG_REL_ VSG SG_ 2600468554 NM_TSG_FS_SNI 2000;
BA_REL_ "GenSigTimeoutTime" BU_SG_REL_ VTS SG_ 2600468554 NM_TSG_FS_SNI 2000;
BA_REL_ "GenSigTimeoutTime" BU_SG_REL_ Gateway SG_ 2600468554 NM_TSG_FS_CBV_AWB 2000;
BA_REL_ "GenSigTimeoutTime" BU_SG_REL_ AAG SG_ 2600468554 NM_TSG_FS_CBV_CRI 2000;
BA_REL_ "GenSigTimeoutTime" BU_SG_REL_ BCM1 SG_ 2600468554 NM_TSG_FS_CBV_CRI 2000;
BA_REL_ "GenSigTimeoutTime" BU_SG_REL_ BCM2 SG_ 2600468554 NM_TSG_FS_CBV_CRI 2000;
BA_REL_ "GenSigTimeoutTime" BU_SG_REL_ ELV SG_ 2600468554 NM_TSG_FS_CBV_CRI 2000;
BA_REL_ "GenSigTimeoutTime" BU_SG_REL_ Gateway SG_ 2600468554 NM_TSG_FS_CBV_CRI 2000;
BA_REL_ "GenSigTimeoutTime" BU_SG_REL_ HDSG SG_ 2600468554 NM_TSG_FS_CBV_CRI 2000;
BA_REL_ "GenSigTimeoutTime" BU_SG_REL_ IEZS SG_ 2600468554 NM_TSG_FS_CBV_CRI 2000;
BA_REL_ "GenSigTimeoutTime" BU_SG_REL_ MFG SG_ 2600468554 NM_TSG_FS_CBV_CRI 2000;
BA_REL_ "GenSigTimeoutTime" BU_SG_REL_ MSBBR SG_ 2600468554 NM_TSG_FS_CBV_CRI 2000;
BA_REL_ "GenSigTimeoutTime" BU_SG_REL_ SAD SG_ 2600468554 NM_TSG_FS_CBV_CRI 2000;
BA_REL_ "GenSigTimeoutTime" BU_SG_REL_ SAD2 SG_ 2600468554 NM_TSG_FS_CBV_CRI 2000;
BA_REL_ "GenSigTimeoutTime" BU_SG_REL_ SitzMem_BFS SG_ 2600468554 NM_TSG_FS_CBV_CRI 2000;
BA_REL_ "GenSigTimeoutTime" BU_SG_REL_ SitzMem_FS SG_ 2600468554 NM_TSG_FS_CBV_CRI 2000;
BA_REL_ "GenSigTimeoutTime" BU_SG_REL_ SitzMem_HBFS SG_ 2600468554 NM_TSG_FS_CBV_CRI 2000;
BA_REL_ "GenSigTimeoutTime" BU_SG_REL_ SitzMem_HFS SG_ 2600468554 NM_TSG_FS_CBV_CRI 2000;
BA_REL_ "GenSigTimeoutTime" BU_SG_REL_ SitzMem_SR3 SG_ 2600468554 NM_TSG_FS_CBV_CRI 2000;
BA_REL_ "GenSigTimeoutTime" BU_SG_REL_ SpoilerSG SG_ 2600468554 NM_TSG_FS_CBV_CRI 2000;
BA_REL_ "GenSigTimeoutTime" BU_SG_REL_ TSG_BFS SG_ 2600468554 NM_TSG_FS_CBV_CRI 2000;
BA_REL_ "GenSigTimeoutTime" BU_SG_REL_ TSG_FS SG_ 2600468554 NM_TSG_FS_CBV_CRI 2000;
BA_REL_ "GenSigTimeoutTime" BU_SG_REL_ VSG SG_ 2600468554 NM_TSG_FS_CBV_CRI 2000;
BA_REL_ "GenSigTimeoutTime" BU_SG_REL_ VTS SG_ 2600468554 NM_TSG_FS_CBV_CRI 2000;
BA_REL_ "GenSigTimeoutTime" BU_SG_REL_ Gateway SG_ 2600468554 NM_TSG_FS_Car_Wakeup 2000;
BA_REL_ "GenSigTimeoutTime" BU_SG_REL_ AAG SG_ 2600468554 NM_TSG_FS_CAB 2000;
BA_REL_ "GenSigTimeoutTime" BU_SG_REL_ BCM1 SG_ 2600468554 NM_TSG_FS_CAB 2000;
BA_REL_ "GenSigTimeoutTime" BU_SG_REL_ BCM2 SG_ 2600468554 NM_TSG_FS_CAB 2000;
BA_REL_ "GenSigTimeoutTime" BU_SG_REL_ ELV SG_ 2600468554 NM_TSG_FS_CAB 2000;
BA_REL_ "GenSigTimeoutTime" BU_SG_REL_ Gateway SG_ 2600468554 NM_TSG_FS_CAB 2000;
BA_REL_ "GenSigTimeoutTime" BU_SG_REL_ HDSG SG_ 2600468554 NM_TSG_FS_CAB 2000;
BA_REL_ "GenSigTimeoutTime" BU_SG_REL_ IEZS SG_ 2600468554 NM_TSG_FS_CAB 2000;
BA_REL_ "GenSigTimeoutTime" BU_SG_REL_ MFG SG_ 2600468554 NM_TSG_FS_CAB 2000;
BA_REL_ "GenSigTimeoutTime" BU_SG_REL_ MSBBR SG_ 2600468554 NM_TSG_FS_CAB 2000;
BA_REL_ "GenSigTimeoutTime" BU_SG_REL_ SAD SG_ 2600468554 NM_TSG_FS_CAB 2000;
BA_REL_ "GenSigTimeoutTime" BU_SG_REL_ SAD2 SG_ 2600468554 NM_TSG_FS_CAB 2000;
BA_REL_ "GenSigTimeoutTime" BU_SG_REL_ SitzMem_BFS SG_ 2600468554 NM_TSG_FS_CAB 2000;
BA_REL_ "GenSigTimeoutTime" BU_SG_REL_ SitzMem_FS SG_ 2600468554 NM_TSG_FS_CAB 2000;
BA_REL_ "GenSigTimeoutTime" BU_SG_REL_ SitzMem_HBFS SG_ 2600468554 NM_TSG_FS_CAB 2000;
BA_REL_ "GenSigTimeoutTime" BU_SG_REL_ SitzMem_HFS SG_ 2600468554 NM_TSG_FS_CAB 2000;
BA_REL_ "GenSigTimeoutTime" BU_SG_REL_ SitzMem_SR3 SG_ 2600468554 NM_TSG_FS_CAB 2000;
BA_REL_ "GenSigTimeoutTime" BU_SG_REL_ SpoilerSG SG_ 2600468554 NM_TSG_FS_CAB 2000;
BA_REL_ "GenSigTimeoutTime" BU_SG_REL_ TSG_BFS SG_ 2600468554 NM_TSG_FS_CAB 2000;
BA_REL_ "GenSigTimeoutTime" BU_SG_REL_ TSG_FS SG_ 2600468554 NM_TSG_FS_CAB 2000;
BA_REL_ "GenSigTimeoutTime" BU_SG_REL_ VSG SG_ 2600468554 NM_TSG_FS_CAB 2000;
BA_REL_ "GenSigTimeoutTime" BU_SG_REL_ VTS SG_ 2600468554 NM_TSG_FS_CAB 2000;
BA_REL_ "GenSigTimeoutTime" BU_SG_REL_ AAG SG_ 2600468525 NM_VSG_SNI 2000;
BA_REL_ "GenSigTimeoutTime" BU_SG_REL_ BCM1 SG_ 2600468525 NM_VSG_SNI 2000;
BA_REL_ "GenSigTimeoutTime" BU_SG_REL_ BCM2 SG_ 2600468525 NM_VSG_SNI 2000;
BA_REL_ "GenSigTimeoutTime" BU_SG_REL_ ELV SG_ 2600468525 NM_VSG_SNI 2000;
BA_REL_ "GenSigTimeoutTime" BU_SG_REL_ Gateway SG_ 2600468525 NM_VSG_SNI 2000;
BA_REL_ "GenSigTimeoutTime" BU_SG_REL_ HDSG SG_ 2600468525 NM_VSG_SNI 2000;
BA_REL_ "GenSigTimeoutTime" BU_SG_REL_ IEZS SG_ 2600468525 NM_VSG_SNI 2000;
BA_REL_ "GenSigTimeoutTime" BU_SG_REL_ MFG SG_ 2600468525 NM_VSG_SNI 2000;
BA_REL_ "GenSigTimeoutTime" BU_SG_REL_ MSBBR SG_ 2600468525 NM_VSG_SNI 2000;
BA_REL_ "GenSigTimeoutTime" BU_SG_REL_ SAD SG_ 2600468525 NM_VSG_SNI 2000;
BA_REL_ "GenSigTimeoutTime" BU_SG_REL_ SAD2 SG_ 2600468525 NM_VSG_SNI 2000;
BA_REL_ "GenSigTimeoutTime" BU_SG_REL_ SitzMem_BFS SG_ 2600468525 NM_VSG_SNI 2000;
BA_REL_ "GenSigTimeoutTime" BU_SG_REL_ SitzMem_FS SG_ 2600468525 NM_VSG_SNI 2000;
BA_REL_ "GenSigTimeoutTime" BU_SG_REL_ SitzMem_HBFS SG_ 2600468525 NM_VSG_SNI 2000;
BA_REL_ "GenSigTimeoutTime" BU_SG_REL_ SitzMem_HFS SG_ 2600468525 NM_VSG_SNI 2000;
BA_REL_ "GenSigTimeoutTime" BU_SG_REL_ SitzMem_SR3 SG_ 2600468525 NM_VSG_SNI 2000;
BA_REL_ "GenSigTimeoutTime" BU_SG_REL_ SpoilerSG SG_ 2600468525 NM_VSG_SNI 2000;
BA_REL_ "GenSigTimeoutTime" BU_SG_REL_ TSG_BFS SG_ 2600468525 NM_VSG_SNI 2000;
BA_REL_ "GenSigTimeoutTime" BU_SG_REL_ TSG_FS SG_ 2600468525 NM_VSG_SNI 2000;
BA_REL_ "GenSigTimeoutTime" BU_SG_REL_ VSG SG_ 2600468525 NM_VSG_SNI 2000;
BA_REL_ "GenSigTimeoutTime" BU_SG_REL_ VTS SG_ 2600468525 NM_VSG_SNI 2000;
BA_REL_ "GenSigTimeoutTime" BU_SG_REL_ Gateway SG_ 2600468525 NM_VSG_CBV_AWB 2000;
BA_REL_ "GenSigTimeoutTime" BU_SG_REL_ AAG SG_ 2600468525 NM_VSG_CBV_CRI 2000;
BA_REL_ "GenSigTimeoutTime" BU_SG_REL_ BCM1 SG_ 2600468525 NM_VSG_CBV_CRI 2000;
BA_REL_ "GenSigTimeoutTime" BU_SG_REL_ BCM2 SG_ 2600468525 NM_VSG_CBV_CRI 2000;
BA_REL_ "GenSigTimeoutTime" BU_SG_REL_ ELV SG_ 2600468525 NM_VSG_CBV_CRI 2000;
BA_REL_ "GenSigTimeoutTime" BU_SG_REL_ Gateway SG_ 2600468525 NM_VSG_CBV_CRI 2000;
BA_REL_ "GenSigTimeoutTime" BU_SG_REL_ HDSG SG_ 2600468525 NM_VSG_CBV_CRI 2000;
BA_REL_ "GenSigTimeoutTime" BU_SG_REL_ IEZS SG_ 2600468525 NM_VSG_CBV_CRI 2000;
BA_REL_ "GenSigTimeoutTime" BU_SG_REL_ MFG SG_ 2600468525 NM_VSG_CBV_CRI 2000;
BA_REL_ "GenSigTimeoutTime" BU_SG_REL_ MSBBR SG_ 2600468525 NM_VSG_CBV_CRI 2000;
BA_REL_ "GenSigTimeoutTime" BU_SG_REL_ SAD SG_ 2600468525 NM_VSG_CBV_CRI 2000;
BA_REL_ "GenSigTimeoutTime" BU_SG_REL_ SAD2 SG_ 2600468525 NM_VSG_CBV_CRI 2000;
BA_REL_ "GenSigTimeoutTime" BU_SG_REL_ SitzMem_BFS SG_ 2600468525 NM_VSG_CBV_CRI 2000;
BA_REL_ "GenSigTimeoutTime" BU_SG_REL_ SitzMem_FS SG_ 2600468525 NM_VSG_CBV_CRI 2000;
BA_REL_ "GenSigTimeoutTime" BU_SG_REL_ SitzMem_HBFS SG_ 2600468525 NM_VSG_CBV_CRI 2000;
BA_REL_ "GenSigTimeoutTime" BU_SG_REL_ SitzMem_HFS SG_ 2600468525 NM_VSG_CBV_CRI 2000;
BA_REL_ "GenSigTimeoutTime" BU_SG_REL_ SitzMem_SR3 SG_ 2600468525 NM_VSG_CBV_CRI 2000;
BA_REL_ "GenSigTimeoutTime" BU_SG_REL_ SpoilerSG SG_ 2600468525 NM_VSG_CBV_CRI 2000;
BA_REL_ "GenSigTimeoutTime" BU_SG_REL_ TSG_BFS SG_ 2600468525 NM_VSG_CBV_CRI 2000;
BA_REL_ "GenSigTimeoutTime" BU_SG_REL_ TSG_FS SG_ 2600468525 NM_VSG_CBV_CRI 2000;
BA_REL_ "GenSigTimeoutTime" BU_SG_REL_ VSG SG_ 2600468525 NM_VSG_CBV_CRI 2000;
BA_REL_ "GenSigTimeoutTime" BU_SG_REL_ VTS SG_ 2600468525 NM_VSG_CBV_CRI 2000;
BA_REL_ "GenSigTimeoutTime" BU_SG_REL_ Gateway SG_ 2600468525 NM_VSG_Car_Wakeup 2000;
BA_REL_ "GenSigTimeoutTime" BU_SG_REL_ AAG SG_ 2600468525 NM_VSG_CAB 2000;
BA_REL_ "GenSigTimeoutTime" BU_SG_REL_ BCM1 SG_ 2600468525 NM_VSG_CAB 2000;
BA_REL_ "GenSigTimeoutTime" BU_SG_REL_ BCM2 SG_ 2600468525 NM_VSG_CAB 2000;
BA_REL_ "GenSigTimeoutTime" BU_SG_REL_ ELV SG_ 2600468525 NM_VSG_CAB 2000;
BA_REL_ "GenSigTimeoutTime" BU_SG_REL_ Gateway SG_ 2600468525 NM_VSG_CAB 2000;
BA_REL_ "GenSigTimeoutTime" BU_SG_REL_ HDSG SG_ 2600468525 NM_VSG_CAB 2000;
BA_REL_ "GenSigTimeoutTime" BU_SG_REL_ IEZS SG_ 2600468525 NM_VSG_CAB 2000;
BA_REL_ "GenSigTimeoutTime" BU_SG_REL_ MFG SG_ 2600468525 NM_VSG_CAB 2000;
BA_REL_ "GenSigTimeoutTime" BU_SG_REL_ MSBBR SG_ 2600468525 NM_VSG_CAB 2000;
BA_REL_ "GenSigTimeoutTime" BU_SG_REL_ SAD SG_ 2600468525 NM_VSG_CAB 2000;
BA_REL_ "GenSigTimeoutTime" BU_SG_REL_ SAD2 SG_ 2600468525 NM_VSG_CAB 2000;
BA_REL_ "GenSigTimeoutTime" BU_SG_REL_ SitzMem_BFS SG_ 2600468525 NM_VSG_CAB 2000;
BA_REL_ "GenSigTimeoutTime" BU_SG_REL_ SitzMem_FS SG_ 2600468525 NM_VSG_CAB 2000;
BA_REL_ "GenSigTimeoutTime" BU_SG_REL_ SitzMem_HBFS SG_ 2600468525 NM_VSG_CAB 2000;
BA_REL_ "GenSigTimeoutTime" BU_SG_REL_ SitzMem_HFS SG_ 2600468525 NM_VSG_CAB 2000;
BA_REL_ "GenSigTimeoutTime" BU_SG_REL_ SitzMem_SR3 SG_ 2600468525 NM_VSG_CAB 2000;
BA_REL_ "GenSigTimeoutTime" BU_SG_REL_ SpoilerSG SG_ 2600468525 NM_VSG_CAB 2000;
BA_REL_ "GenSigTimeoutTime" BU_SG_REL_ TSG_BFS SG_ 2600468525 NM_VSG_CAB 2000;
BA_REL_ "GenSigTimeoutTime" BU_SG_REL_ TSG_FS SG_ 2600468525 NM_VSG_CAB 2000;
BA_REL_ "GenSigTimeoutTime" BU_SG_REL_ VSG SG_ 2600468525 NM_VSG_CAB 2000;
BA_REL_ "GenSigTimeoutTime" BU_SG_REL_ VTS SG_ 2600468525 NM_VSG_CAB 2000;
BA_REL_ "GenSigTimeoutTime" BU_SG_REL_ BCM1 SG_ 1377 NV_Obj_Rechts 2000;
BA_REL_ "GenSigTimeoutTime" BU_SG_REL_ BCM1 SG_ 1377 NV_Obj_Links 2000;
BA_REL_ "GenSigTimeoutTime" BU_SG_REL_ BCM1 SG_ 1377 NV_Obj_01_Klasse 2000;
BA_REL_ "GenSigTimeoutTime" BU_SG_REL_ AAG SG_ 1635 BEM_02_Abschaltstufen 1000;
BA_REL_ "GenSigTimeoutTime" BU_SG_REL_ BCM1 SG_ 1635 BEM_02_Abschaltstufen 1000;
BA_REL_ "GenSigTimeoutTime" BU_SG_REL_ BCM2 SG_ 1635 BEM_02_Abschaltstufen 1000;
BA_REL_ "GenSigTimeoutTime" BU_SG_REL_ HDSG SG_ 1635 BEM_02_Abschaltstufen 1000;
BA_REL_ "GenSigTimeoutTime" BU_SG_REL_ IEZS SG_ 1635 BEM_02_Abschaltstufen 1000;
BA_REL_ "GenSigTimeoutTime" BU_SG_REL_ MFG SG_ 1635 BEM_02_Abschaltstufen 1000;
BA_REL_ "GenSigTimeoutTime" BU_SG_REL_ SAD SG_ 1635 BEM_02_Abschaltstufen 1000;
BA_REL_ "GenSigTimeoutTime" BU_SG_REL_ SAD2 SG_ 1635 BEM_02_Abschaltstufen 1000;
BA_REL_ "GenSigTimeoutTime" BU_SG_REL_ SitzMem_BFS SG_ 1635 BEM_02_Abschaltstufen 1000;
BA_REL_ "GenSigTimeoutTime" BU_SG_REL_ SitzMem_FS SG_ 1635 BEM_02_Abschaltstufen 1000;
BA_REL_ "GenSigTimeoutTime" BU_SG_REL_ SitzMem_HBFS SG_ 1635 BEM_02_Abschaltstufen 1000;
BA_REL_ "GenSigTimeoutTime" BU_SG_REL_ SitzMem_HFS SG_ 1635 BEM_02_Abschaltstufen 1000;
BA_REL_ "GenSigTimeoutTime" BU_SG_REL_ SitzMem_SR3 SG_ 1635 BEM_02_Abschaltstufen 1000;
BA_REL_ "GenSigTimeoutTime" BU_SG_REL_ SpoilerSG SG_ 1635 BEM_02_Abschaltstufen 1000;
BA_REL_ "GenSigTimeoutTime" BU_SG_REL_ TSG_BFS SG_ 1635 BEM_02_Abschaltstufen 1000;
BA_REL_ "GenSigTimeoutTime" BU_SG_REL_ TSG_FS SG_ 1635 BEM_02_Abschaltstufen 1000;
BA_REL_ "GenSigTimeoutTime" BU_SG_REL_ VSG SG_ 1635 BEM_02_Abschaltstufen 1000;
BA_REL_ "GenSigTimeoutTime" BU_SG_REL_ VTS SG_ 1635 BEM_02_Abschaltstufen 1000;
BA_REL_ "GenSigTimeoutTime" BU_SG_REL_ BCM1 SG_ 1635 NVEM_Anf_SD_schalten 1000;
BA_REL_ "GenSigTimeoutTime" BU_SG_REL_ MFG SG_ 1635 BEM_Generatordiagnose 1000;
BA_REL_ "GenSigTimeoutTime" BU_SG_REL_ MFG SG_ 1635 BEM_Red_Innengeblaese 1000;
BA_REL_ "GenSigTimeoutTime" BU_SG_REL_ VTS SG_ 1635 BEM_STH_Einschaltverbot 1000;
BA_REL_ "GenSigTimeoutTime" BU_SG_REL_ AAG SG_ 1635 BEM_HL_Regelung_Status 1000;
BA_REL_ "GenSigTimeoutTime" BU_SG_REL_ BCM1 SG_ 1635 BEM_HL_Regelung_Status 1000;
BA_REL_ "GenSigTimeoutTime" BU_SG_REL_ BCM2 SG_ 1635 BEM_UBDM 1000;
BA_REL_ "GenSigTimeoutTime" BU_SG_REL_ BCM2 SG_ 1635 BEM_Anf_KL15_schalten 1000;
BA_REL_ "GenSigTimeoutTime" BU_SG_REL_ BCM1 SG_ 872 PH2_Visualisierung 1000;
BA_REL_ "GenSigTimeoutTime" BU_SG_REL_ BCM1 SG_ 872 PH2_Abschaltursache 1000;
BA_REL_ "GenSigTimeoutTime" BU_SG_REL_ BCM1 SG_ 872 PH2_Opt_Anzeige_V_ein 1000;
BA_REL_ "GenSigTimeoutTime" BU_SG_REL_ BCM1 SG_ 872 PH2_Opt_Anzeige_H_ein 1000;
BA_REL_ "GenSigTimeoutTime" BU_SG_REL_ BCM1 SG_ 872 PH2_Opt_Anz_V_Hindernis 1000;
BA_REL_ "GenSigTimeoutTime" BU_SG_REL_ BCM1 SG_ 872 PH2_Opt_Anz_H_Hindernis 1000;
BA_REL_ "GenSigTimeoutTime" BU_SG_REL_ AAG SG_ 872 PH2_Systemzustand 1000;
BA_REL_ "GenSigTimeoutTime" BU_SG_REL_ BCM1 SG_ 872 PH2_Systemzustand 1000;
BA_REL_ "GenSigTimeoutTime" BU_SG_REL_ BCM1 SG_ 1175 PH_Visualisierung 1000;
BA_REL_ "GenSigTimeoutTime" BU_SG_REL_ Gateway SG_ 1175 PH_StartStopp_Info 1000;
BA_REL_ "GenSigTimeoutTime" BU_SG_REL_ AAG SG_ 1175 PH_Systemzustand 1000;
BA_REL_ "GenSigTimeoutTime" BU_SG_REL_ BCM1 SG_ 2527679498 Perso_Kontonummer 5000;
BA_REL_ "GenSigTimeoutTime" BU_SG_REL_ Gateway SG_ 2527679498 Perso_Kontonummer 5000;
BA_REL_ "GenSigTimeoutTime" BU_SG_REL_ TSG_BFS SG_ 2527679498 Perso_Kontonummer 5000;
BA_REL_ "GenSigTimeoutTime" BU_SG_REL_ TSG_FS SG_ 2527679498 Perso_Kontonummer 5000;
BA_REL_ "GenSigTimeoutTime" BU_SG_REL_ BCM1 SG_ 2527679498 Perso_Steuerung 5000;
BA_REL_ "GenSigTimeoutTime" BU_SG_REL_ Gateway SG_ 2527679498 Perso_Steuerung 5000;
BA_REL_ "GenSigTimeoutTime" BU_SG_REL_ TSG_BFS SG_ 2527679498 Perso_Steuerung 5000;
BA_REL_ "GenSigTimeoutTime" BU_SG_REL_ TSG_FS SG_ 2527679498 Perso_Steuerung 5000;
BA_REL_ "GenSigTimeoutTime" BU_SG_REL_ BCM1 SG_ 2527679498 Perso_Steuerungsparameter 5000;
BA_REL_ "GenSigTimeoutTime" BU_SG_REL_ Gateway SG_ 2527679498 Perso_Steuerungsparameter 5000;
BA_REL_ "GenSigTimeoutTime" BU_SG_REL_ TSG_BFS SG_ 2527679498 Perso_Steuerungsparameter 5000;
BA_REL_ "GenSigTimeoutTime" BU_SG_REL_ TSG_FS SG_ 2527679498 Perso_Steuerungsparameter 5000;
BA_REL_ "GenSigTimeoutTime" BU_SG_REL_ BCM1 SG_ 2527679498 Perso_Status 5000;
BA_REL_ "GenSigTimeoutTime" BU_SG_REL_ Gateway SG_ 2527679498 Perso_Status 5000;
BA_REL_ "GenSigTimeoutTime" BU_SG_REL_ TSG_BFS SG_ 2527679498 Perso_Status 5000;
BA_REL_ "GenSigTimeoutTime" BU_SG_REL_ TSG_FS SG_ 2527679498 Perso_Status 5000;
BA_REL_ "GenSigTimeoutTime" BU_SG_REL_ SitzMem_FS SG_ 2527679498 Perso_Bedienstelle 5000;
BA_REL_ "GenSigTimeoutTime" BU_SG_REL_ SitzMem_FS SG_ 2527679498 Perso_Freigabe_Verstellung 5000;
BA_REL_ "GenSigTimeoutTime" BU_SG_REL_ SAD SG_ 319 PreCrash_Schiebedach_schliessen 2000;
BA_REL_ "GenSigTimeoutTime" BU_SG_REL_ SAD2 SG_ 319 PreCrash_Schiebedach_schliessen 2000;
BA_REL_ "GenSigTimeoutTime" BU_SG_REL_ TSG_BFS SG_ 319 PreCrash_Fenster_schliessen 2000;
BA_REL_ "GenSigTimeoutTime" BU_SG_REL_ TSG_FS SG_ 319 PreCrash_Fenster_schliessen 2000;
BA_REL_ "GenSigTimeoutTime" BU_SG_REL_ BCM2 SG_ 319 PreCrash_Blinken 2000;
BA_REL_ "GenSigTimeoutTime" BU_SG_REL_ BCM1 SG_ 319 PreCrash_FS_Pneumatik_ansteuern 2000;
BA_REL_ "GenSigTimeoutTime" BU_SG_REL_ SitzMem_FS SG_ 319 PreCrash_FS_Pneumatik_ansteuern 2000;
BA_REL_ "GenSigTimeoutTime" BU_SG_REL_ BCM1 SG_ 319 PreCrash_BFS_Pneumatik_ansteuern 2000;
BA_REL_ "GenSigTimeoutTime" BU_SG_REL_ SitzMem_BFS SG_ 319 PreCrash_BFS_Pneumatik_ansteuern 2000;
BA_REL_ "GenSigTimeoutTime" BU_SG_REL_ SitzMem_HBFS SG_ 319 PreCrash_Fo_Pneumatik_ansteuern 2000;
BA_REL_ "GenSigTimeoutTime" BU_SG_REL_ SitzMem_HFS SG_ 319 PreCrash_Fo_Pneumatik_ansteuern 2000;
BA_REL_ "GenSigTimeoutTime" BU_SG_REL_ SitzMem_FS SG_ 319 PreCrash_FS_Sitzlehne_verfahren 2000;
BA_REL_ "GenSigTimeoutTime" BU_SG_REL_ SitzMem_BFS SG_ 319 PreCrash_BFS_Sitzlehne_verfahren 2000;
BA_REL_ "GenSigTimeoutTime" BU_SG_REL_ SitzMem_HBFS SG_ 319 PreCrash_Fo_Sitzlehne_verfahren 2000;
BA_REL_ "GenSigTimeoutTime" BU_SG_REL_ SitzMem_HFS SG_ 319 PreCrash_Fo_Sitzlehne_verfahren 2000;
BA_REL_ "GenSigTimeoutTime" BU_SG_REL_ SitzMem_FS SG_ 319 PreCrash_FS_KSV_verfahren 2000;
BA_REL_ "GenSigTimeoutTime" BU_SG_REL_ SitzMem_BFS SG_ 319 PreCrash_BFS_KSV_verfahren 2000;
BA_REL_ "GenSigTimeoutTime" BU_SG_REL_ SitzMem_HBFS SG_ 319 PreCrash_Fo_KSV_verfahren 2000;
BA_REL_ "GenSigTimeoutTime" BU_SG_REL_ SitzMem_HFS SG_ 319 PreCrash_Fo_KSV_verfahren 2000;
BA_REL_ "GenSigTimeoutTime" BU_SG_REL_ BCM1 SG_ 1122 PSD_Segment_ID 1500;
BA_REL_ "GenSigTimeoutTime" BU_SG_REL_ BCM1 SG_ 1122 PSD_Vorgaenger_Segment_ID 1500;
BA_REL_ "GenSigTimeoutTime" BU_SG_REL_ BCM1 SG_ 1122 PSD_Segmentlaenge 1500;
BA_REL_ "GenSigTimeoutTime" BU_SG_REL_ BCM1 SG_ 1122 PSD_Strassenkategorie 1500;
BA_REL_ "GenSigTimeoutTime" BU_SG_REL_ BCM1 SG_ 1122 PSD_Endkruemmung 1500;
BA_REL_ "GenSigTimeoutTime" BU_SG_REL_ BCM1 SG_ 1122 PSD_Endkruemmung_Vorz 1500;
BA_REL_ "GenSigTimeoutTime" BU_SG_REL_ BCM1 SG_ 1122 PSD_Idenditaets_ID 1500;
BA_REL_ "GenSigTimeoutTime" BU_SG_REL_ BCM1 SG_ 1122 PSD_ADAS_Qualitaet 1500;
BA_REL_ "GenSigTimeoutTime" BU_SG_REL_ BCM1 SG_ 1122 PSD_wahrscheinlichster_Pfad 1500;
BA_REL_ "GenSigTimeoutTime" BU_SG_REL_ BCM1 SG_ 1122 PSD_Geradester_Pfad 1500;
BA_REL_ "GenSigTimeoutTime" BU_SG_REL_ BCM1 SG_ 1122 PSD_Fahrspuren_Anzahl 1500;
BA_REL_ "GenSigTimeoutTime" BU_SG_REL_ BCM1 SG_ 1122 PSD_Bebauung 1500;
BA_REL_ "GenSigTimeoutTime" BU_SG_REL_ BCM1 SG_ 1122 PSD_Segment_Komplett 1500;
BA_REL_ "GenSigTimeoutTime" BU_SG_REL_ BCM1 SG_ 1122 PSD_Rampe 1500;
BA_REL_ "GenSigTimeoutTime" BU_SG_REL_ BCM1 SG_ 1122 PSD_Anfangskruemmung 1500;
BA_REL_ "GenSigTimeoutTime" BU_SG_REL_ BCM1 SG_ 1122 PSD_Anfangskruemmung_Vorz 1500;
BA_REL_ "GenSigTimeoutTime" BU_SG_REL_ BCM1 SG_ 1122 PSD_Abzweigerichtung 1500;
BA_REL_ "GenSigTimeoutTime" BU_SG_REL_ BCM1 SG_ 1122 PSD_Abzweigewinkel 1500;
BA_REL_ "GenSigTimeoutTime" BU_SG_REL_ BCM1 SG_ 1123 PSD_Pos_Segment_ID 1500;
BA_REL_ "GenSigTimeoutTime" BU_SG_REL_ BCM1 SG_ 1123 PSD_Pos_Segmentlaenge 1500;
BA_REL_ "GenSigTimeoutTime" BU_SG_REL_ BCM1 SG_ 1123 PSD_Pos_Inhibitzeit 1500;
BA_REL_ "GenSigTimeoutTime" BU_SG_REL_ BCM1 SG_ 1123 PSD_Pos_Standort_Eindeutig 1500;
BA_REL_ "GenSigTimeoutTime" BU_SG_REL_ BCM1 SG_ 1123 PSD_Pos_Fehler_Laengsrichtung 1500;
BA_REL_ "GenSigTimeoutTime" BU_SG_REL_ BCM1 SG_ 1123 PSD_Pos_Fahrspur 1500;
BA_REL_ "GenSigTimeoutTime" BU_SG_REL_ BCM1 SG_ 1123 PSD_Attribut_Segment_ID_05 1500;
BA_REL_ "GenSigTimeoutTime" BU_SG_REL_ BCM1 SG_ 1123 PSD_Attribut_1_ID 1500;
BA_REL_ "GenSigTimeoutTime" BU_SG_REL_ BCM1 SG_ 1123 PSD_Attribut_1_Wert 1500;
BA_REL_ "GenSigTimeoutTime" BU_SG_REL_ BCM1 SG_ 1123 PSD_Attribut_1_Offset 1500;
BA_REL_ "GenSigTimeoutTime" BU_SG_REL_ BCM1 SG_ 1123 PSD_Attribut_2_ID 1500;
BA_REL_ "GenSigTimeoutTime" BU_SG_REL_ BCM1 SG_ 1123 PSD_Attribut_2_Wert 1500;
BA_REL_ "GenSigTimeoutTime" BU_SG_REL_ BCM1 SG_ 1123 PSD_Attribut_2_Offset 1500;
BA_REL_ "GenSigTimeoutTime" BU_SG_REL_ BCM1 SG_ 1123 PSD_Attribute_Komplett_05 1500;
BA_REL_ "GenSigTimeoutTime" BU_SG_REL_ BCM1 SG_ 1124 PSD_06_Mux 1500;
BA_REL_ "GenSigTimeoutTime" BU_SG_REL_ BCM1 SG_ 1124 PSD_Sys_Segment_ID 1500;
BA_REL_ "GenSigTimeoutTime" BU_SG_REL_ BCM1 SG_ 1124 PSD_Attribut_Segment_ID 1500;
BA_REL_ "GenSigTimeoutTime" BU_SG_REL_ BCM1 SG_ 1124 PSD_Ges_Segment_ID 1500;
BA_REL_ "GenSigTimeoutTime" BU_SG_REL_ BCM1 SG_ 1124 PSD_Baum_Laenge_VZ 1500;
BA_REL_ "GenSigTimeoutTime" BU_SG_REL_ BCM1 SG_ 1124 PSD_Steigung_1_Segment_ID 1500;
BA_REL_ "GenSigTimeoutTime" BU_SG_REL_ BCM1 SG_ 1124 PSD_Baum_Laenge 1500;
BA_REL_ "GenSigTimeoutTime" BU_SG_REL_ BCM1 SG_ 1124 PSD_Sys_Laendercode 1500;
BA_REL_ "GenSigTimeoutTime" BU_SG_REL_ BCM1 SG_ 1124 PSD_Attribut_3_ID 1500;
BA_REL_ "GenSigTimeoutTime" BU_SG_REL_ BCM1 SG_ 1124 PSD_Ges_Offset 1500;
BA_REL_ "GenSigTimeoutTime" BU_SG_REL_ BCM1 SG_ 1124 PSD_Steigung_1_A_Steigung 1500;
BA_REL_ "GenSigTimeoutTime" BU_SG_REL_ BCM1 SG_ 1124 PSD_Attribut_3_Offset 1500;
BA_REL_ "GenSigTimeoutTime" BU_SG_REL_ BCM1 SG_ 1124 PSD_Ges_Geschwindigkeit 1500;
BA_REL_ "GenSigTimeoutTime" BU_SG_REL_ BCM1 SG_ 1124 PSD_Steigung_1_A_Vorz 1500;
BA_REL_ "GenSigTimeoutTime" BU_SG_REL_ BCM1 SG_ 1124 PSD_Sys_Geschwindigkeit_Einheit 1500;
BA_REL_ "GenSigTimeoutTime" BU_SG_REL_ BCM1 SG_ 1124 PSD_Steigung_1_A_Offset 1500;
BA_REL_ "GenSigTimeoutTime" BU_SG_REL_ BCM1 SG_ 1124 PSD_Sys_Verkehrsrichtung 1500;
BA_REL_ "GenSigTimeoutTime" BU_SG_REL_ BCM1 SG_ 1124 PSD_Sys_Geometrieguete 1500;
BA_REL_ "GenSigTimeoutTime" BU_SG_REL_ BCM1 SG_ 1124 PSD_Sys_Mapmatchingguete 1500;
BA_REL_ "GenSigTimeoutTime" BU_SG_REL_ BCM1 SG_ 1124 PSD_Attribut_3_Wert 1500;
BA_REL_ "GenSigTimeoutTime" BU_SG_REL_ BCM1 SG_ 1124 PSD_Ges_Typ 1500;
BA_REL_ "GenSigTimeoutTime" BU_SG_REL_ BCM1 SG_ 1124 PSD_Sys_Alter_Karte 1500;
BA_REL_ "GenSigTimeoutTime" BU_SG_REL_ BCM1 SG_ 1124 PSD_Ges_Spur_Geschw_Begrenzung 1500;
BA_REL_ "GenSigTimeoutTime" BU_SG_REL_ BCM1 SG_ 1124 PSD_Steigung_1_B_Steigung 1500;
BA_REL_ "GenSigTimeoutTime" BU_SG_REL_ BCM1 SG_ 1124 PSD_Attribut_4_ID 1500;
BA_REL_ "GenSigTimeoutTime" BU_SG_REL_ BCM1 SG_ 1124 PSD_Sys_Zielfuehrung 1500;
BA_REL_ "GenSigTimeoutTime" BU_SG_REL_ BCM1 SG_ 1124 PSD_Sys_US_State 1500;
BA_REL_ "GenSigTimeoutTime" BU_SG_REL_ BCM1 SG_ 1124 PSD_Ges_Geschwindigkeit_Gespann 1500;
BA_REL_ "GenSigTimeoutTime" BU_SG_REL_ BCM1 SG_ 1124 PSD_Baum_Breite_VZ 1500;
BA_REL_ "GenSigTimeoutTime" BU_SG_REL_ BCM1 SG_ 1124 PSD_Attribut_4_Wert 1500;
BA_REL_ "GenSigTimeoutTime" BU_SG_REL_ BCM1 SG_ 1124 PSD_Baum_Breite 1500;
BA_REL_ "GenSigTimeoutTime" BU_SG_REL_ BCM1 SG_ 1124 PSD_Ges_Geschwindigkeit_Witter 1500;
BA_REL_ "GenSigTimeoutTime" BU_SG_REL_ BCM1 SG_ 1124 PSD_Steigung_1_B_Vorz 1500;
BA_REL_ "GenSigTimeoutTime" BU_SG_REL_ BCM1 SG_ 1124 PSD_Steigung_1_B_Offset 1500;
BA_REL_ "GenSigTimeoutTime" BU_SG_REL_ BCM1 SG_ 1124 PSD_Ges_Geschwindigkeit_Tag_Anf 1500;
BA_REL_ "GenSigTimeoutTime" BU_SG_REL_ BCM1 SG_ 1124 PSD_Attribut_4_Offset 1500;
BA_REL_ "GenSigTimeoutTime" BU_SG_REL_ BCM1 SG_ 1124 PSD_Ges_Geschwindigkeit_Tag_Ende 1500;
BA_REL_ "GenSigTimeoutTime" BU_SG_REL_ BCM1 SG_ 1124 PSD_Ges_Geschwindigkeit_Std_Anf 1500;
BA_REL_ "GenSigTimeoutTime" BU_SG_REL_ BCM1 SG_ 1124 PSD_Steigung_1_Attribute_kompl 1500;
BA_REL_ "GenSigTimeoutTime" BU_SG_REL_ BCM1 SG_ 1124 PSD_Steigung_2_Segment_ID 1500;
BA_REL_ "GenSigTimeoutTime" BU_SG_REL_ BCM1 SG_ 1124 PSD_Attribut_5_ID 1500;
BA_REL_ "GenSigTimeoutTime" BU_SG_REL_ BCM1 SG_ 1124 PSD_Ges_Geschwindigkeit_Std_Ende 1500;
BA_REL_ "GenSigTimeoutTime" BU_SG_REL_ BCM1 SG_ 1124 PSD_Attribut_5_Offset 1500;
BA_REL_ "GenSigTimeoutTime" BU_SG_REL_ BCM1 SG_ 1124 PSD_Steigung_2_Steigung 1500;
BA_REL_ "GenSigTimeoutTime" BU_SG_REL_ BCM1 SG_ 1124 PSD_Ges_Ueberholverbot 1500;
BA_REL_ "GenSigTimeoutTime" BU_SG_REL_ BCM1 SG_ 1124 PSD_Ges_Wechselverkehrszeichen 1500;
BA_REL_ "GenSigTimeoutTime" BU_SG_REL_ BCM1 SG_ 1124 PSD_Attribut_5_Wert 1500;
BA_REL_ "GenSigTimeoutTime" BU_SG_REL_ BCM1 SG_ 1124 PSD_Steigung_2_Vorz 1500;
BA_REL_ "GenSigTimeoutTime" BU_SG_REL_ BCM1 SG_ 1124 PSD_Wechselverkehrszeichen_Typ 1500;
BA_REL_ "GenSigTimeoutTime" BU_SG_REL_ BCM1 SG_ 1124 PSD_Baum_Ausrichtung 1500;
BA_REL_ "GenSigTimeoutTime" BU_SG_REL_ BCM1 SG_ 1124 PSD_Steigung_2_Offset 1500;
BA_REL_ "GenSigTimeoutTime" BU_SG_REL_ BCM1 SG_ 1124 PSD_Ges_Gesetzlich_Kategorie 1500;
BA_REL_ "GenSigTimeoutTime" BU_SG_REL_ BCM1 SG_ 1124 PSD_Attribute_Komplett_06 1500;
BA_REL_ "GenSigTimeoutTime" BU_SG_REL_ BCM1 SG_ 1124 PSD_Ges_Gesetzlich_Zusatz 1500;
BA_REL_ "GenSigTimeoutTime" BU_SG_REL_ BCM1 SG_ 1124 PSD_Ges_Verkehrszeichen_Quelle 1500;
BA_REL_ "GenSigTimeoutTime" BU_SG_REL_ BCM1 SG_ 1124 PSD_Steigung_2_Attribute_kompl 1500;
BA_REL_ "GenSigTimeoutTime" BU_SG_REL_ BCM1 SG_ 1124 PSD_Ges_Attribute_Komplett 1500;
VAL_ 2600468629 NM_Sitzmemo_SR3_SNI 149 "" ;
VAL_ 2600468629 NM_Sitzmemo_SR3_CBV_AWB 0 "Passiver_WakeUp" 1 "Aktiver_WakeUp" ;
VAL_ 2600468629 NM_Sitzmemo_SR3_CBV_CRI 0 "Standard_Layout" 1 "TNB_Layout" ;
VAL_ 2600468629 NM_Sitzmemo_SR3_NM_State 1 "NM_RM_aus_BSM" 2 "NM_RM_aus_PBSM" 4 "NM_NO_aus_RM" 8 "NM_NO_aus_RS" ;
VAL_ 2600468629 NM_Sitzmemo_SR3_Car_Wakeup 0 "Inaktiv" 1 "Car_Wakeup" ;
VAL_ 2600468629 NM_Sitzmemo_SR3_UDS_CC 1 "CC_aktiv" ;
VAL_ 2600468629 NM_Sitzmemo_SR3_NM_aktiv_KL15 0 "Inaktiv" 1 "KL15_EIN" ;
VAL_ 2600468629 NM_Sitzmemo_SR3_NM_aktiv_Diag 1 "Diagnose_aktiv" ;
VAL_ 2600468629 NM_Sitzmemo_SR3_NM_aktiv_Tmin 0 "Inaktiv" 1 "Mindestaktivzeit" ;
VAL_ 2600468629 NM_Sitzmemo_SR3_NM_aktiv_ZStel 0 "nicht_aktiv" 1 "in_Zwischenstellung" ;
VAL_ 2600468629 NM_Sitzmemo_SR3_CAB 1 "CAB_01__Tueren" 2 "CAB_02__Anhaenger" 4 "CAB_03__Nightvision" 8 "CAB_04__Sitzverstellung" 16 "CAB_05__Klappen" 32 "CAB_06__Infotainment" 64 "CAB_07__Sub_Infotainment" 128 "CAB_08__Anzeige" 256 "CAB_09__Laden" ;
VAL_ 2600468516 NM_SpoilerSG_SNI 36 "" ;
VAL_ 2600468516 NM_SpoilerSG_CBV_AWB 0 "Passiver_WakeUp" 1 "Aktiver_WakeUp" ;
VAL_ 2600468516 NM_SpoilerSG_CBV_CRI 0 "Standard_Layout" 1 "TNB_Layout" ;
VAL_ 2600468516 NM_SpoilerSG_NM_State 1 "NM_RM_aus_BSM" 2 "NM_RM_aus_PBSM" 4 "NM_NO_aus_RM" 8 "NM_NO_aus_RS" ;
VAL_ 2600468516 NM_SpoilerSG_Car_Wakeup 0 "Inaktiv" 1 "Car_Wakeup" ;
VAL_ 2600468516 NM_SpoilerSG_UDS_CC 1 "CC_aktiv" ;
VAL_ 2600468516 NM_SpoilerSG_NM_aktiv_KL15 0 "Inaktiv" 1 "KL15_EIN" ;
VAL_ 2600468516 NM_SpoilerSG_NM_aktiv_Diagnose 1 "Diagnose_aktiv" ;
VAL_ 2600468516 NM_SpoilerSG_NM_aktiv_Tmin 0 "Inaktiv" 1 "Mindestaktivzeit" ;
VAL_ 2600468516 NM_SpoilerSG_CAB 1 "CAB_01__Tueren" 2 "CAB_02__Anhaenger" 4 "CAB_03__Nightvision" 8 "CAB_04__Sitzverstellung" 16 "CAB_05__Klappen" 32 "CAB_06__Infotainment" 64 "CAB_07__Sub_Infotainment" 128 "CAB_08__Anzeige" 256 "CAB_09__Laden" ;
VAL_ 2600468523 NM_STS_SNI 43 "" ;
VAL_ 2600468523 NM_STS_CBV_AWB 0 "Passiver_WakeUp" 1 "Aktiver_WakeUp" ;
VAL_ 2600468523 NM_STS_CBV_CRI 0 "Standard_Layout" 1 "TNB_Layout" ;
VAL_ 2600468523 NM_STS_NM_State 1 "NM_RM_aus_BSM" 2 "NM_RM_aus_PBSM" 4 "NM_NO_aus_RM" 8 "NM_NO_aus_RS" ;
VAL_ 2600468523 NM_STS_Car_Wakeup 0 "Inaktiv" 1 "Car_Wakeup" ;
VAL_ 2600468523 NM_STS_UDS_CC 1 "CC_aktiv" ;
VAL_ 2600468523 NM_STS_NM_aktiv_KL15 0 "Inaktiv" 1 "KL15_EIN" ;
VAL_ 2600468523 NM_STS_NM_aktiv_Diagnose 1 "Diagnose_aktiv" ;
VAL_ 2600468523 NM_STS_NM_aktiv_Tmin 0 "Inaktiv" 1 "Mindestaktivzeit" ;
VAL_ 2600468523 NM_STS_CAB 1 "CAB_01__Tueren" 2 "CAB_02__Anhaenger" 4 "CAB_03__Nightvision" 8 "CAB_04__Sitzverstellung" 16 "CAB_05__Klappen" 32 "CAB_06__Infotainment" 64 "CAB_07__Sub_Infotainment" 128 "CAB_08__Anzeige" 256 "CAB_09__Laden" ;
VAL_ 2600468555 NM_TSG_BFS_SNI 75 "" ;
VAL_ 2600468555 NM_TSG_BFS_CBV_AWB 0 "Passiver_WakeUp" 1 "Aktiver_WakeUp" ;
VAL_ 2600468555 NM_TSG_BFS_CBV_CRI 0 "Standard_Layout" 1 "TNB_Layout" ;
VAL_ 2600468555 NM_TSG_BFS_NM_State 1 "NM_RM_aus_BSM" 2 "NM_RM_aus_PBSM" 4 "NM_NO_aus_RM" 8 "NM_NO_aus_RS" ;
VAL_ 2600468555 NM_TSG_BFS_Car_Wakeup 0 "Inaktiv" 1 "Car_Wakeup" ;
VAL_ 2600468555 NM_TSG_BFS_UDS_CC 1 "CC_aktiv" ;
VAL_ 2600468555 NM_TSG_BFS_NM_aktiv_KL15 0 "Inaktiv" 1 "KL15_EIN" ;
VAL_ 2600468555 NM_TSG_BFS_NM_aktiv_Diagnose 1 "Diagnose_aktiv" ;
VAL_ 2600468555 NM_TSG_BFS_NM_aktiv_Tmin 0 "Inaktiv" 1 "Mindestaktivzeit" ;
VAL_ 2600468555 NM_TSG_BFS_NM_aktiv_Taster 1 "Taster_betaetigt" ;
VAL_ 2600468555 NM_TSG_BFS_NM_aktiv_LIN 1 "LIN_aktiv" ;
VAL_ 2600468555 NM_TSG_BFS_NM_aktiv_Bordsteinfkt 0 "inaktiv" 1 "aktiv" ;
VAL_ 2600468555 NM_TSG_BFS_NM_aktiv_EC_Spiegel 0 "inaktiv" 1 "aktiv" ;
VAL_ 2600468555 NM_TSG_BFS_NM_aktiv_Spiegelhzg 0 "inaktiv" 1 "aktiv" ;
VAL_ 2600468555 NM_TSG_BFS_CAB 1 "CAB_01__Tueren" 2 "CAB_02__Anhaenger" 4 "CAB_03__Nightvision" 8 "CAB_04__Sitzverstellung" 16 "CAB_05__Klappen" 32 "CAB_06__Infotainment" 64 "CAB_07__Sub_Infotainment" 128 "CAB_08__Anzeige" 256 "CAB_09__Laden" ;
VAL_ 2600468554 NM_TSG_FS_SNI 74 "" ;
VAL_ 2600468554 NM_TSG_FS_CBV_AWB 0 "Passiver_WakeUp" 1 "Aktiver_WakeUp" ;
VAL_ 2600468554 NM_TSG_FS_CBV_CRI 0 "Standard_Layout" 1 "TNB_Layout" ;
VAL_ 2600468554 NM_TSG_FS_NM_State 1 "NM_RM_aus_BSM" 2 "NM_RM_aus_PBSM" 4 "NM_NO_aus_RM" 8 "NM_NO_aus_RS" ;
VAL_ 2600468554 NM_TSG_FS_Car_Wakeup 0 "Inaktiv" 1 "Car_Wakeup" ;
VAL_ 2600468554 NM_TSG_FS_UDS_CC 1 "CC_aktiv" ;
VAL_ 2600468554 NM_TSG_FS_NM_aktiv_KL15 0 "Inaktiv" 1 "KL15_EIN" ;
VAL_ 2600468554 NM_TSG_FS_NM_aktiv_Diagnose 1 "Diagnose_aktiv" ;
VAL_ 2600468554 NM_TSG_FS_NM_aktiv_Tmin 0 "Inaktiv" 1 "Mindestaktivzeit" ;
VAL_ 2600468554 NM_TSG_FS_NM_aktiv_Taster 1 "Taster_betaetigt" ;
VAL_ 2600468554 NM_TSG_FS_NM_aktiv_LIN 1 "LIN_aktiv" ;
VAL_ 2600468554 NM_TSG_FS_CAB 1 "CAB_01__Tueren" 2 "CAB_02__Anhaenger" 4 "CAB_03__Nightvision" 8 "CAB_04__Sitzverstellung" 16 "CAB_05__Klappen" 32 "CAB_06__Infotainment" 64 "CAB_07__Sub_Infotainment" 128 "CAB_08__Anzeige" 256 "CAB_09__Laden" ;
VAL_ 2600468525 NM_VSG_SNI 45 "" ;
VAL_ 2600468525 NM_VSG_CBV_AWB 0 "Passiver_WakeUp" 1 "Aktiver_WakeUp" ;
VAL_ 2600468525 NM_VSG_CBV_CRI 0 "Standard_Layout" 1 "TNB_Layout" ;
VAL_ 2600468525 NM_VSG_NM_State 1 "NM_RM_aus_BSM" 2 "NM_RM_aus_PBSM" 4 "NM_NO_aus_RM" 8 "NM_NO_aus_RS" ;
VAL_ 2600468525 NM_VSG_Car_Wakeup 0 "Inaktiv" 1 "Car_Wakeup" ;
VAL_ 2600468525 NM_VSG_UDS_CC 1 "CC_aktiv" ;
VAL_ 2600468525 NM_VSG_NM_aktiv_KL15 0 "Inaktiv" 1 "KL15_EIN" ;
VAL_ 2600468525 NM_VSG_NM_aktiv_Diagnose 1 "Diagnose_aktiv" ;
VAL_ 2600468525 NM_VSG_NM_aktiv_Tmin 0 "Inaktiv" 1 "Mindestaktivzeit" ;
VAL_ 2600468525 NM_VSG_CAB 1 "CAB_01__Tueren" 2 "CAB_02__Anhaenger" 4 "CAB_03__Nightvision" 8 "CAB_04__Sitzverstellung" 16 "CAB_05__Klappen" 32 "CAB_06__Infotainment" 64 "CAB_07__Sub_Infotainment" 128 "CAB_08__Anzeige" 256 "CAB_09__Laden" ;
VAL_ 1377 NV_Obj_01_InvTTCBildebStdA 127 "Init" ;
VAL_ 1377 NV_Obj_Warnung_Fussgaenger 0 "inaktiv" 1 "aktiv" ;
VAL_ 1377 NV_Obj_Rechts 0 "nicht_erkannt" 1 "erkannt" ;
VAL_ 1377 NV_Obj_Links 0 "nicht_erkannt" 1 "erkannt" ;
VAL_ 1377 NV_Obj_01_Klasse 0 "unbekannt" 1 "ueberfahrbar" 2 "unterfahrbar" 3 "Fussgaenger" 4 "Fussgaengergruppe" 5 "Fahrrad" 6 "Motorrad" 7 "PKW" 8 "Van" 9 "LKW" 10 "Randbebauung" 11 "Tier" 12 "Retroreflektor" 15 "Init" ;
VAL_ 1377 NV_MessZeitpunkt 8191 "Init" ;
VAL_ 1377 NV_Sensor_PositionY 2047 "Init" ;
VAL_ 1377 NV_Sensor_PositionX 4095 "Init" ;
VAL_ 1377 NV_Sensor_PositionZ 2047 "Init" ;
VAL_ 1377 NV_NichtVerfuegbar 0 "NV_verfuegbar" 1 "NV_nicht_verfuegbar" ;
VAL_ 1635 BEM_02_Abschaltstufen 0 "Stufe 0 (keine Einschraenkungen)" 1 "Stufe 1" 2 "Stufe 2" 3 "Stufe 3" 4 "Transportmodus" 7 "Ruhestrommessmodus" ;
VAL_ 1635 BEM_STH_Zielzeit 14 "Init" 15 "Fehler" ;
VAL_ 1635 BEM_MMI_Vorwarnung 0 "keine Anzeige" 1 "Anzeige MMI-Vorwarnung" ;
VAL_ 1635 NVEM_Anf_SD_schalten 0 "Anf_SD_Nachlauf_nicht_aktiv" 1 "Anf_SD_Nachlauf_aktiv" ;
VAL_ 1635 BEM_Generatordiagnose 0 "keine Anzeige" 1 "Ladekontrollanzeige ein (Vorhalt)" 2 "rotes Batteriesymbol und Text (Generator defekt)" 3 "Hybrid_DCDC_Wandler_defekt" ;
VAL_ 1635 BEM_Red_Innengeblaese 0 "keine Reduzierung" 1 "Reduzierung Stufe 1" 2 "Reduzierung Stufe 2" 3 "Reduzierung Stufe 2 und Abschaltung Kompressor" ;
VAL_ 1635 BEM_STH_Einschaltverbot 0 "volle Verfuegbarkeit Standheizung/-lueftung" 1 "Standheizung/-lueftung nicht aktivierbar" ;
VAL_ 1635 BEM_HL_Regelung_Status 0 "HL_Regelung_inaktiv_(vor_und_waehrend_Motorstart)" 1 "HL_Regelung_Stufe_1" 2 "HL_Regelung_Stufe_2" 3 "HL_Regelung_Stufe_3" 4 "Verbrauchernotabschaltung_(VNA)" 5 "HL_Regelung_Stufe_5" 7 "Default" ;
VAL_ 1635 BEM_Ladezustand 14 "Init" 15 "Fehler" ;
VAL_ 1635 BEM_Batteriediagnose 0 "keine_Anzeige" 1 "nicht_belegt" 2 "Anzeige_aberkannte_Batterie" 3 "Anzeige_schwache_Batterie" 4 "Anzeige_Batterie_OK" 5 "Anzeige_Batterie_Laden" 6 "Anzeige_Batterie_Prüfen" 7 "Fehler" ;
VAL_ 1635 MIB_Stromsparmodus 0 "inaktiv" 1 "aktiv" ;
VAL_ 1635 BEM_REK_aktiv 0 "keine_Rekuperationsfreigabe" 1 "Rekuperationsfreigabe" ;
VAL_ 1635 BEM_UBDM 0 "Init" 255 "Fehler" ;
VAL_ 1635 BEM_Anf_KL15_schalten 0 "Keine_Einschraenkung_Kl15" 1 "Empfehlung_auto_Abschaltung_Kl15" 2 "Veto_auto_Abschaltung_Kl15" 3 "Veto_auto_Abschaltung_Fahrtbetrieb" ;
VAL_ 1635 NVEM_Batterie_Service 0 "kein_Service" 1 "Service_Information1" 2 "Service_Information2" 3 "Service_Information3" ;
VAL_ 913 MO_Servicemodus 0 "nicht_aktiv" 1 "Service_Mode_1" 2 "Service_Mode_2" 3 "Service_Mode_3" 4 "Service_Mode_4" 5 "Service_Mode_5" 6 "Service_Mode_6" 7 "Service_Mode_7" 8 "Service_Mode_8" 9 "Service_Mode_9" 10 "Service_Mode_10" 11 "Service_Mode_11" 12 "Service_Mode_12" 13 "Service_Mode_13" 14 "Service_Mode_14" 15 "Service_Mode_15" ;
VAL_ 913 MO_QBit_Aussen_Temp 0 "gueltiger_Wert" 1 "Ersatz_Init_oder_Fehlerwert" ;
VAL_ 913 OBD_Sperrung_IUMPR 0 "IUMPR_Berechnung_freigegeben" 1 "IUMPR_Berechnung_gesperrt" ;
VAL_ 913 OBD_Kaltstart_Denominator 0 "Denominator_nicht_hochzaehlen" 1 "Bedingungen_zum_Inkr_des_Kaltstart_Denom_erf" ;
VAL_ 913 OBD_Minimum_Trip 0 "kein_Min_Normed_Trip" 1 "Min_Normed_Trip" ;
VAL_ 913 OBD_Driving_Cycle 0 "kein Driving Cycle erkannt" 1 "DC erkannt" ;
VAL_ 913 OBD_Warm_Up_Cycle 0 "kein Warm Up Cycle erkannt" 1 "Warm Up Cycle erkannt" ;
VAL_ 913 OBD_Normed_Trip 0 "kein Normed Trip" 1 "Normed Trip erfüllt" ;
VAL_ 1630 OBD_TG_F_Status_1 0 "kein Fehler / Init / nicht verbaut" 1 "KS- (Kurzschluss nach minus)" 2 "KS+ (Kurzschluss nach plus)" 3 "OC (Leitungsunterbrechung)" 4 "OOR+ (Signal zu gross)" 5 "OOR- (Signal zu klein)" 6 "RC+ (Signal unplausibel zu gross)" 7 "RC- (Signal unplausibel zu klein)" 8 "KS+/OC (Kurzschluss nach plus/Unterbrechung)" 9 "KS-/OC  (Kurzschluss nach minus/Unterbrechung)" 10 "KS-/KS+  (Kurzschluss nach minus/plus)" 11 "KS-/KS+/OC (Kurzschluss nach minus/plus/Unterbrechung)" 12 "frei" 13 "frei" 14 "frei" 15 "frei" ;
VAL_ 1630 OBD_TG_F_Status_2 0 "kein Fehler / Init / nicht verbaut" 1 "KS- (Kurzschluss nach minus)" 2 "KS+ (Kurzschluss nach plus)" 3 "OC (Leitungsunterbrechung)" 4 "OOR+ (Signal zu gross)" 5 "OOR- (Signal zu klein)" 6 "RC+ (Signal unplausibel zu gross)" 7 "RC- (Signal unplausibel zu klein)" 8 "KS+/OC (Kurzschluss nach plus/Unterbrechung)" 9 "KS-/OC  (Kurzschluss nach minus/Unterbrechung)" 10 "KS-/KS+  (Kurzschluss nach minus/plus)" 11 "KS-/KS+/OC (Kurzschluss nach minus/plus/Unterbrechung)" 12 "frei" 13 "frei" 14 "frei" 15 "frei" ;
VAL_ 1630 OBD_TG_F_Status_3 0 "kein Fehler / Init / nicht verbaut" 1 "KS- (Kurzschluss nach minus)" 2 "KS+ (Kurzschluss nach plus)" 3 "OC (Leitungsunterbrechung)" 4 "OOR+ (Signal zu gross)" 5 "OOR- (Signal zu klein)" 6 "RC+ (Signal unplausibel zu gross)" 7 "RC- (Signal unplausibel zu klein)" 8 "KS+/OC (Kurzschluss nach plus/Unterbrechung)" 9 "KS-/OC  (Kurzschluss nach minus/Unterbrechung)" 10 "KS-/KS+  (Kurzschluss nach minus/plus)" 11 "KS-/KS+/OC (Kurzschluss nach minus/plus/Unterbrechung)" 12 "frei" 13 "frei" 14 "frei" 15 "frei" ;
VAL_ 1630 OBD_TG_F_Status_4 0 "kein Fehler / Init / nicht verbaut" 1 "KS- (Kurzschluss nach minus)" 2 "KS+ (Kurzschluss nach plus)" 3 "OC (Leitungsunterbrechung)" 4 "OOR+ (Signal zu gross)" 5 "OOR- (Signal zu klein)" 6 "RC+ (Signal unplausibel zu gross)" 7 "RC- (Signal unplausibel zu klein)" 8 "KS+/OC (Kurzschluss nach plus/Unterbrechung)" 9 "KS-/OC  (Kurzschluss nach minus/Unterbrechung)" 10 "KS-/KS+  (Kurzschluss nach minus/plus)" 11 "KS-/KS+/OC (Kurzschluss nach minus/plus/Unterbrechung)" 12 "frei" 13 "frei" 14 "frei" 15 "frei" ;
VAL_ 872 PH2_Visualisierung 0 "Aus" 1 "Angefragt" 2 "InAnzeige" 3 "Abgefordert" 6 "Init" 7 "Fehler" ;
VAL_ 872 PH2_nachtr_Stopp_An 0 "nicht_angefordert" 1 "angefordert" ;
VAL_ 872 PH2_Abschaltursache 0 "keine, bzw. System aktiv" 1 "Abschaltung durch Herausnahme R-Gang" 2 "Abschaltung ueber Geschwindigkeit" 3 "Abschaltung ueber PDC-Taster" 4 "Abschaltung wegen PLA" 5 "Abschaltung durch KL 15 Bit = 0" 6 "tbd." 7 "Fehler-/gestört Zustand, System noch aktiv" ;
VAL_ 872 PH2_Opt_Anzeige_V_ein 0 "optische Anzeige vorne nicht aktiv" 1 "optische Anzeige vorne aktiviert" ;
VAL_ 872 PH2_Opt_Anzeige_H_ein 0 "Optische Anzeige aus" 1 "optische Anzeige hinten aktiviert" ;
VAL_ 872 PH2_Opt_Anz_V_Hindernis 0 "optische Anzeige vorne meldet kein Hindernis" 1 "optische Anzeige vorne meldet Hindernis im Warnbereich" ;
VAL_ 872 PH2_Opt_Anz_H_Hindernis 0 "optische Anzeige hinten meldet kein Hindernis" 1 "optische Anzeige hinten meldet Hindernis im Warnbereich" ;
VAL_ 872 PH2_Tongeber_V_aktiv 0 "Tongeber vorne nicht aktiv" 1 "Tongeber vorne  aktiv" ;
VAL_ 872 PH2_Tongeber_H_aktiv 0 "Tongeber hinten nicht aktiv" 1 "Tongeber hinten aktiv" ;
VAL_ 872 PH2_Tongeber_mute 0 "Tongeber nicht stummgeschaltet" 1 "Tongeber stummgeschaltet" ;
VAL_ 872 PH2_Anf_Audioabsenkung 0 "keine Absenkung der Lautstärke" 1 "Anforderung an das Audiosystem für Absenkung der Lautstärke" ;
VAL_ 872 PH2_Tongeber_H_verfuegbar 0 "nicht verfügbar" 1 "verfügbar" ;
VAL_ 872 PH2_Taster 0 "Taster_nicht_gedrueckt" 1 "Taster_gedrueckt" 2 "reserviert" 3 "Fehler" ;
VAL_ 872 PH2_Anf_Verdeck 0 "Verdeckbetrieb_freigegeben" 1 "Verdeckbetrieb_sperren" 2 "reserviert" 3 "reserviert" ;
VAL_ 872 PH2_StartStopp_Info 0 "Motorlauf_nicht_notwendig_(Stoppfreigabe)" 1 "Motoranlauf_nicht_zwingend_notwendig_(Stoppverbot,keine_Startanforderung)" 2 "Motoranlauf_zwingend_notwendig_(Startanforderung)" 3 "Systemfehler" ;
VAL_ 872 PH2_Stoermeldung 0 "keine Anzeige / kein Gong (PDC nicht aktiv bzw. fehlerfrei)" 1 "Textmeldung ¿PDC hinten gestört¿ mit Gong" 2 "Textmeldung ¿PDC hinten gestört¿ ohne Gong" 3 "Textmeldung ¿PDC vorn gestört¿ mit Gong" 4 "Textmeldung ¿PDC vorn gestört¿ ohne Gong" 5 "Textmeldung ¿PDC gestört¿ mit Gong" 6 "Textmeldung ¿PDC gestört¿ ohne Gong" ;
VAL_ 872 PH2_defekt 0 "PH aktiv" 1 "PH wurde aufgrund eines Defektes deaktiviert" ;
VAL_ 872 PH2_gestoert 0 "PH aktiv" 1 "PH wurde auf Grund einer Stoerung tempraer deaktiviert" ;
VAL_ 872 PH2_Systemzustand 0 "Anlage aus" 1 "Anlage durch einlegen R-Gang aktiviert" 2 "Anlage manuell durch Taster aktiviert" 3 "Anlage automatisch aktiviert" 4 "Anlage_durch_ARA_aktiviert" 6 "Init_Initialisierungsphase_nach_Kl15_ein_oder_Reset" 7 "Fehler-/gestört Zustand, System noch aktiv" ;
VAL_ 872 PH2_Display_Kundenwunsch 0 "Anzeige aus" 1 "Grafik" 2 "Rear View" 3 "automatisch" ;
VAL_ 872 APS2_Tongeber_defekt 0 "iO" 1 "defekt" ;
VAL_ 1175 PH_Visualisierung 0 "Aus" 1 "Angefragt" 2 "InAnzeige" 3 "Abgefordert" 6 "Init" 7 "Fehler" ;
VAL_ 1175 PDC_Tonausgabe_Front 0 "kein_Ton" 1 "Intervallton_1" 2 "Intervallton_2" 3 "Intervallton_3" 4 "Intervallton_4" 5 "Intervallton_5" 6 "Dauerton" 7 "Fehlerton" 8 "RCTATon" ;
VAL_ 1175 PDC_Tonausgabe_Heck 0 "kein_Ton" 1 "Intervallton_1" 2 "Intervallton_2" 3 "Intervallton_3" 4 "Intervallton_4" 5 "Intervallton_5" 6 "Dauerton" 7 "Fehlerton" 8 "Erstwarnton_hinten" 9 "RCTATon" ;
VAL_ 1175 PH_nachtr_Stopp_Anf 0 "nicht_angefordert" 1 "angefordert" ;
VAL_ 1175 PH_Abschaltursache 0 "keine, bzw. System aktiv" 1 "Abschaltung durch Herausnahme R-Gang" 2 "Abschaltung ueber Geschwindigkeit" 3 "Abschaltung ueber PDC-Taster" 4 "Abschaltung wegen PLA" 5 "Abschaltung durch KL 15 Bit = 0" 6 "tbd." 7 "Fehler-/gestört Zustand, System noch aktiv" ;
VAL_ 1175 PH_Opt_Anzeige_V_ein 0 "optische Anzeige vorne nicht aktiv" 1 "optische Anzeige vorne aktiviert" ;
VAL_ 1175 PH_Opt_Anzeige_H_ein 0 "Optische Anzeige aus" 1 "optische Anzeige hinten aktiviert" ;
VAL_ 1175 PH_Opt_Anz_V_Hindernis 0 "optische Anzeige vorne meldet kein Hindernis" 1 "optische Anzeige vorne meldet Hindernis im Warnbereich" ;
VAL_ 1175 PH_Opt_Anz_H_Hindernis 0 "optische Anzeige hinten meldet kein Hindernis" 1 "optische Anzeige hinten meldet Hindernis im Warnbereich" ;
VAL_ 1175 PH_Tongeber_V_aktiv 0 "Tongeber vorne nicht aktiv" 1 "Tongeber vorne  aktiv" ;
VAL_ 1175 PH_Tongeber_H_aktiv 0 "Tongeber hinten nicht aktiv" 1 "Tongeber hinten aktiv" ;
VAL_ 1175 PH_Tongeber_mute 0 "Tongeber nicht stummgeschaltet" 1 "Tongeber stummgeschaltet" ;
VAL_ 1175 PH_Anf_Audioabsenkung 0 "keine Absenkung der Lautstärke" 1 "Anforderung an das Audiosystem für Absenkung der Lautstärke" ;
VAL_ 1175 PH_Tongeber_H_verfuegbar 0 "nicht verfügbar" 1 "verfügbar" ;
VAL_ 1175 PLA_Anf_Aufschaltung_RVC 0 "Keine_RVC_Aufschalteanf" 1 "RVC_Aufschalteanforderung" ;
VAL_ 1175 PH_Taster 0 "Taster_nicht_gedrueckt" 1 "Taster_gedrueckt" 2 "reserviert" 3 "Fehler" ;
VAL_ 1175 PH_Anf_Verdeck 0 "Verdeckbetrieb_freigegeben" 1 "Verdeckbetrieb_sperren" 2 "reserviert" 3 "reserviert" ;
VAL_ 1175 PH_StartStopp_Info 0 "Motorlauf_nicht_notwendig_(Stoppfreigabe)" 1 "Motoranlauf_nicht_zwingend_notwendig_(Stoppverbot,keine_Startanforderung)" 2 "Motoranlauf_zwingend_notwendig_(Startanforderung)" 3 "Systemfehler" ;
VAL_ 1175 PH_Stoermeldung 0 "keine Anzeige / kein Gong (PDC nicht aktiv bzw. fehlerfrei)" 1 "Textmeldung ¿PDC hinten gestört¿ mit Gong" 2 "Textmeldung ¿PDC hinten gestört¿ ohne Gong" 3 "Textmeldung ¿PDC vorn gestört¿ mit Gong" 4 "Textmeldung ¿PDC vorn gestört¿ ohne Gong" 5 "Textmeldung ¿PDC gestört¿ mit Gong" 6 "Textmeldung ¿PDC gestört¿ ohne Gong" ;
VAL_ 1175 PH_defekt 0 "PH aktiv" 1 "PH wurde aufgrund eines Defektes deaktiviert" ;
VAL_ 1175 PH_gestoert 0 "PH aktiv" 1 "PH wurde auf Grund einer Stoerung tempraer deaktiviert" ;
VAL_ 1175 PH_Systemzustand 0 "Anlage aus" 1 "Anlage durch einlegen R-Gang aktiviert" 2 "Anlage manuell durch Taster aktiviert" 3 "Anlage automatisch aktiviert" 4 "Anlage durch ARA aktiviert" 6 "Init - Initialisierungsphase nach Kl. 15 ein / Reset" 7 "Fehler-/gestört Zustand, System noch aktiv" ;
VAL_ 1175 PH_Display_Kundenwunsch 0 "Anzeige aus" 1 "Grafik" 2 "Rear View" 3 "automatisch" ;
VAL_ 2527679498 Perso_Kontonummer 0 "kein_Benutzerkonto" 1 "Benutzerkonto_1" 2 "Benutzerkonto_2" 3 "Benutzerkonto_3" 4 "Benutzerkonto_4" 5 "Benutzerkonto_5" 6 "Benutzerkonto_6" 7 "Benutzerkonto_7" ;
VAL_ 2527679498 Perso_Steuerung 0 "keine_Steuerung" 1 "Reset_alle_Konten" 2 "Reset_aktives_Konto" 3 "Kopiere_aktives_Konto_nach" ;
VAL_ 2527679498 Perso_Steuerungsparameter 0 "kein_Parameter" 1 "Benutzerkonto_1" 2 "Benutzerkonto_2" 3 "Benutzerkonto_3" 4 "Benutzerkonto_4" 5 "Benutzerkonto_5" 6 "Benutzerkonto_6" 7 "Benutzerkonto_7" ;
VAL_ 2527679498 Perso_Status 0 "deaktiviert" 1 "aktiviert" ;
VAL_ 2527679498 Perso_Bedienstelle 0 "Init" 1 "Kombiinstrument" 2 "ABT" ;
VAL_ 2527679498 Perso_Freigabe_Verstellung 0 "Init" 1 "freigegeben" ;
VAL_ 304 PLA_Status_PLA_ESP 0 "reserviert" 1 "reserviert" 2 "reserviert" 3 "reserviert" 4 "PLA_ESP_aktivierbar" 5 "reserviert" 6 "PLA_ESP_Bremse_aktiv" 7 "reserviert" 8 "PLA_ESP_funktionsbereit" 9 "PLA_ESP_Neustart" 10 "PLA_ESP_Abbruch" 11 "reserviert" 12 "reserviert" 13 "reserviert" 14 "reserviert" 15 "reserviert" ;
VAL_ 304 PLA_Zahnstangen_Pos_Soll 4094 "Init" ;
VAL_ 304 PLA_VZ_Zahnstangen_Pos_Soll 0 "positiv" 1 "negativ" ;
VAL_ 304 PLA_Status_PLA_EPS 0 "reserviert" 1 "reserviert" 2 "reserviert" 3 "reserviert" 4 "PLA_EPS_aktivierbar" 5 "reserviert" 6 "PLA_EPS_Lenkwinkel_aktiv" 7 "reserviert" 8 "PLA_EPS_funktionsbereit" 9 "PLA_EPS_Neustart" 10 "PLA_EPS_Abbruch" 11 "reserviert" 12 "reserviert" 13 "reserviert" 14 "reserviert" 15 "reserviert" ;
VAL_ 304 PLA_Bremsverzoegerung 126 "Init" 127 "Fehler" ;
VAL_ 304 PLA_Anf_Bremsverzoegerung 0 "keine Bremsverzögerung" 1 "Bremsverzögerung" ;
VAL_ 304 PLA_BremsMom_Verzoeg 0 "Bremsmoment" 1 "Bremsverzoegerung" ;
VAL_ 304 PLA_01_Signal_red_cyclic 0 "Langsame_Zykluszeit_aktiv" 1 "Schnelle_Zykluszeit_aktiv" ;
VAL_ 342 PLA_Status_PLA_HAL 4 "PLA_HAL_aktivierbar" 6 "PLA_HAL_Lenkwinkel_aktiv" 8 "PLA_HAL_funktionsbereit" 9 "PLA_HAL_Neustart" 10 "PLA_HAL_Abbruch" ;
VAL_ 342 PLA_HAL_VZ_Radwinkel_Soll 0 "positiv" 1 "negativ" ;
VAL_ 342 PLA_Status_PLA_TSK 1 "PLA_TSK_Init" 2 "PLA_TSK_Fehler" 4 "PLA_TSK_aktivierbar" 6 "PLA_TSK_aktiv" 8 "PLA_TSK_funktionsbereit" 10 "PLA_TSK_Abbruch" ;
VAL_ 342 PLA_maximale_Geschwindigkeit 0 "Inaktiv" 251 "Init" 255 "Fehler" ;
VAL_ 342 PLA_02_Signal_red_cyclic 0 "Langsame_Zykluszeit_aktiv" 1 "Schnelle_Zykluszeit_aktiv" ;
VAL_ 1166 PLA_Status_Aktive_Seite 0 "Rechts" 1 "Links" ;
VAL_ 1166 PLA_Anf_Anzeige_Mini 0 "keine Anzeige" 1 "Anzeige Mini" ;
VAL_ 1166 PLA_Mini_Modus 0 "kein Mini angezeigt" 1 "Mini Längsparken" 2 "Mini Rückwärts Querparken" 3 "Mini Vorwärts Querparken" ;
VAL_ 1166 PLA_Anf_Akustik 0 "keine Akustik" 1 "Akustik (Gong 1000)" ;
VAL_ 1166 PLA_Anf_Anzeige_Schwellpfeil 0 "Keine Schwellpfeilanzeige" 1 "Anzeige Schwellpfeil" ;
VAL_ 1166 PLA_Anf_Anzeige_Bremsfuss 0 "Keine_Anzeige_Bremsfuss" 1 "Anzeige_Bremsfuss" ;
VAL_ 1166 PLA_Anf_Funktionsdisclaimer 0 " Längsparken" 1 "Rückwärts Querparken" 2 "Vorwärts Querparken" 3 "Ausparken Längsparken" ;
VAL_ 1166 PLA_Anf_Anzeigemodus 0 "Keine Anzeige" 1 "Reserved" 2 "Längsparken Singlescreen" 3 "Reserved" 4 " Rückwärts Querparken Singlescreen" 5 "Reserved" 6 " Vorwärts Querparken Singlescreen" 7 "Reserved" 8 "Ausparken Längsparken Singlescreen" 9 "Reserved" 10 "Reserved" 11 "Textmeldung hochprior" 12 "Textmeldungen niederprior" 13 "Reserved" 14 "Reserved" 15 "Reserved" ;
VAL_ 1166 PLA_Anf_Meldungen 0 "keine Meldung" ;
VAL_ 1166 PLA_Status_Funktion 0 "PL-Suche" 1 "PL-Suche Standby" 2 "PL gefunden" 3 "POS OK" 4 "Rangieren vorwärts" 5 "Rangieren rückwärts" 6 "Disclaimer in Anzeige" 7 "Reserved" 8 "Reserved" 9 "Reserved" 10 "Reserved" 11 "Reserved" 12 "Reserved" 13 "Reserved" 14 "Reserved" 15 "Reserved" ;
VAL_ 1166 PLA_Status_beenden_Mini 0 "Funktion vorhanden" 1 "Funktion ausgewählt" 2 "Funktion einparken möglich" 3 "Funktion nicht vorhanden" ;
VAL_ 1166 PLA_Status_Laengsparken_Mini 0 "Funktion vorhanden" 1 "Funktion ausgewählt" 2 "Funktion einparken möglich" 3 "Funktion nicht vorhanden" ;
VAL_ 1166 PLA_Status_QP_Rueckw_Mini 0 "Funktion vorhanden" 1 "Funktion ausgewählt" 2 "Funktion einparken möglich" 3 "Funktion nicht vorhanden" ;
VAL_ 1166 PLA_Status_QP_Vorw_Mini 0 "Funktion vorhanden" 1 "Funktion ausgewählt" 2 "Funktion einparken möglich" 3 "Funktion nicht vorhanden" ;
VAL_ 319 PreCrash_Charisma_FahrPr 0 "keine_Funktion" 1 "Programm_1" 2 "Programm_2" 3 "Programm_3" 4 "Programm_4" 5 "Programm_5" 6 "Programm_6" 7 "Programm_7" 8 "Programm_8" 9 "Programm_9" 10 "Programm_10" 11 "Programm_11" 12 "Programm_12" 13 "Programm_13" 14 "Programm_14" 15 "Programm_15" ;
VAL_ 319 PreCrash_Charisma_Status 0 "Init" 1 "verfuegbar" 2 "nicht_verfuegbar" 3 "asynchron_durch_Fahrerwunsch" ;
VAL_ 319 PreCrash_Schiebedach_schliessen 0 "keine_Schliessung" 1 "Schliessung_angefordert" ;
VAL_ 319 PreCrash_Fenster_schliessen 0 "keine_Schliessung" 1 "Schliessung_angefordert" ;
VAL_ 319 PreCrash_Blinken 0 "keine_Blinkanforderung" 1 "Warnblinken" 2 "RECAS_Blinken" 3 "Notbremsblinken" ;
VAL_ 319 SC_PreCrash_LED 0 "keine_Anzeige" 1 "Stufe_1_glimmen" 2 "Stufe_2_leuchten" 3 "Stufe_3_blinken" ;
VAL_ 319 PreCrash_FS_Pneumatik_ansteuern 0 "keine_Anforderung" 1 "Pneumatik_ansteuern" ;
VAL_ 319 PreCrash_BFS_Pneumatik_ansteuern 0 "keine_Anforderung" 1 "Pneumatik_ansteuern" ;
VAL_ 319 PreCrash_Fo_Pneumatik_ansteuern 0 "keine_Anforderung" 1 "Pneumatik_ansteuern" ;
VAL_ 319 PreCrash_FS_Sitzlehne_verfahren 0 "keine_Anforderung" 1 "Sitzlehne_in_pos_x-Richtung_verfahren(vor)" 2 "Sitzlehne_in_neg_x-Richtung_verfahren(zurueck)" 3 "Sitzlehnenkopf_in_pos_x-Richtung_verfahren(vor)" 4 "Sitzlehnenkopf_in_neg_x-Richtung_verfahren(zurueck)" ;
VAL_ 319 PreCrash_BFS_Sitzlehne_verfahren 0 "keine_Anforderung" 1 "Sitzlehne_in_pos_x-Richtung_verfahren(vor)" 2 "Sitzlehne_in_neg_x-Richtung_verfahren(zurueck)" 3 "Sitzlehnenkopf_in_pos_x-Richtung_verfahren(vor)" 4 "Sitzlehnenkopf_in_neg_x-Richtung_verfahren(zurueck)" ;
VAL_ 319 PreCrash_Fo_Sitzlehne_verfahren 0 "keine_Anforderung" 1 "Sitzlehne_in_pos_x-Richtung_verfahren(vor)" 2 "Sitzlehne_in_neg_x-Richtung_verfahren(zurueck)" 3 "Sitzlehnenkopf_in_pos_x-Richtung_verfahren(vor)" 4 "Sitzlehnenkopf_in_neg_x-Richtung_verfahren(zurueck)" ;
VAL_ 319 PreCrash_FS_KSV_verfahren 0 "keine_Anforderung" 1 "in_pos_x-Richtung_verfahren" 2 "in_neg_x-Richung_verfahren" 3 "in_pos_z-Richtung_verfahren" 4 "in_neg_z-Richtung_verfahren" 5 "in_pos_x-Richtung_und_neg_z-Richtung_verfahren" 6 "in_pos_x_Richtung_und_pos_z-Richtung_verfahren" 7 "in_neg_x-Richtung_und_neg_z-Richtung_verfahren" 8 "in_neg_x-Richtung_und_pos_z-Richtung_verfahren" ;
VAL_ 319 PreCrash_BFS_KSV_verfahren 0 "keine_Anforderung" 1 "in_pos_x-Richtung_verfahren" 2 "in_neg_x-Richung_verfahren" 3 "in_pos_z-Richtung_verfahren" 4 "in_neg_z-Richtung_verfahren" 5 "in_pos_x-Richtung_und_neg_z-Richtung_verfahren" 6 "in_pos_x_Richtung_und_pos_z-Richtung_verfahren" 7 "in_neg_x-Richtung_und_neg_z-Richtung_verfahren" 8 "in_neg_x-Richtung_und_pos_z-Richtung_verfahren" ;
VAL_ 319 PreCrash_Fo_KSV_verfahren 0 "keine_Anforderung" 1 "in_pos_x-Richtung_verfahren" 2 "in_neg_x-Richung_verfahren" 3 "in_pos_z-Richtung_verfahren" 4 "in_neg_z-Richtung_verfahren" 5 "in_pos_x-Richtung_und_neg_z-Richtung_verfahren" 6 "in_pos_x_Richtung_und_pos_z-Richtung_verfahren" 7 "in_neg_x-Richtung_und_neg_z-Richtung_verfahren" 8 "in_neg_x-Richtung_und_pos_z-Richtung_verfahren" ;
VAL_ 319 SC_PreCrash_Warnung 0 "keine_Anzeige" 1 "latente_Vorwarnung" 2 "Vorwarnung" 3 "Akutwarnung" 4 "Eingriff" 5 "Fahreruebernahmeaufforderung" 6 "Abbiegewarnung" 7 "Basiseingriff" 8 "Heckeingriff" ;
VAL_ 319 SC_PreCrash_Texte 0 "keine_Anzeige" 1 "Systemstoerung" 2 "keine_Sensorsicht" 3 "Demomodus" 4 "System_aus" 5 "Anhaengerbetrieb" 6 "ESC_aus" 7 "zurzeit_eingeschraenkt" 8 "zurzeit_eingeschraenkt_ESP_Aus" ;
VAL_ 1122 PSD_Segment_ID 0 "keine Segmentinformationen vorhanden" 1 "Fehlerwert" ;
VAL_ 1122 PSD_Vorgaenger_Segment_ID 0 "keine Segmentinformation vorhanden" 1 "Fehlerwert" ;
VAL_ 1122 PSD_Strassenkategorie 0 "Rest_Feldweg_Schotterweg_Privatweg" 1 "Ortsstraße" 2 "Kreisstraße" 3 "Landstraße" 4 "Bundesstraße" 5 "Autobahn" 7 "Init" ;
VAL_ 1122 PSD_Endkruemmung 255 "Gerade" ;
VAL_ 1122 PSD_Endkruemmung_Vorz 0 "Kruemmung_positiv" 1 "Kruemmung_negativ" ;
VAL_ 1122 PSD_Idenditaets_ID 0 "keine_Segment_Informationen_vorhanden" 1 "Fehler" ;
VAL_ 1122 PSD_ADAS_Qualitaet 0 "keine_ADAS_Qualitaet" 1 "ADAS_Qualitaet" ;
VAL_ 1122 PSD_wahrscheinlichster_Pfad 0 "Pfad_mit_geringer_Wahrscheinlichkeit" 1 "wahrscheinlichster_Pfad" ;
VAL_ 1122 PSD_Geradester_Pfad 0 "nicht_geradester_PFad" 1 "geradester_Pfad" ;
VAL_ 1122 PSD_Fahrspuren_Anzahl 0 "Einbahnstrasse_in_falsche_Richtung" 1 "eine_Fahrspur" 2 "zwei_Fahrspuren" 3 "drei_Fahrspuren" 4 "vier_Fahrspuren" 5 "fuenf_Fahrspuren" 6 "sechs_Fahrspuren" 7 "mehr_als_sechs_Fahrspuren" ;
VAL_ 1122 PSD_Bebauung 0 "ausserhalb_bebauten_Gebietes" 1 "innerhalb_bebauten_Gebietes" ;
VAL_ 1122 PSD_Segment_Komplett 0 "Segment_Attribute_nicht_komplett" 1 "Segment_Attribute_komplett" ;
VAL_ 1122 PSD_Rampe 0 "Strasse_mit_Gegenverkehr" 1 "Auffahrt_Einbahnstr" 2 "Abfahrt_Einbahnstr" 3 "Einbahnstrasse" ;
VAL_ 1122 PSD_Anfangskruemmung 255 "Gerade" ;
VAL_ 1122 PSD_Anfangskruemmung_Vorz 0 "positiv" 1 "negativ" ;
VAL_ 1122 PSD_Abzweigerichtung 0 "rects_abzweigende_Strasse" 1 "links_abzweigende_Strasse" ;
VAL_ 1123 PSD_Pos_Segment_ID 0 "keine Position gegeben" 1 "Fehlerwert" ;
VAL_ 1123 PSD_Pos_Standort_Eindeutig 0 "mehrdeutiger_Standort" 1 "eindeutiger_Standort" ;
VAL_ 1123 PSD_Pos_Fehler_Laengsrichtung 0 "Init" 1 "< 2m" 2 "< 5m" 3 "< 10m" 4 "< 20m" 5 "< 50m" 6 "> 50m" 7 "Off-Road" ;
VAL_ 1123 PSD_Pos_Fahrspur 0 "unbekannt" 1 "Erste_Spur_von_rechts" 2 "Zweite_Spur_von_rechts" 3 "Dritte_Spur_von_rechts" 4 "Vierte_Spur_von_rechts" 5 "Fuenfte_Spur_von_rechts" 6 "Sechte_Spur_von_rechts" 7 "Siebte_oder_weitere_Spur_von_rechts" ;
VAL_ 1123 PSD_Attribut_Segment_ID_05 0 "keine_Segment_Information" 1 "Fehler" ;
VAL_ 1123 PSD_Attribut_1_ID 0 "keine_Information" ;
VAL_ 1123 PSD_Attribut_2_ID 0 "keine_Information" ;
VAL_ 1123 PSD_Attribute_Komplett_05 0 "Attribute_nicht_komplett" 1 "Attribute_komplett" ;
VAL_ 1124 PSD_06_Mux 0 "Init" ;
VAL_ 1124 PSD_Sys_Segment_ID 0 "keine Segmentinformationen vorhanden" 1 "nicht zulaessig" ;
VAL_ 1124 PSD_Attribut_Segment_ID 0 "keine_Segment_Information_vorhanden" 1 "Fehler" ;
VAL_ 1124 PSD_Ges_Segment_ID 0 "keine Segmentinformationen vorhanden" 1 "nicht zulaessig" ;
VAL_ 1124 PSD_Baum_Laenge_VZ 0 "Ost" 1 "West" ;
VAL_ 1124 PSD_Steigung_1_Segment_ID 0 "keine_Segment_Information_vorhanden" 1 "Fehler" ;
VAL_ 1124 PSD_Baum_Laenge 33554431 "keine_GPS_Information" ;
VAL_ 1124 PSD_Attribut_3_ID 0 "keine_Information" ;
VAL_ 1124 PSD_Steigung_1_A_Steigung 126 "mehr_als_15_Prozent" 127 "Steigung_unbekannt" ;
VAL_ 1124 PSD_Ges_Geschwindigkeit 0 "Kein Geschwindigkeitsgebot" 1 "0 km/h < v_max <  5 km/h" 2 "5 km/h < v_max < 10km/h" 3 "10 km/h < v_max < 15 km/h" 4 "15 km/h < v_max < 20 km/h" 5 "20 km/h < v_max < 25 km/h" 6 "25 km/h < v_max < 30 km/h" 7 "30 km/h < v_max < 35 km/h" 8 "35 km/h < v_max < 40 km/h" 9 "40 km/h < v_max < 45 km/h" 10 "45 km/h < v_max < 50 km/h" 11 "50 km/h < v_max < 60 km/h" 12 "60 km/h < v_max < 70 km/h" 13 "70 km/h < v_max < 80 km/h" 14 "80 km/h < v_max < 90 km/h" 15 "90 km/h < v_max < 100 km/h" 16 "100 km/h < v_max < 110 km/h" 17 "110 km/h < v_max < 120 km/h" 18 " 120 km/h < v_max < 130 km/h" 19 "130 km/h < v_max < 140 km/h" 20 "140 km/h < v_max < 150 km/h" 21 "150 km/h < v_max < 160 km/h" 22 "160 km/h < v_max" 23 "Geschwindigkeitsgebot aufgehoben" 24 "..0x1F ungültig" ;
VAL_ 1124 PSD_Steigung_1_A_Vorz 0 "Gefaelle" 1 "Steigung" ;
VAL_ 1124 PSD_Sys_Geschwindigkeit_Einheit 0 "km/h" 1 "mph" ;
VAL_ 1124 PSD_Sys_Verkehrsrichtung 0 "Rechtsverkehr" 1 "Linksverkehr" ;
VAL_ 1124 PSD_Sys_Geometrieguete 0 "Geringe_Guete" 1 "tbd" 2 "tbd" 3 "Hohe_Guete" ;
VAL_ 1124 PSD_Sys_Mapmatchingguete 0 "geringe_Guete" 1 "res" 2 "res" 3 "hohe_Guete" ;
VAL_ 1124 PSD_Ges_Typ 0 "Geschw_Klasse_des_Kartendatensuppliers" 1 "Explizit_abgeleiteten_Begrenzung" 2 "Durch_Gesetzg_vorgeg_allgem_Gebot_fuer_uebertr_Rahmenbed" 3 "Init" ;
VAL_ 1124 PSD_Sys_Alter_Karte 0 "kleiner_1_Jahr" 1 "1_Jahr" 2 "2_Jahre" 3 "3_Jahre" 4 "4_Jahre" 5 "5_Jahre" 6 "6_Jahre" 7 "groesser_7_Jahre" ;
VAL_ 1124 PSD_Ges_Spur_Geschw_Begrenzung 0 "Gebot_fuer_alle_spuren_gueltig" ;
VAL_ 1124 PSD_Steigung_1_B_Steigung 126 "mehr_als_15_Prozent" 127 "Steigung_unbekannt" ;
VAL_ 1124 PSD_Attribut_4_ID 0 "keine_Information" ;
VAL_ 1124 PSD_Sys_Zielfuehrung 0 "Zielfuehrung nicht aktiv" 1 "Zielfuehrung aktiv" ;
VAL_ 1124 PSD_Sys_US_State 0 "kein_US_State" 1 "Alabama" 2 "Alaska" 3 "Arizona" 4 "Arkansas" 5 "California" 6 "Chihuahua" 7 "Colorado" 8 "Connecticut" 9 "Delaware" 10 "Florida" 11 "Georgia" 12 "Hawaii" 13 "Idaho" 14 "Illinois" 15 "Indiana" 16 "Iowa" 17 "Kansas" 18 "Kentucky" 19 "Louisiana" 20 "Maine" 21 "Maryland" 22 "Massachusetts" 23 "Michigan" 24 "Minnesota" 25 "Mississippi" 26 "Missouri" 27 "Montana" 28 "Nebraska" 29 "Nevada" 30 "New_Hampshire" 31 "New_Jersey" 32 "New_Mexico" 33 "New_York" 34 "North_Carolina" 35 "North_Dakota" 36 "Ohio" 37 "Oklahoma" 38 "Oregon" 39 "Pennsylvania" 40 "Rhode_Island" 41 "South_Carolina" 42 "South_Dakota" 43 "Tennessee" 44 "Texas" 45 "Utah" 46 "Vermont" 47 "Virginia" 48 "Washington" 49 "West_Virginia" 50 "Wisconsin" 51 "Wyoming" ;
VAL_ 1124 PSD_Ges_Geschwindigkeit_Gespann 0 "alle Fahrzeuge" 1 "PKW mit Gespann" 2 "LKW, Busse, etc." ;
VAL_ 1124 PSD_Baum_Breite_VZ 0 "Nord" 1 "Sued" ;
VAL_ 1124 PSD_Ges_Geschwindigkeit_Witter 0 "Witterungsunabhängig" 1 "Nässe, Regen, Niederschlag" 2 "Glätte" 3 "Nebel" ;
VAL_ 1124 PSD_Steigung_1_B_Vorz 0 "Gefaelle" 1 "Steigung" ;
VAL_ 1124 PSD_Ges_Geschwindigkeit_Tag_Anf 0 "kein Beginn definiert" 1 "Montag" 2 "Dienstag" 3 "Mittwoch" 4 "Donnerstag" 5 "Freitag" 6 "Samstag" 7 "Sonntag" ;
VAL_ 1124 PSD_Ges_Geschwindigkeit_Tag_Ende 0 "kein Ende definiert" 1 "Montag" 2 "Dienstag" 3 "Mittwoch" 4 "Donnerstag" 5 "Freitag" 6 "Samstag" 7 "Sonntag" ;
VAL_ 1124 PSD_Ges_Geschwindigkeit_Std_Anf 25 "kein Beginn für stundenweise Einschränkungen" ;
VAL_ 1124 PSD_Steigung_1_Attribute_kompl 0 "Steigungen_nicht_komplett" 1 "Steigungen_komplett" ;
VAL_ 1124 PSD_Steigung_2_Segment_ID 0 "keine_Segment_Information_vorhanden" 1 "Fehler" ;
VAL_ 1124 PSD_Attribut_5_ID 0 "keine_Information" ;
VAL_ 1124 PSD_Ges_Geschwindigkeit_Std_Ende 25 "kein Ende für stundenweise Einschränkungen" ;
VAL_ 1124 PSD_Steigung_2_Steigung 126 "mehr_als_15_Prozent" 127 "Steigung_unbekannt" ;
VAL_ 1124 PSD_Ges_Ueberholverbot 0 "kein Überholverbot" 1 "alle Fahrzeuge" 2 "Überholverbot für PKW mit Gespann" 3 "Überholverbot für LKW, Busse, etc." ;
VAL_ 1124 PSD_Ges_Wechselverkehrszeichen 0 "Kein Wechselverkehrszeichen" 1 "Wechselverkehrszeichen links" 2 "Wechselverkehrszeichen rechts" 3 "Wechselverkehrszeichen links und rechts" 4 "Wechselverkerhszeichen über der Fahrbahn" ;
VAL_ 1124 PSD_Steigung_2_Vorz 0 "Gefaelle" 1 "Steigung" ;
VAL_ 1124 PSD_Wechselverkehrszeichen_Typ 0 "kein_Wechselverkehrszeichen" 1 "LED_Wechselverkehrszeichen" 2 "nicht_LED_Wechselverkehrszeichen" ;
VAL_ 1124 PSD_Ges_Gesetzlich_Kategorie 0 "kein_legales_Verbot" 1 "innerorts" 2 "ausserorts" 3 "Autobahn" ;
VAL_ 1124 PSD_Attribute_Komplett_06 0 "Attribute_nicht_komplett" 1 "Attribute_komplett" ;
VAL_ 1124 PSD_Ges_Gesetzlich_Zusatz 0 "kein_Zusatz_zu_legalem_Gebot" 1 "Anhaenger_Klasse_1" 2 "Anhaenger_Klasse_2" ;
VAL_ 1124 PSD_Ges_Verkehrszeichen_Quelle 0 "VZA_kein_Onlinedienst" 1 "nur_VZA" 2 "nur_VZO" 3 "VZA_und_VZO" ;
VAL_ 1124 PSD_Steigung_2_Attribute_kompl 0 "Steigungen_nicht_komplett" 1 "Steigungen_komplett" ;
VAL_ 1124 PSD_Ges_Attribute_Komplett 0 "Attribute_nicht_komplett" 1 "Attribute_komplett" ;
